VERSION "ICM"

NS_ :

BS_ :

BU_ : ICM Vector_XXX

BO_ 1977 DIAG_CFCAN_DTCInfo_FICM : 7 ICM
 SG_ DTCInfomationFICM : 7|56@0+ (1,0) [0|72057594037927935] "" Vector_XXX

BO_ 1976 DIAG_CFCAN_DTCInfo_IPK : 7 ICM
 SG_ DTCInfomationIPK : 7|56@0+ (1,0) [0|72057594037927935] "" Vector_XXX

BO_ 1897 Diag_CFCAN_PhyResp_FICM : 8 ICM
 SG_ Diag_CFCAN_PhyResp_ICM : 7|64@0+ (1,0) [0|0] "" Vector_XXX

BO_ 1547 DIAG_PhysResp_VKR : 8 ICM
 SG_ DiagnosticRespVKR : 7|64@0+ (1,0) [0|18446744073709551615] "" Vector_XXX

BO_ 929 FICM_CFCAN_FrP01 : 8 ICM
 SG_ ACDrvrTemV : 63|1@0+ (1,0) [0|1] "" Vector_XXX
 SG_ ACPsngTemV : 62|1@0+ (1,0) [0|1] "" Vector_XXX
 SG_ CBDActvdSpdSetng : 11|4@0+ (10.0,0.0) [30.0|100.0] "km/h" Vector_XXX
 SG_ CBDSelReq : 23|2@0+ (1,0) [0|3] "" Vector_XXX
 SG_ CIASelReq : 21|2@0+ (1,0) [0|3] "" Vector_XXX
 SG_ CIASetSwReq : 19|2@0+ (1,0) [0|3] "" Vector_XXX
 SG_ CLAWrnngSndSwSetng : 27|2@0+ (1,0) [0|3] "" Vector_XXX
 SG_ CLWActdSpdSetng : 31|4@0+ (10.0,0.0) [30.0|100.0] "km/h" Vector_XXX
 SG_ CLWSelReq : 17|2@0+ (1,0) [0|3] "" Vector_XXX
 SG_ FICMBrkLghtReqV : 59|1@0+ (1,0) [0|1] "" Vector_XXX
 SG_ FICMFLSeatVentSwReq : 51|2@0+ (1,0) [0|3] "" Vector_XXX
 SG_ FICMFRSeatVentSwReq : 49|2@0+ (1,0) [0|3] "" Vector_XXX
 SG_ LowSpdAutocOpenAVMReq : 33|2@0+ (1,0) [0|3] "" Vector_XXX
 SG_ RrViewInfoAstntActvdSpdSetng : 39|4@0+ (10.0,0.0) [30.0|100.0] "km/h" Vector_XXX
 SG_ RrViewInfoAstntDspSwReq : 25|2@0+ (1,0) [0|3] "" Vector_XXX
 SG_ RrViewInfoAstntSelReq : 35|2@0+ (1,0) [0|3] "" Vector_XXX
 SG_ VehBodyColorReq : 47|4@0+ (1,0) [0|15] "" Vector_XXX

BO_ 907 FICM_CFCAN_FrP02 : 8 ICM
 SG_ ACAirQultCtrlEnbSwReq : 7|2@0+ (1,0) [0|3] "" Vector_XXX
 SG_ ACEcoSwReq : 2|2@0+ (1,0) [0|3] "" Vector_XXX
 SG_ ACFltrCsumLvlRstSwReq : 15|2@0+ (1,0) [0|3] "" Vector_XXX
 SG_ ACFrtBlwrLvlReqV : 0|1@0+ (1,0) [0|1] "" Vector_XXX
 SG_ ACRrAirMdSwReq : 12|2@0+ (1,0) [0|3] "" Vector_XXX
 SG_ ACUserCustEcoSetngReq : 10|2@0+ (1,0) [0|3] "" Vector_XXX
 SG_ ACUserCustEcoSetngReqV : 8|1@0+ (1,0) [0|1] "" Vector_XXX
 SG_ FICMACAutoSwReq : 23|2@0+ (1,0) [0|3] "" Vector_XXX
 SG_ FICMACDualSwReq : 19|2@0+ (1,0) [0|3] "" Vector_XXX
 SG_ FICMACFreshSwReq : 33|2@0+ (1,0) [0|3] "" Vector_XXX
 SG_ FICMACFrtBlwrLvlReq : 39|4@0+ (1,0) [0|15] "" Vector_XXX
 SG_ FICMACFrtBlwrSpdDecSwR : 35|2@0+ (1,0) [0|3] "" Vector_XXX
 SG_ FICMACFrtBlwrSpdIncSwR : 47|2@0+ (1,0) [0|3] "" Vector_XXX
 SG_ FICMACFrtPnlLckRrPnlSwReq : 45|2@0+ (1,0) [0|3] "" Vector_XXX
 SG_ FICMACIonizerReqSwReq : 59|2@0+ (1,0) [0|3] "" Vector_XXX
 SG_ FICMACLAirMdReq : 26|3@0+ (1,0) [0|7] "" Vector_XXX
 SG_ FICMACLAirMdReqV : 41|1@0+ (1,0) [0|1] "" Vector_XXX
 SG_ FICMACLAirMdSwReq : 5|2@0+ (1,0) [0|3] "" Vector_XXX
 SG_ FICMACLTemDecSwReq : 17|2@0+ (1,0) [0|3] "" Vector_XXX
 SG_ FICMACLTemIncSwReq : 21|2@0+ (1,0) [0|3] "" Vector_XXX
 SG_ FICMACLTemReq : 31|5@0+ (0.5,17.5) [18.0|32.0] "degC" Vector_XXX
 SG_ FICMACLTemV : 3|1@0+ (1,0) [0|1] "" Vector_XXX
 SG_ FICMACOnOffSwReq : 54|2@0+ (1,0) [0|3] "" Vector_XXX
 SG_ FICMACRAirMdReq : 52|3@0+ (1,0) [0|7] "" Vector_XXX
 SG_ FICMACRAirMdReqV : 40|1@0+ (1,0) [0|1] "" Vector_XXX
 SG_ FICMACRAirMdSwReq : 49|2@0+ (1,0) [0|3] "" Vector_XXX
 SG_ FICMACRcctnSwReq : 57|2@0+ (1,0) [0|3] "" Vector_XXX
 SG_ FICMACRTemDecSwReq : 63|2@0+ (1,0) [0|3] "" Vector_XXX
 SG_ FICMACRTemIncSwReq : 61|2@0+ (1,0) [0|3] "" Vector_XXX
 SG_ FICMACSyncSwReq : 43|2@0+ (1,0) [0|3] "" Vector_XXX

BO_ 911 FICM_CFCAN_FrP03 : 8 ICM
 SG_ FICMACFrtPnlDspRrPnlSwReq : 47|2@0+ (1,0) [0|3] "" Vector_XXX
 SG_ FICMACRrAirMdReq : 2|3@0+ (1,0) [0|7] "" Vector_XXX
 SG_ FICMACRrAirMdReqV : 10|1@0+ (1,0) [0|1] "" Vector_XXX
 SG_ FICMACRrBlwrDecSwReq : 17|2@0+ (1,0) [0|3] "" Vector_XXX
 SG_ FICMACRrBlwrIncSwReq : 19|2@0+ (1,0) [0|3] "" Vector_XXX
 SG_ FICMACRrBlwrLvlReq : 31|4@0+ (1,0) [0|15] "" Vector_XXX
 SG_ FICMACRrBlwrLvlReqV : 9|1@0+ (1,0) [0|1] "" Vector_XXX
 SG_ FICMACRrTemDecSwReq : 27|2@0+ (1,0) [0|3] "" Vector_XXX
 SG_ FICMACRrTemIncSwReq : 25|2@0+ (1,0) [0|3] "" Vector_XXX
 SG_ FICMACRrTemReq : 15|5@0+ (0.5,17.5) [18.0|32.0] "degC" Vector_XXX
 SG_ FICMACRrTemV : 8|1@0+ (1,0) [0|1] "" Vector_XXX
 SG_ FICMACRTemReq : 7|5@0+ (0.5,17.5) [18.0|32.0] "degC" Vector_XXX
 SG_ FICMACRTemV : 40|1@0+ (1,0) [0|1] "" Vector_XXX
 SG_ FICMACTemUnitChngReq : 39|2@0+ (1,0) [0|3] "" Vector_XXX
 SG_ FICMClmOnOffSwReq : 37|2@0+ (1,0) [0|3] "" Vector_XXX
 SG_ FICMComprOnOffSwReq : 35|2@0+ (1,0) [0|3] "" Vector_XXX
 SG_ FICMDfstOnSwReq : 33|2@0+ (1,0) [0|3] "" Vector_XXX
 SG_ FICMRrACAutoSwReq : 23|2@0+ (1,0) [0|3] "" Vector_XXX
 SG_ FICMRrACOnOffSwReq : 21|2@0+ (1,0) [0|3] "" Vector_XXX
 SG_ PwrLftgtPosSetngReq : 63|7@0+ (0.787402,0.0) [0.0|100.000054] "%" Vector_XXX
 SG_ PwrLftgtPosSetngReqV : 48|1@0+ (1,0) [0|1] "" Vector_XXX
 SG_ PwrLftgtSysEnb : 56|1@0+ (1,0) [0|1] "" Vector_XXX
 SG_ StrgCDMSSetngReq : 55|7@0+ (1,0) [0|127] "" Vector_XXX
 SG_ StrgCDMSSetngReqV : 41|1@0+ (1,0) [0|1] "" Vector_XXX

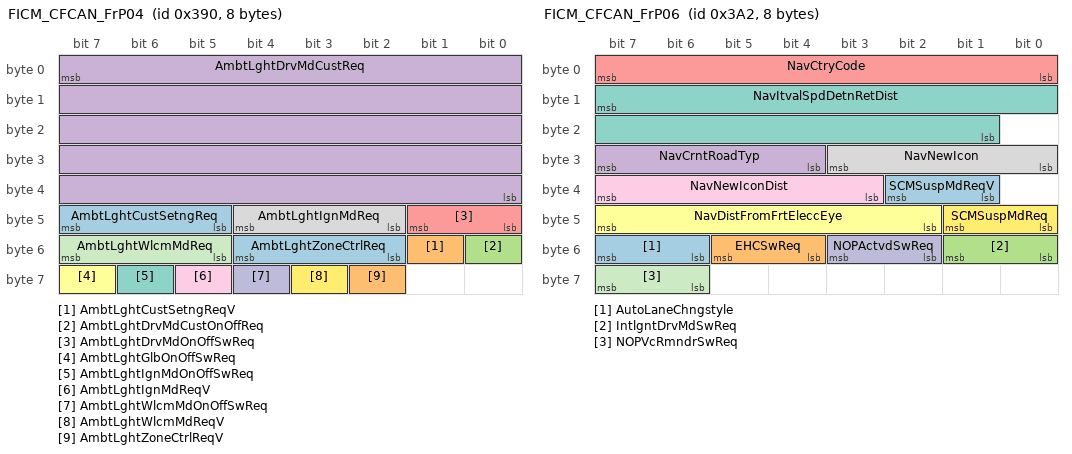
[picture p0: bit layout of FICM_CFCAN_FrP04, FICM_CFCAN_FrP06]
BO_ 912 FICM_CFCAN_FrP04 : 8 ICM
 SG_ AmbtLghtCustSetngReq : 47|3@0+ (1,0) [0|7] "" Vector_XXX
 SG_ AmbtLghtCustSetngReqV : 49|1@0+ (1,0) [0|1] "" Vector_XXX
 SG_ AmbtLghtDrvMdCustOnOffReq : 48|1@0+ (1,0) [0|1] "" Vector_XXX
 SG_ AmbtLghtDrvMdCustReq : 7|40@0+ (1,0) [0|1099511627775] "" Vector_XXX
 SG_ AmbtLghtDrvMdOnOffSwReq : 41|2@0+ (1,0) [0|3] "" Vector_XXX
 SG_ AmbtLghtGlbOnOffSwReq : 63|1@0+ (1,0) [0|1] "" Vector_XXX
 SG_ AmbtLghtIgnMdOnOffSwReq : 62|1@0+ (1,0) [0|1] "" Vector_XXX
 SG_ AmbtLghtIgnMdReq : 44|3@0+ (1,0) [0|7] "" Vector_XXX
 SG_ AmbtLghtIgnMdReqV : 61|1@0+ (1,0) [0|1] "" Vector_XXX
 SG_ AmbtLghtWlcmMdOnOffSwReq : 60|1@0+ (1,0) [0|1] "" Vector_XXX
 SG_ AmbtLghtWlcmMdReq : 55|3@0+ (1,0) [0|7] "" Vector_XXX
 SG_ AmbtLghtWlcmMdReqV : 59|1@0+ (1,0) [0|1] "" Vector_XXX
 SG_ AmbtLghtZoneCtrlReq : 52|3@0+ (1,0) [0|7] "" Vector_XXX
 SG_ AmbtLghtZoneCtrlReqV : 58|1@0+ (1,0) [0|1] "" Vector_XXX

BO_ 875 FICM_CFCAN_FrP05 : 8 ICM
 SG_ FaceIdficnAcutResult : 55|5@0+ (1,0) [0|31] "" Vector_XXX
 SG_ FICMDoorLckCtrlReq : 7|2@0+ (1,0) [0|3] "" Vector_XXX
 SG_ FICMDrvngMdSwReq : 50|3@0+ (1,0) [0|7] "" Vector_XXX
 SG_ FICMDrvngMdSwReqV : 43|1@0+ (1,0) [0|1] "" Vector_XXX
 SG_ FICMDrvrWndOpReq : 5|3@0+ (1,0) [0|7] "" Vector_XXX
 SG_ FICMFrtPsngWndOpReq : 2|3@0+ (1,0) [0|7] "" Vector_XXX
 SG_ FICMFrtWiperReq : 15|3@0+ (1,0) [0|7] "" Vector_XXX
 SG_ FICMFrtWshReq : 12|1@0+ (1,0) [0|1] "" Vector_XXX
 SG_ FICMHtdRrWndSwReq : 11|2@0+ (1,0) [0|3] "" Vector_XXX
 SG_ FICMKickSnsrLdspcEnbdReq : 9|2@0+ (1,0) [0|3] "" Vector_XXX
 SG_ FICMLdspcUnlckReq : 47|1@0+ (1,0) [0|1] "" Vector_XXX
 SG_ FICMOtsdMirFoldReq : 17|2@0+ (1,0) [0|3] "" Vector_XXX
 SG_ FICMRLWndOpReq : 23|3@0+ (1,0) [0|7] "" Vector_XXX
 SG_ FICMRrWiperReq : 39|2@0+ (1,0) [0|3] "" Vector_XXX
 SG_ FICMRRWndOpReq : 20|3@0+ (1,0) [0|7] "" Vector_XXX
 SG_ FICMRrWshReq : 46|1@0+ (1,0) [0|1] "" Vector_XXX
 SG_ FICMSrfSlidePosReq : 31|4@0+ (10.0,0.0) [0.0|150.0] "%" Vector_XXX
 SG_ FICMSrfTiltReq : 37|2@0+ (1,0) [0|3] "" Vector_XXX
 SG_ FICMSsdOpenPosReq : 27|4@0+ (10.0,0.0) [0.0|150.0] "%" Vector_XXX
 SG_ FICMVehStSpReq : 35|2@0+ (1,0) [0|3] "" Vector_XXX
 SG_ FICMVehStSpReqV : 45|1@0+ (1,0) [0|1] "" Vector_XXX
 SG_ FICMWiperOffReq : 44|1@0+ (1,0) [0|1] "" Vector_XXX
 SG_ FICMWiperSpdCtrlReq : 33|2@0+ (1,0) [0|3] "" Vector_XXX
 SG_ StorgMdSwReq : 63|2@0+ (1,0) [0|3] "" Vector_XXX
 SG_ WlcmFnCustSetngReq : 42|2@0+ (1,0) [0|3] "" Vector_XXX

BO_ 930 FICM_CFCAN_FrP06 : 8 ICM
 SG_ AutoLaneChngstyle : 55|2@0+ (1,0) [0|3] "" Vector_XXX
 SG_ EHCSwReq : 53|2@0+ (1,0) [0|3] "" Vector_XXX
 SG_ IntlgntDrvMdSwReq : 49|2@0+ (1,0) [0|3] "" Vector_XXX
 SG_ NavCrntRoadTyp : 31|4@0+ (1,0) [0|15] "" Vector_XXX
 SG_ NavCtryCode : 7|8@0+ (1.0,0.0) [0.0|255.0] "" Vector_XXX
 SG_ NavDistFromFrtEleccEye : 47|6@0+ (0.1,0.0) [0.1|6.0] "" Vector_XXX
 SG_ NavItvalSpdDetnRetDist : 15|15@0+ (0.1,0.0) [0.1|20.0] "" Vector_XXX
 SG_ NavNewIcon : 27|4@0+ (1,0) [0|15] "" Vector_XXX
 SG_ NavNewIconDist : 39|5@0+ (0.1,0.0) [0.1|2.0] "" Vector_XXX
 SG_ NOPActvdSwReq : 51|2@0+ (1,0) [0|3] "" Vector_XXX
 SG_ NOPVcRmndrSwReq : 63|2@0+ (1,0) [0|3] "" Vector_XXX
 SG_ SCMSuspMdReq : 41|2@0+ (1,0) [0|3] "" Vector_XXX
 SG_ SCMSuspMdReqV : 34|2@0+ (1,0) [0|3] "" Vector_XXX

BO_ 931 FICM_CFCAN_FrP07 : 8 ICM
 SG_ FICM_100ms_PDU07_CRC : 7|8@0+ (1.0,0.0) [0.0|255.0] "" Vector_XXX
 SG_ FICM_100ms_PDU07_RC : 11|4@0+ (1.0,0.0) [0.0|15.0] "" Vector_XXX
 SG_ FICM_100ms_PDU07_Reserve01 : 56|1@0+ (1,0) [0|1] "" Vector_XXX
 SG_ FICMEcoDrvngSwA : 39|1@0+ (1,0) [0|1] "" Vector_XXX
 SG_ FICMEcoDrvngSwAV : 38|1@0+ (1,0) [0|1] "" Vector_XXX
 SG_ FICMPosngSysDircn : 32|9@0+ (1.0,0.0) [0.0|511.0] "" Vector_XXX
 SG_ LDWLKASwReq : 29|3@0+ (1,0) [0|7] "" Vector_XXX
 SG_ NavSpdLmtTyp : 23|4@0+ (1,0) [0|15] "" Vector_XXX
 SG_ NavSpdLmtVal : 55|15@0+ (0.015625,0.0) [0.0|511.984375] "" Vector_XXX
 SG_ NavSpdLmtValSts : 19|2@0+ (1,0) [0|3] "" Vector_XXX
 SG_ NavSpdLmtValUnit : 17|2@0+ (1,0) [0|3] "" Vector_XXX
 SG_ PtCustSetngReq : 37|3@0+ (1,0) [0|7] "" Vector_XXX
 SG_ PtCustSetngReqV : 34|1@0+ (1,0) [0|1] "" Vector_XXX
 SG_ SpdAstMdFICM : 26|2@0+ (1,0) [0|3] "" Vector_XXX
 SG_ SpdAstMdFICMV : 24|1@0+ (1,0) [0|1] "" Vector_XXX
 SG_ StrgCustSetngReq : 31|2@0+ (1,0) [0|3] "" Vector_XXX
 SG_ StrgCustSetngReqV : 12|1@0+ (1,0) [0|1] "" Vector_XXX
 SG_ TrCustSetngReq : 15|3@0+ (1,0) [0|7] "" Vector_XXX
 SG_ TrCustSetngReqV : 33|1@0+ (1,0) [0|1] "" Vector_XXX

BO_ 902 FICM_CFCAN_FrP08 : 8 ICM
 SG_ BCMCofignUpdtInftn2 : 7|64@0+ (1,0) [0|18446744073709551615] "" Vector_XXX

BO_ 903 FICM_CFCAN_FrP09 : 8 ICM
 SG_ BCMCofignUpdtInftn3 : 7|64@0+ (1,0) [0|18446744073709551615] "" Vector_XXX

BO_ 913 FICM_CFCAN_FrP10 : 8 ICM
 SG_ ACUserCustSetngReq : 39|2@0+ (1,0) [0|3] "" Vector_XXX
 SG_ ACUserCustSetngReqV : 24|1@0+ (1,0) [0|1] "" Vector_XXX
 SG_ FICMACDrvrAirMdReq : 50|3@0+ (1,0) [0|7] "" Vector_XXX
 SG_ FICMACDrvrAirMdReqV : 40|1@0+ (1,0) [0|1] "" Vector_XXX
 SG_ FICMACDrvrTemReq : 55|5@0+ (1,0) [0|31] "" Vector_XXX
 SG_ FICMACPsngAirMdSwReq : 33|2@0+ (1,0) [0|3] "" Vector_XXX
 SG_ FICMACPsngTemReq : 47|5@0+ (1,0) [0|31] "" Vector_XXX
 SG_ FICMAirClnrBlwrLvlReq : 21|3@0+ (1,0) [0|7] "" Vector_XXX
 SG_ FICMAirClnrBlwrLvlReqV : 18|1@0+ (1,0) [0|1] "" Vector_XXX
 SG_ FICMAirClnrBlwrSpdDecSwReq : 17|2@0+ (1,0) [0|3] "" Vector_XXX
 SG_ FICMAirClnrBlwrSpdIncSwReq : 31|2@0+ (1,0) [0|3] "" Vector_XXX
 SG_ FICMASSInhSwA : 37|1@0+ (1,0) [0|1] "" Vector_XXX
 SG_ FICMASSInhV : 36|1@0+ (1,0) [0|1] "" Vector_XXX
 SG_ FICMBrkLghtReq : 7|2@0+ (1,0) [0|3] "" Vector_XXX
 SG_ FICMCotsyLghtReq : 5|2@0+ (1,0) [0|3] "" Vector_XXX
 SG_ FICMDipdBeamLghtReq : 3|2@0+ (1,0) [0|3] "" Vector_XXX
 SG_ FICMDipdBeamLghtReqV : 12|1@0+ (1,0) [0|1] "" Vector_XXX
 SG_ FICMDircnIndLghtReq : 15|3@0+ (1,0) [0|7] "" Vector_XXX
 SG_ FICMFLSeatHeatSwReq : 29|2@0+ (1,0) [0|3] "" Vector_XXX
 SG_ FICMFRSeatHeatSwReq : 27|2@0+ (1,0) [0|3] "" Vector_XXX
 SG_ FICMFrtFogLghtReq : 1|2@0+ (1,0) [0|3] "" Vector_XXX
 SG_ FICMMainBeamLghtReq : 11|2@0+ (1,0) [0|3] "" Vector_XXX
 SG_ FICMRevsLghtReq : 9|2@0+ (1,0) [0|3] "" Vector_XXX
 SG_ FICMRrFogLghtReq : 23|2@0+ (1,0) [0|3] "" Vector_XXX
 SG_ HDCReq : 35|2@0+ (1,0) [0|3] "" Vector_XXX
 SG_ RstrFctryDeftsReq : 25|1@0+ (1,0) [0|1] "" Vector_XXX

BO_ 1121 FICM_CFCAN_FrP11 : 8 ICM
 SG_ BCMCofignUpdtInftn : 7|64@0+ (1,0) [0|18446744073709551615] "" Vector_XXX

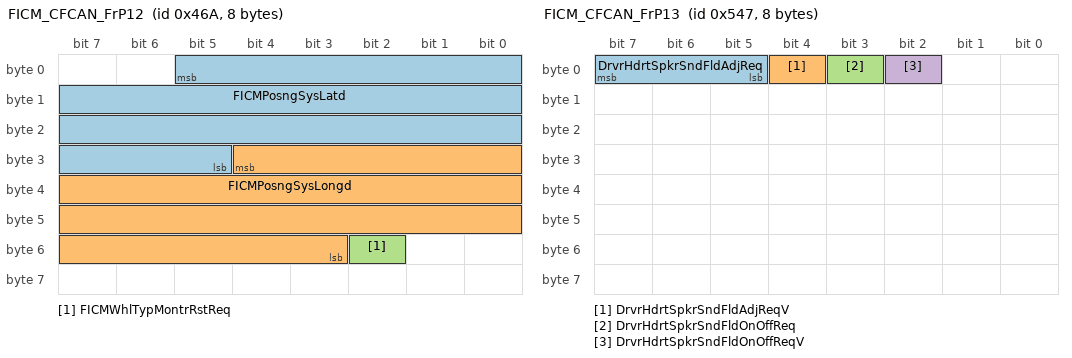
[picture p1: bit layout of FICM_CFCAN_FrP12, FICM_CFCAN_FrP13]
BO_ 1130 FICM_CFCAN_FrP12 : 8 ICM
 SG_ FICMPosngSysLatd : 5|25@0- (0.00001,0.0) [-90.00000000000001|90.00000000000001] "degree" Vector_XXX
 SG_ FICMPosngSysLongd : 28|26@0- (0.00001,0.0) [-335.54400000000004|335.54400000000004] "degree" Vector_XXX
 SG_ FICMWhlTypMontrRstReq : 50|1@0+ (1,0) [0|1] "" Vector_XXX

BO_ 1351 FICM_CFCAN_FrP13 : 8 ICM
 SG_ DrvrHdrtSpkrSndFldAdjReq : 7|3@0+ (1,0) [0|7] "" Vector_XXX
 SG_ DrvrHdrtSpkrSndFldAdjReqV : 4|1@0+ (1,0) [0|1] "" Vector_XXX
 SG_ DrvrHdrtSpkrSndFldOnOffReq : 3|1@0+ (1,0) [0|1] "" Vector_XXX
 SG_ DrvrHdrtSpkrSndFldOnOffReqV : 2|1@0+ (1,0) [0|1] "" Vector_XXX

BO_ 1352 FICM_CFCAN_FrP14 : 8 ICM
 SG_ NavSts : 7|3@0+ (1,0) [0|7] "" Vector_XXX

BO_ 820 FICM_CFCAN_FrP15 : 8 ICM
 SG_ ACUserCustAftRunOnOffR : 7|1@0+ (1,0) [0|1] "" Vector_XXX
 SG_ ACUserCustAftRunOnOffReqV : 6|1@0+ (1,0) [0|1] "" Vector_XXX
 SG_ ACUserCustAirQultEnbReq : 5|2@0+ (1,0) [0|3] "" Vector_XXX
 SG_ ACUserCustAirQultEnbReqV : 3|1@0+ (1,0) [0|1] "" Vector_XXX
 SG_ ACUserCustAutoMdBlwrReq : 2|2@0+ (1,0) [0|3] "" Vector_XXX
 SG_ ACUserCustAutoMdBlwrReqV : 0|1@0+ (1,0) [0|1] "" Vector_XXX
 SG_ ACUserCustAutoMdTemReq : 15|2@0+ (1,0) [0|3] "" Vector_XXX
 SG_ ACUserCustAutoMdTemReqV : 13|1@0+ (1,0) [0|1] "" Vector_XXX
 SG_ ACUserCustBlwrAutoRunRmtUnlckReq : 9|1@0+ (1,0) [0|1] "" Vector_XXX
 SG_ ACUserCustBlwrAutoRunRmtUnlckReqV : 10|1@0+ (1,0) [0|1] "" Vector_XXX
 SG_ ACUserCustCofignReq : 23|2@0+ (1,0) [0|3] "" Vector_XXX
 SG_ ACUserCustCofignReqV : 8|1@0+ (1,0) [0|1] "" Vector_XXX
 SG_ ACUserCustFltrLifeRmndReq : 21|1@0+ (1,0) [0|1] "" Vector_XXX
 SG_ ACUserCustFltrLifeRmndReqV : 20|1@0+ (1,0) [0|1] "" Vector_XXX
 SG_ ACUserCustFrtAutoDmstngReq : 19|1@0+ (1,0) [0|1] "" Vector_XXX
 SG_ ACUserCustFrtAutoDmstngReqV : 18|1@0+ (1,0) [0|1] "" Vector_XXX
 SG_ ACUserCustRmtStOnOffReq : 17|1@0+ (1,0) [0|1] "" Vector_XXX
 SG_ ACUserCustRmtStOnOffReqV : 16|1@0+ (1,0) [0|1] "" Vector_XXX
 SG_ ACUserCustRrAutoDmstngReq : 31|2@0+ (1,0) [0|3] "" Vector_XXX
 SG_ ACUserCustRrAutoDmstngReqV : 29|1@0+ (1,0) [0|1] "" Vector_XXX
 SG_ ACUserCustRrZoneCofignReq : 28|2@0+ (1,0) [0|3] "" Vector_XXX
 SG_ ACUserCustRrZoneCofignReqV : 26|1@0+ (1,0) [0|1] "" Vector_XXX
 SG_ ACUserCustStSpMdReq : 25|1@0+ (1,0) [0|1] "" Vector_XXX
 SG_ ACUserCustStSpMdReqV : 24|1@0+ (1,0) [0|1] "" Vector_XXX
 SG_ ACUserCustTemUnitReq : 39|1@0+ (1,0) [0|1] "" Vector_XXX
 SG_ ACUserCustTemUnitReqV : 38|1@0+ (1,0) [0|1] "" Vector_XXX
 SG_ ACUserCustZoneCofignReq : 37|2@0+ (1,0) [0|3] "" Vector_XXX
 SG_ ACUserCustZoneCofignReqV : 35|1@0+ (1,0) [0|1] "" Vector_XXX
 SG_ AirClnrUserCustAutoRR : 34|1@0+ (1,0) [0|1] "" Vector_XXX
 SG_ AirClnrUserCustAutoRRV : 33|1@0+ (1,0) [0|1] "" Vector_XXX
 SG_ FICMAirClnrAutoSwReq : 12|2@0+ (1,0) [0|3] "" Vector_XXX
 SG_ FICMAirClnrFltrCsumLvlRstSwReq : 47|2@0+ (1,0) [0|3] "" Vector_XXX
 SG_ FICMAirClnrIonizerSwR : 45|2@0+ (1,0) [0|3] "" Vector_XXX
 SG_ FICMAirClnrOnOffSwReq : 43|2@0+ (1,0) [0|3] "" Vector_XXX
 SG_ InsdAirPrtclMtrCncntrnSwReq : 41|2@0+ (1,0) [0|3] "" Vector_XXX

BO_ 690 FICM_CFCAN_FrP16 : 8 ICM
 SG_ AncptRoadSpdNav : 23|15@0+ (0.015625,0.0) [0.0|511.984375] "" Vector_XXX
 SG_ APASwReq : 33|2@0+ (1,0) [0|3] "" Vector_XXX
 SG_ AVMCalMdReq : 7|2@0+ (1,0) [0|3] "" Vector_XXX
 SG_ DistToTrgtNav : 39|6@0+ (9.375,-100.0) [-100.0|490.625] "m" Vector_XXX
 SG_ FICMCCSwCCA : 46|1@0+ (1,0) [0|1] "" Vector_XXX
 SG_ FICMCCSwCCAV : 45|1@0+ (1,0) [0|1] "" Vector_XXX
 SG_ FrtAndRrGudOvlyDspReq : 5|3@0+ (1,0) [0|7] "" Vector_XXX
 SG_ LOtsdMirSeldSwA : 42|1@0+ (1,0) [0|1] "" Vector_XXX
 SG_ OtsdMirFoldSwReq : 44|2@0+ (1,0) [0|3] "" Vector_XXX
 SG_ OtsdMirSWSFnA : 40|1@0+ (1,0) [0|1] "" Vector_XXX
 SG_ PDCSwReq : 2|2@0+ (1,0) [0|3] "" Vector_XXX
 SG_ PDCSysEnbReq : 0|1@0+ (1,0) [0|1] "" Vector_XXX
 SG_ PDCSysEnbReqV : 24|1@0+ (1,0) [0|1] "" Vector_XXX
 SG_ ROtsdMirSeldSwA : 41|1@0+ (1,0) [0|1] "" Vector_XXX
 SG_ SpdAstReqStsNav : 9|2@0+ (1,0) [0|3] "" Vector_XXX
 SG_ SurndViewSeln : 15|4@0+ (1,0) [0|15] "" Vector_XXX
 SG_ ThreeDimnlDspReq : 11|2@0+ (1,0) [0|3] "" Vector_XXX
 SG_ TrgtSpdReqNav : 55|15@0+ (0.015625,0.0) [0.0|511.984375] "" Vector_XXX

BO_ 895 FICM_CFCAN_FrP17 : 8 ICM
 SG_ ACCTJAMdSwReq : 23|3@0+ (1,0) [0|7] "" Vector_XXX
 SG_ AEBSwReq : 28|2@0+ (1,0) [0|3] "" Vector_XXX
 SG_ AutoLaneChngSwReq : 39|3@0+ (1,0) [0|7] "" Vector_XXX
 SG_ BSDSelReq : 5|2@0+ (1,0) [0|3] "" Vector_XXX
 SG_ DOWSelReq : 3|2@0+ (1,0) [0|3] "" Vector_XXX
 SG_ FCTSysSelReq : 50|2@0+ (1,0) [0|3] "" Vector_XXX
 SG_ FCWSnstvtLvlReq : 31|3@0+ (1,0) [0|7] "" Vector_XXX
 SG_ FCWSwReq : 13|2@0+ (1,0) [0|3] "" Vector_XXX
 SG_ FICMSCSMdReq : 26|2@0+ (1,0) [0|3] "" Vector_XXX
 SG_ LCASelReq : 11|2@0+ (1,0) [0|3] "" Vector_XXX
 SG_ LDWAdoWrnngReq : 45|2@0+ (1,0) [0|3] "" Vector_XXX
 SG_ LDWLKAHptWrnngReq : 1|2@0+ (1,0) [0|3] "" Vector_XXX
 SG_ LDWSnstvtLvlReq : 43|2@0+ (1,0) [0|3] "" Vector_XXX
 SG_ NOPSwReq : 63|3@0+ (1,0) [0|7] "" Vector_XXX
 SG_ RCTSysSelReq : 41|2@0+ (1,0) [0|3] "" Vector_XXX
 SG_ RCWSelReq : 19|2@0+ (1,0) [0|3] "" Vector_XXX
 SG_ RDASwReq : 9|2@0+ (1,0) [0|3] "" Vector_XXX
 SG_ SLIFWrnngStsReq : 47|1@0+ (1,0) [0|1] "" Vector_XXX
 SG_ SLIFWrnngStsReqV : 46|1@0+ (1,0) [0|1] "" Vector_XXX
 SG_ TJAICASwReq : 17|2@0+ (1,0) [0|3] "" Vector_XXX

BO_ 1347 FICM_CFCAN_FrP18 : 8 ICM
 SG_ LanggSetngAdj : 55|7@0+ (1,0) [0|127] "" Vector_XXX

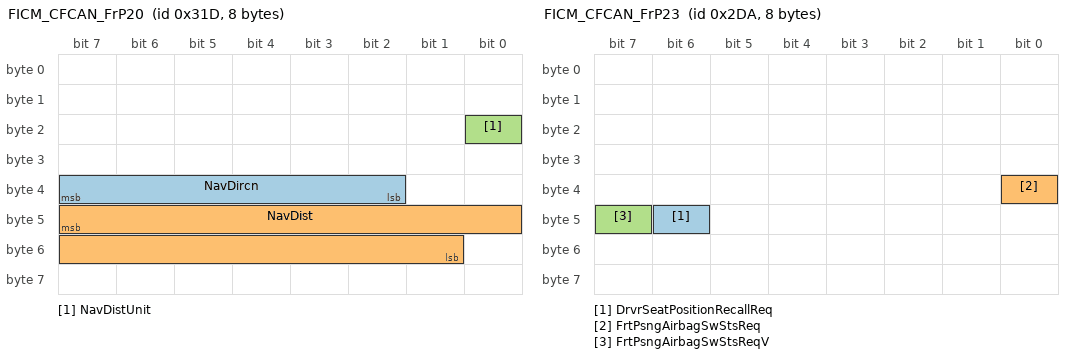
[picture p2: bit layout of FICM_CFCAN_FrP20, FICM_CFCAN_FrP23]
BO_ 797 FICM_CFCAN_FrP20 : 8 ICM
 SG_ NavDircn : 39|6@0+ (1,0) [0|63] "" Vector_XXX
 SG_ NavDist : 47|15@0+ (1.0,0.0) [0.0|32766.0] "" Vector_XXX
 SG_ NavDistUnit : 16|1@0+ (1,0) [0|1] "" Vector_XXX

BO_ 730 FICM_CFCAN_FrP23 : 8 ICM
 SG_ DrvrSeatPositionRecallReq : 46|1@0+ (1,0) [0|1] "" Vector_XXX
 SG_ FrtPsngAirbagSwStsReq : 32|1@0+ (1,0) [0|1] "" Vector_XXX
 SG_ FrtPsngAirbagSwStsReqV : 47|1@0+ (1,0) [0|1] "" Vector_XXX

BO_ 767 FICM_CFCAN_FrP28 : 8 ICM
 SG_ AVMDspReqResp : 37|2@0+ (1,0) [0|3] "" Vector_XXX
 SG_ AVMDspSwReq : 35|2@0+ (1,0) [0|3] "" Vector_XXX
 SG_ BleCmftLckSet : 33|2@0+ (1,0) [0|3] "" Vector_XXX
 SG_ BleCmftUnlckSet : 31|2@0+ (1,0) [0|3] "" Vector_XXX
 SG_ BleWlcmFnSet : 29|2@0+ (1,0) [0|3] "" Vector_XXX
 SG_ CCDisAdjtVcCmd : 63|3@0+ (1,0) [0|7] "" Vector_XXX
 SG_ CCDisDecAndIncVcCmd : 60|2@0+ (1,0) [0|3] "" Vector_XXX
 SG_ CCSpdDecAndIncVcCmd : 58|2@0+ (1,0) [0|3] "" Vector_XXX
 SG_ CCSpdVcCmd : 55|8@0+ (1.0,0.0) [0.0|255.0] "" Vector_XXX
 SG_ CCSpdVcCmdSwReq : 47|2@0+ (1,0) [0|3] "" Vector_XXX
 SG_ DMSAdoWrnngReq : 23|2@0+ (1,0) [0|3] "" Vector_XXX
 SG_ DMSHapticWrnngReq : 21|2@0+ (1,0) [0|3] "" Vector_XXX
 SG_ DMSSwReq : 19|2@0+ (1,0) [0|3] "" Vector_XXX
 SG_ DrvrVcCmdADASCtrlReq : 7|3@0+ (1,0) [0|7] "" Vector_XXX
 SG_ ILCSwReq : 45|2@0+ (1,0) [0|3] "" Vector_XXX
 SG_ PhnKeyCphrUpdt : 27|2@0+ (1,0) [0|3] "" Vector_XXX
 SG_ PhnKeyRst : 25|2@0+ (1,0) [0|3] "" Vector_XXX
 SG_ SmtKeyCmftLckSet : 43|2@0+ (1,0) [0|3] "" Vector_XXX
 SG_ SmtKeyCmftUnlckSet : 41|2@0+ (1,0) [0|3] "" Vector_XXX
 SG_ SmtKeyWlcmFnSet : 39|2@0+ (1,0) [0|3] "" Vector_XXX

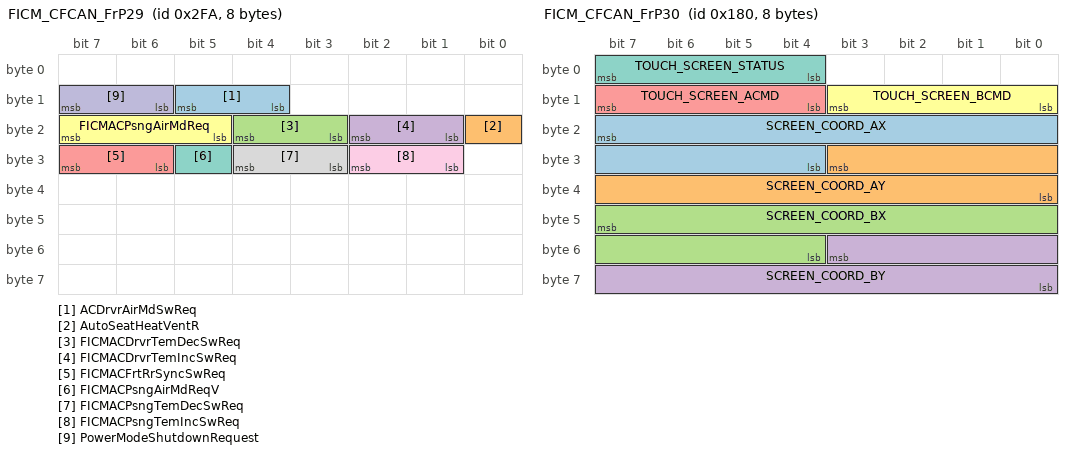
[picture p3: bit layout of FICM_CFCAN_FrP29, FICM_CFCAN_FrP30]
BO_ 762 FICM_CFCAN_FrP29 : 8 ICM
 SG_ ACDrvrAirMdSwReq : 13|2@0+ (1,0) [0|3] "" Vector_XXX
 SG_ AutoSeatHeatVentR : 16|1@0+ (1,0) [0|1] "" Vector_XXX
 SG_ FICMACDrvrTemDecSwReq : 20|2@0+ (1,0) [0|3] "" Vector_XXX
 SG_ FICMACDrvrTemIncSwReq : 18|2@0+ (1,0) [0|3] "" Vector_XXX
 SG_ FICMACFrtRrSyncSwReq : 31|2@0+ (1,0) [0|3] "" Vector_XXX
 SG_ FICMACPsngAirMdReq : 23|3@0+ (1,0) [0|7] "" Vector_XXX
 SG_ FICMACPsngAirMdReqV : 29|1@0+ (1,0) [0|1] "" Vector_XXX
 SG_ FICMACPsngTemDecSwReq : 28|2@0+ (1,0) [0|3] "" Vector_XXX
 SG_ FICMACPsngTemIncSwReq : 26|2@0+ (1,0) [0|3] "" Vector_XXX
 SG_ PowerModeShutdownRequest : 15|2@0+ (1,0) [0|3] "" Vector_XXX

BO_ 384 FICM_CFCAN_FrP30 : 8 ICM
 SG_ SCREEN_COORD_AX : 23|12@0+ (1,0) [0|4095] "" Vector_XXX
 SG_ SCREEN_COORD_AY : 27|12@0+ (1,0) [0|4095] "" Vector_XXX
 SG_ SCREEN_COORD_BX : 47|12@0+ (1,0) [0|4095] "" Vector_XXX
 SG_ SCREEN_COORD_BY : 51|12@0+ (1,0) [0|4095] "" Vector_XXX
 SG_ TOUCH_SCREEN_ACMD : 15|4@0+ (1,0) [0|15] "" Vector_XXX
 SG_ TOUCH_SCREEN_BCMD : 11|4@0+ (1,0) [0|15] "" Vector_XXX
 SG_ TOUCH_SCREEN_STATUS : 7|4@0+ (1,0) [0|15] "" Vector_XXX

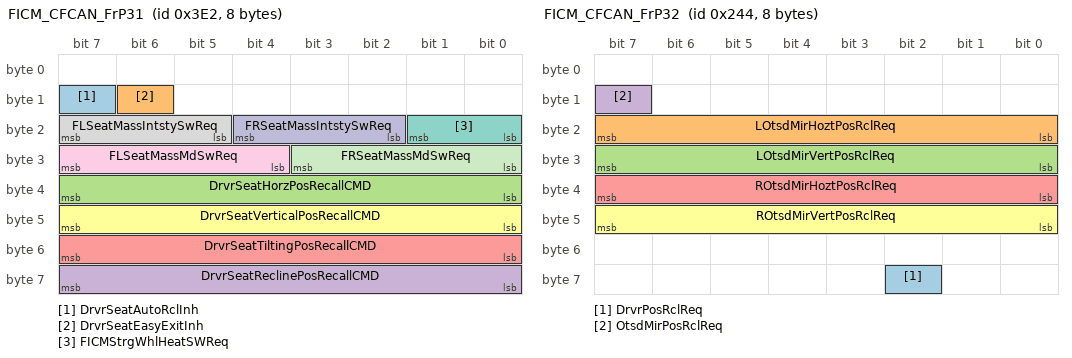
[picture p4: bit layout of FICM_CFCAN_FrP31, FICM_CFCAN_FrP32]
BO_ 994 FICM_CFCAN_FrP31 : 8 ICM
 SG_ DrvrSeatAutoRclInh : 15|1@0+ (1,0) [0|1] "" Vector_XXX
 SG_ DrvrSeatEasyExitInh : 14|1@0+ (1,0) [0|1] "" Vector_XXX
 SG_ DrvrSeatHorzPosRecallCMD : 39|8@0+ (1.0,0.0) [0.0|100.0] "%;" Vector_XXX
 SG_ DrvrSeatReclinePosRecallCMD : 63|8@0+ (1.0,0.0) [0.0|100.0] "%;" Vector_XXX
 SG_ DrvrSeatTiltingPosRecallCMD : 55|8@0+ (1.0,0.0) [0.0|100.0] "%;" Vector_XXX
 SG_ DrvrSeatVerticalPosRecallCMD : 47|8@0+ (1.0,0.0) [0.0|100.0] "%;" Vector_XXX
 SG_ FICMStrgWhlHeatSWReq : 17|2@0+ (1,0) [0|3] "" Vector_XXX
 SG_ FLSeatMassIntstySwReq : 23|3@0+ (1,0) [0|7] "" Vector_XXX
 SG_ FLSeatMassMdSwReq : 31|4@0+ (1,0) [0|15] "" Vector_XXX
 SG_ FRSeatMassIntstySwReq : 20|3@0+ (1,0) [0|7] "" Vector_XXX
 SG_ FRSeatMassMdSwReq : 27|4@0+ (1,0) [0|15] "" Vector_XXX

BO_ 580 FICM_CFCAN_FrP32 : 8 ICM
 SG_ DrvrPosRclReq : 58|1@0+ (1,0) [0|1] "" Vector_XXX
 SG_ LOtsdMirHoztPosRclReq : 23|8@0+ (1.0,0.0) [0.0|255.0] "" Vector_XXX
 SG_ LOtsdMirVertPosRclReq : 31|8@0+ (1.0,0.0) [0.0|255.0] "" Vector_XXX
 SG_ OtsdMirPosRclReq : 15|1@0+ (1,0) [0|1] "" Vector_XXX
 SG_ ROtsdMirHoztPosRclReq : 39|8@0+ (1.0,0.0) [0.0|255.0] "" Vector_XXX
 SG_ ROtsdMirVertPosRclReq : 47|8@0+ (1.0,0.0) [0.0|255.0] "" Vector_XXX

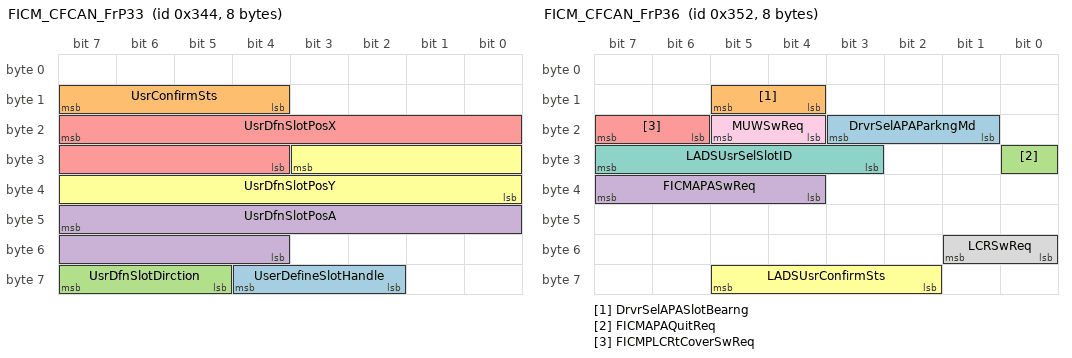
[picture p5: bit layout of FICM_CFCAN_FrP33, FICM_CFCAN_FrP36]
BO_ 836 FICM_CFCAN_FrP33 : 8 ICM
 SG_ UserDefineSlotHandle : 60|3@0+ (1,0) [0|7] "" Vector_XXX
 SG_ UsrConfirmSts : 15|4@0+ (1,0) [0|15] "" Vector_XXX
 SG_ UsrDfnSlotDirction : 63|3@0+ (1,0) [0|7] "" Vector_XXX
 SG_ UsrDfnSlotPosA : 47|12@0+ (1.0,0.0) [0.0|4095.0] "" Vector_XXX
 SG_ UsrDfnSlotPosX : 23|12@0+ (1.0,0.0) [0.0|4095.0] "" Vector_XXX
 SG_ UsrDfnSlotPosY : 27|12@0+ (1.0,0.0) [0.0|4095.0] "" Vector_XXX

BO_ 603 FICM_CFCAN_FrP35 : 8 ICM
 SG_ ActiveAPAReq : 31|3@0+ (1,0) [0|7] "" Vector_XXX
 SG_ Alisysrdy : 12|1@0+ (1,0) [0|1] "" Vector_XXX
 SG_ AVMDrvnSwReq : 43|2@0+ (1,0) [0|3] "" Vector_XXX
 SG_ AVMDspReqRespSts : 54|3@0+ (1,0) [0|7] "" Vector_XXX
 SG_ BrightnessAdjsmt : 41|2@0+ (1,0) [0|3] "" Vector_XXX
 SG_ BrightnessBar : 51|4@0+ (1,0) [0|15] "" Vector_XXX
 SG_ ContrastRatioAdjsmt : 59|2@0+ (1,0) [0|3] "" Vector_XXX
 SG_ ContrastRatioBar : 63|4@0+ (1,0) [0|15] "" Vector_XXX
 SG_ DynmcDrvngTrjctryLnSwReq : 35|2@0+ (1,0) [0|3] "" Vector_XXX
 SG_ FICMPwrLftgtSwReq : 57|1@0+ (1,0) [0|1] "" Vector_XXX
 SG_ FrtTmDrvAutVwSwReq : 37|2@0+ (1,0) [0|3] "" Vector_XXX
 SG_ HigSpd3DVwSwReq : 33|2@0+ (1,0) [0|3] "" Vector_XXX
 SG_ IParkingSw : 55|1@0+ (1,0) [0|1] "" Vector_XXX
 SG_ ObstclAutVwSwReq : 39|2@0+ (1,0) [0|3] "" Vector_XXX
 SG_ ObstclMarkSwReq : 47|2@0+ (1,0) [0|3] "" Vector_XXX
 SG_ PwrlgftFICMCmd : 11|2@0+ (1,0) [0|3] "" Vector_XXX
 SG_ SlientSearchNotifySwReq : 45|2@0+ (1,0) [0|3] "" Vector_XXX
 SG_ TurnngAutVwSwReq : 25|2@0+ (1,0) [0|3] "" Vector_XXX
 SG_ UsrDfnSw : 28|3@0+ (1,0) [0|7] "" Vector_XXX

BO_ 850 FICM_CFCAN_FrP36 : 8 ICM
 SG_ DrvrSelAPAParkngMd : 19|3@0+ (1,0) [0|7] "" Vector_XXX
 SG_ DrvrSelAPASlotBearng : 13|2@0+ (1,0) [0|3] "" Vector_XXX
 SG_ FICMAPAQuitReq : 24|1@0+ (1,0) [0|1] "" Vector_XXX
 SG_ FICMAPASwReq : 39|4@0+ (1,0) [0|15] "" Vector_XXX
 SG_ FICMPLCRtCoverSwReq : 23|2@0+ (1,0) [0|3] "" Vector_XXX
 SG_ LADSUsrConfirmSts : 61|4@0+ (1,0) [0|15] "" Vector_XXX
 SG_ LADSUsrSelSlotID : 31|5@0+ (1.0,0.0) [0.0|31.0] "" Vector_XXX
 SG_ LCRSwReq : 49|2@0+ (1,0) [0|3] "" Vector_XXX
 SG_ MUWSwReq : 21|2@0+ (1,0) [0|3] "" Vector_XXX

BO_ 833 FICM_CFCAN_FrP42 : 8 ICM
 SG_ ClstrDspdEnSpd : 55|16@0+ (1.0,0.0) [0.0|65535.0] "rpm" Vector_XXX
 SG_ ClstrDspdGear : 15|4@0+ (1,0) [0|15] "" Vector_XXX

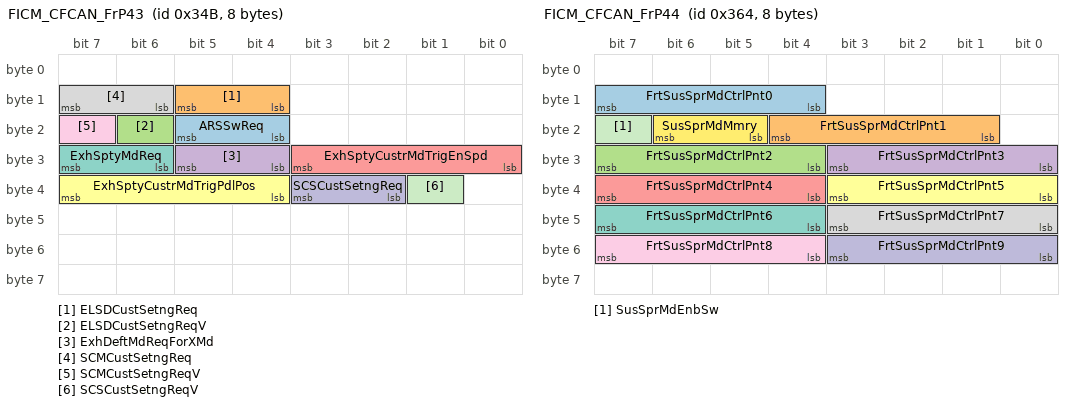
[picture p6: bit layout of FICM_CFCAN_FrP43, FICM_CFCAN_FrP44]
BO_ 843 FICM_CFCAN_FrP43 : 8 ICM
 SG_ ARSSwReq : 21|2@0+ (1,0) [0|3] "" Vector_XXX
 SG_ ELSDCustSetngReq : 13|2@0+ (1,0) [0|3] "" Vector_XXX
 SG_ ELSDCustSetngReqV : 22|1@0+ (1,0) [0|1] "" Vector_XXX
 SG_ ExhDeftMdReqForXMd : 29|2@0+ (1,0) [0|3] "" Vector_XXX
 SG_ ExhSptyCustrMdTrigEnSpd : 27|4@0+ (1,0) [0|15] "" Vector_XXX
 SG_ ExhSptyCustrMdTrigPdlPos : 39|4@0+ (1,0) [0|15] "" Vector_XXX
 SG_ ExhSptyMdReq : 31|2@0+ (1,0) [0|3] "" Vector_XXX
 SG_ SCMCustSetngReq : 15|2@0+ (1,0) [0|3] "" Vector_XXX
 SG_ SCMCustSetngReqV : 23|1@0+ (1,0) [0|1] "" Vector_XXX
 SG_ SCSCustSetngReq : 35|2@0+ (1,0) [0|3] "" Vector_XXX
 SG_ SCSCustSetngReqV : 33|1@0+ (1,0) [0|1] "" Vector_XXX

BO_ 868 FICM_CFCAN_FrP44 : 8 ICM
 SG_ FrtSusSprMdCtrlPnt0 : 15|4@0+ (1.0,0.0) [0.0|15.0] "" Vector_XXX
 SG_ FrtSusSprMdCtrlPnt1 : 20|4@0+ (1.0,0.0) [0.0|15.0] "" Vector_XXX
 SG_ FrtSusSprMdCtrlPnt2 : 31|4@0+ (1.0,0.0) [0.0|15.0] "" Vector_XXX
 SG_ FrtSusSprMdCtrlPnt3 : 27|4@0+ (1.0,0.0) [0.0|15.0] "" Vector_XXX
 SG_ FrtSusSprMdCtrlPnt4 : 39|4@0+ (1.0,0.0) [0.0|15.0] "" Vector_XXX
 SG_ FrtSusSprMdCtrlPnt5 : 35|4@0+ (1.0,0.0) [0.0|15.0] "" Vector_XXX
 SG_ FrtSusSprMdCtrlPnt6 : 47|4@0+ (1.0,0.0) [0.0|15.0] "" Vector_XXX
 SG_ FrtSusSprMdCtrlPnt7 : 43|4@0+ (1.0,0.0) [0.0|15.0] "" Vector_XXX
 SG_ FrtSusSprMdCtrlPnt8 : 55|4@0+ (1.0,0.0) [0.0|15.0] "" Vector_XXX
 SG_ FrtSusSprMdCtrlPnt9 : 51|4@0+ (1.0,0.0) [0.0|15.0] "" Vector_XXX
 SG_ SusSprMdEnbSw : 23|1@0+ (1,0) [0|1] "" Vector_XXX
 SG_ SusSprMdMmry : 22|2@0+ (1,0) [0|3] "" Vector_XXX

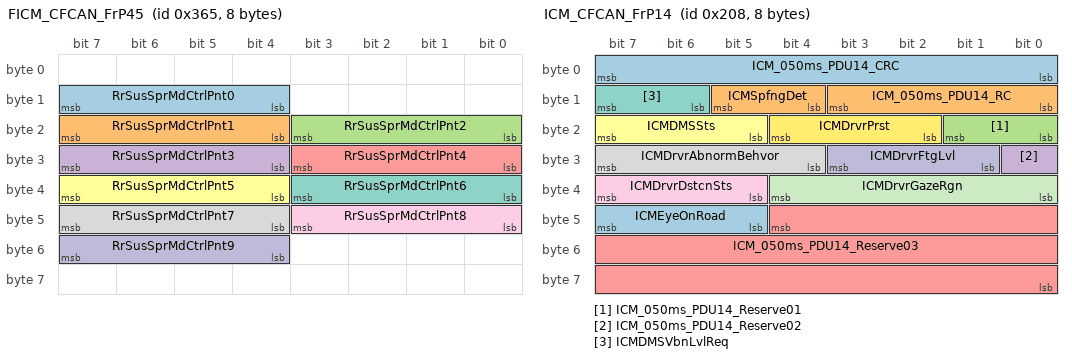
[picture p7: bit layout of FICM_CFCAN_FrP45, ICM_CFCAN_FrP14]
BO_ 869 FICM_CFCAN_FrP45 : 8 ICM
 SG_ RrSusSprMdCtrlPnt0 : 15|4@0+ (1.0,0.0) [0.0|15.0] "" Vector_XXX
 SG_ RrSusSprMdCtrlPnt1 : 23|4@0+ (1.0,0.0) [0.0|15.0] "" Vector_XXX
 SG_ RrSusSprMdCtrlPnt2 : 19|4@0+ (1.0,0.0) [0.0|15.0] "" Vector_XXX
 SG_ RrSusSprMdCtrlPnt3 : 31|4@0+ (1.0,0.0) [0.0|15.0] "" Vector_XXX
 SG_ RrSusSprMdCtrlPnt4 : 27|4@0+ (1.0,0.0) [0.0|15.0] "" Vector_XXX
 SG_ RrSusSprMdCtrlPnt5 : 39|4@0+ (1.0,0.0) [0.0|15.0] "" Vector_XXX
 SG_ RrSusSprMdCtrlPnt6 : 35|4@0+ (1.0,0.0) [0.0|15.0] "" Vector_XXX
 SG_ RrSusSprMdCtrlPnt7 : 47|4@0+ (1.0,0.0) [0.0|15.0] "" Vector_XXX
 SG_ RrSusSprMdCtrlPnt8 : 43|4@0+ (1.0,0.0) [0.0|15.0] "" Vector_XXX
 SG_ RrSusSprMdCtrlPnt9 : 55|4@0+ (1.0,0.0) [0.0|15.0] "" Vector_XXX

BO_ 1667 FICM_CFCAN_FrS25 : 8 ICM
 SG_ EvtPotclSigFICM : 7|64@0+ (1,0) [0|18446744073709551615] "" Vector_XXX

BO_ 520 ICM_CFCAN_FrP14 : 8 ICM
 SG_ ICM_050ms_PDU14_CRC : 7|8@0+ (1.0,0.0) [0.0|255.0] "" Vector_XXX
 SG_ ICM_050ms_PDU14_RC : 11|4@0+ (1.0,0.0) [0.0|15.0] "" Vector_XXX
 SG_ ICM_050ms_PDU14_Reserve01 : 17|2@0+ (1,0) [0|3] "" Vector_XXX
 SG_ ICM_050ms_PDU14_Reserve02 : 24|1@0+ (1,0) [0|1] "" Vector_XXX
 SG_ ICM_050ms_PDU14_Reserve03 : 44|21@0+ (1,0) [0|2097151] "" Vector_XXX
 SG_ ICMDMSSts : 23|3@0+ (1,0) [0|7] "" Vector_XXX
 SG_ ICMDMSVbnLvlReq : 15|2@0+ (1,0) [0|3] "" Vector_XXX
 SG_ ICMDrvrAbnormBehvor : 31|4@0+ (1,0) [0|15] "" Vector_XXX
 SG_ ICMDrvrDstcnSts : 39|3@0+ (1,0) [0|7] "" Vector_XXX
 SG_ ICMDrvrFtgLvl : 27|3@0+ (1,0) [0|7] "" Vector_XXX
 SG_ ICMDrvrGazeRgn : 36|5@0+ (1,0) [0|31] "" Vector_XXX
 SG_ ICMDrvrPrst : 20|3@0+ (1,0) [0|7] "" Vector_XXX
 SG_ ICMEyeOnRoad : 47|3@0+ (1,0) [0|7] "" Vector_XXX
 SG_ ICMSpfngDet : 13|2@0+ (1,0) [0|3] "" Vector_XXX

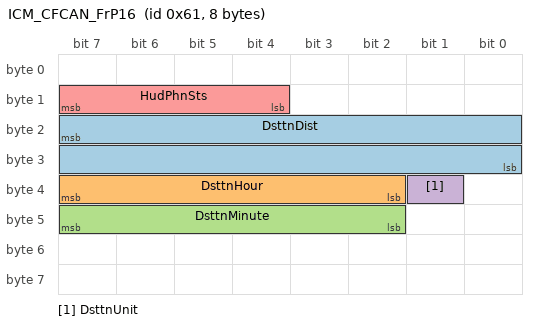
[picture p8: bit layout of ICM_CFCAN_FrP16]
BO_ 97 ICM_CFCAN_FrP16 : 8 ICM
 SG_ DsttnDist : 23|16@0+ (1.0,0.0) [0.0|65534.0] "" Vector_XXX
 SG_ DsttnHour : 39|6@0+ (1.0,0.0) [0.0|62.0] "" Vector_XXX
 SG_ DsttnMinute : 47|6@0+ (1.0,0.0) [0.0|59.0] "" Vector_XXX
 SG_ DsttnUnit : 33|1@0+ (1,0) [0|1] "" Vector_XXX
 SG_ HudPhnSts : 15|4@0+ (1,0) [0|15] "" Vector_XXX

BO_ 79 ICM_CFCAN_FrS04 : 8 ICM
 SG_ AmbcSetngReq : 2|3@0+ (1,0) [0|7] "" Vector_XXX
 SG_ AmbcSetngReqV : 55|1@0+ (1,0) [0|1] "" Vector_XXX
 SG_ BalcSetngReq : 47|4@0+ (1,0) [0|15] "" Vector_XXX
 SG_ BalcSetngReqV : 41|1@0+ (1,0) [0|1] "" Vector_XXX
 SG_ ChmA : 4|1@0+ (1,0) [0|1] "" Vector_XXX
 SG_ ChmSndVolmStepReq : 39|4@0+ (1,0) [0|15] "" Vector_XXX
 SG_ ChmSndVolmStepReqV : 43|1@0+ (1,0) [0|1] "" Vector_XXX
 SG_ FdrSetngReq : 35|4@0+ (1,0) [0|15] "" Vector_XXX
 SG_ FdrSetngReqV : 40|1@0+ (1,0) [0|1] "" Vector_XXX
 SG_ MdaSndVolmStepReq : 53|6@0+ (1,0) [0|63] "" Vector_XXX
 SG_ MdaSndVolmStepReqV : 3|1@0+ (1,0) [0|1] "" Vector_XXX
 SG_ NavSndVolmStepReq : 15|5@0+ (1,0) [0|31] "" Vector_XXX
 SG_ NavSndVolmStepReqV : 26|1@0+ (1,0) [0|1] "" Vector_XXX
 SG_ PhnCallSndVolmStepReq : 23|6@0+ (1,0) [0|63] "" Vector_XXX
 SG_ PhnCallSndVolmStepReqV : 25|1@0+ (1,0) [0|1] "" Vector_XXX
 SG_ SpdDpntAutocVolmReq : 17|2@0+ (1,0) [0|3] "" Vector_XXX
 SG_ SpdDpntAutocVolmReqV : 42|1@0+ (1,0) [0|1] "" Vector_XXX
 SG_ ThreeDimnSndFldSetngReq : 10|3@0+ (1,0) [0|7] "" Vector_XXX
 SG_ ThreeDimnSndFldSetngReqV : 54|1@0+ (1,0) [0|1] "" Vector_XXX
 SG_ VcItatnSndVolmStepReq : 31|5@0+ (1,0) [0|31] "" Vector_XXX
 SG_ VcItatnSndVolmStepReqV : 24|1@0+ (1,0) [0|1] "" Vector_XXX

BO_ 48 ICM_CFCAN_FrS05 : 8 ICM
 SG_ AllMuteReq : 11|1@0+ (1,0) [0|1] "" Vector_XXX
 SG_ AMPASndWaveSelReq : 34|3@0+ (1,0) [0|7] "" Vector_XXX
 SG_ AMPASndWaveSelReqV : 47|1@0+ (1,0) [0|1] "" Vector_XXX
 SG_ AMPASndWaveSwReq : 25|1@0+ (1,0) [0|1] "" Vector_XXX
 SG_ AMPASndWaveSwReqV : 24|1@0+ (1,0) [0|1] "" Vector_XXX
 SG_ AMPASndWaveVolmSwReq : 39|4@0+ (1,0) [0|15] "" Vector_XXX
 SG_ AMPASndWaveVolmSwReqV : 35|1@0+ (1,0) [0|1] "" Vector_XXX
 SG_ ANCOnOffReq : 63|1@0+ (1,0) [0|1] "" Vector_XXX
 SG_ ANCOnOffReqV : 62|1@0+ (1,0) [0|1] "" Vector_XXX
 SG_ BassReq : 23|4@0+ (1,0) [0|15] "" Vector_XXX
 SG_ BassReqV : 14|1@0+ (1,0) [0|1] "" Vector_XXX
 SG_ CmprdSndQultRstrnReq : 9|1@0+ (1,0) [0|1] "" Vector_XXX
 SG_ ICMChmCmdSndLoctnFL : 48|1@0+ (1,0) [0|1] "" Vector_XXX
 SG_ ICMChmCmdSndLoctnFR : 49|1@0+ (1,0) [0|1] "" Vector_XXX
 SG_ ICMChmCmdSndLoctnRL : 50|1@0+ (1,0) [0|1] "" Vector_XXX
 SG_ ICMChmCmdSndLoctnRR : 51|1@0+ (1,0) [0|1] "" Vector_XXX
 SG_ LdnsSetngSoftSw : 27|1@0+ (1,0) [0|1] "" Vector_XXX
 SG_ MdaA : 42|1@0+ (1,0) [0|1] "" Vector_XXX
 SG_ MdaMuteReq : 26|1@0+ (1,0) [0|1] "" Vector_XXX
 SG_ MedReq : 19|4@0+ (1,0) [0|15] "" Vector_XXX
 SG_ MedReqV : 13|1@0+ (1,0) [0|1] "" Vector_XXX
 SG_ NavA : 41|1@0+ (1,0) [0|1] "" Vector_XXX
 SG_ NotfnA : 40|1@0+ (1,0) [0|1] "" Vector_XXX
 SG_ PhnA : 52|1@0+ (1,0) [0|1] "" Vector_XXX
 SG_ TelphoComLoctn : 45|3@0+ (1,0) [0|7] "" Vector_XXX
 SG_ TrblReq : 31|4@0+ (1,0) [0|15] "" Vector_XXX
 SG_ TrblReqV : 12|1@0+ (1,0) [0|1] "" Vector_XXX
 SG_ VcItatnA : 46|1@0+ (1,0) [0|1] "" Vector_XXX
 SG_ VcItatnSndLoctn : 55|3@0+ (1,0) [0|7] "" Vector_XXX

BO_ 1566 ICM_CFCAN_FrS06 : 8 ICM
 SG_ EvtPotclSigICM : 7|64@0+ (1,0) [0|18446744073709551615] "" Vector_XXX

// Signal Comments
CM_ SG_ 1977 DTCInfomationFICM "DTC Infomation of FICM

The length of DTC information signal is 7 bytes.
Byte 0 is MSB (most significant byte), and Byte 6 is LSB (least significant byte).
For each byte, Bit 7 is msb (most significant bit), and Bit 0 is lsb (least significant bit).

Byte 0:
Bit (7-4): DTC Serious Level
Bit (3-0): Reserved

Byte 1:
Bit (7-0): Reserved

Byte 2:
Bit (7-0): DTCHighByte

Byte 3:
Bit (7-0): DTCLowByte

Byte 4:
Bit (7-0): DTCFailureTypeByte

Byte 5:
Bit 7: warningIndicatorRequested
Bit 6: testNotCompletedThisOperationCycle
Bit 5: testFailedSinceLastClear
Bit 4: testNotCompletedSinceLastClear
Bit 3: confirmedDTC
Bit 2: pendingDTC
Bit 1: testFailedThisOperationCycle
Bit 0: testFailed

Byte 6:
Bit (7-0): DTC Type

For more detail, please refer to SMTC 2 800 004.
";
CM_ SG_ 1976 DTCInfomationIPK "DTC Infomation of IPK

The length of DTC information signal is 7 bytes.
Byte 0 is MSB (most significant byte), and Byte 6 is LSB (least significant byte).
For each byte, Bit 7 is msb (most significant bit), and Bit 0 is lsb (least significant bit).

Byte 0:
Bit (7-4): DTC Serious Level
Bit (3-0): Reserved

Byte 1:
Bit (7-0): Reserved

Byte 2:
Bit (7-0): DTCHighByte

Byte 3:
Bit (7-0): DTCLowByte

Byte 4:
Bit (7-0): DTCFailureTypeByte

Byte 5:
Bit 7: warningIndicatorRequested
Bit 6: testNotCompletedThisOperationCycle
Bit 5: testFailedSinceLastClear
Bit 4: testNotCompletedSinceLastClear
Bit 3: confirmedDTC
Bit 2: pendingDTC
Bit 1: testFailedThisOperationCycle
Bit 0: testFailed

Byte 6:
Bit (7-0): DTC Type

For more detail, please refer to SMTC 2 800 004.
";
CM_ SG_ 929 FICMBrkLghtReqV "Front Infotainment Control Module Brake Light Request Validity
";
CM_ SG_ 929 FICMFLSeatVentSwReq "Front Infotainment Control Module Front Left Seat Vent Switch Request";
CM_ SG_ 929 FICMFRSeatVentSwReq "Front Infotainment Control Module Front Right Seat Vent Switch Request";
CM_ SG_ 907 ACAirQultCtrlEnbSwReq "Air Conditioning Air Quality Control Enable Switch Request


";
CM_ SG_ 907 ACEcoSwReq "Air Conditioning Economy Switch Request";
CM_ SG_ 907 ACFltrCsumLvlRstSwReq "Air Conditioning Filter Consume Level Reset Switch Request";
CM_ SG_ 907 ACFrtBlwrLvlReqV "Air Conditioning Front Blower Level Request Validity";
CM_ SG_ 907 ACRrAirMdSwReq "Air Conditioning Rear Air Mode Switch Request";
CM_ SG_ 907 FICMACAutoSwReq "Front Infotainment Control Module Air Conditioning Auto Switch Request";
CM_ SG_ 907 FICMACDualSwReq "Front Infotainment Control Module Air Conditioning Dual Switch Request";
CM_ SG_ 907 FICMACFreshSwReq "Front Infotainment Control Module Air Conditioning Fresh Switch Request";
CM_ SG_ 907 FICMACFrtBlwrLvlReq "Front Infotainment Control Module Air Conditioning Front Blower Level Request";
CM_ SG_ 907 FICMACFrtBlwrSpdDecSwR "Front Infotainment Control Module Air Conditioning Front Blower Speed Decrease Switch Request";
CM_ SG_ 907 FICMACFrtBlwrSpdIncSwR "Front Infotainment Control Module Air Conditioning Front Blower Speed Increase Switch Request";
CM_ SG_ 907 FICMACFrtPnlLckRrPnlSwReq "Front Infotainment Control Module Air Conditioning Front Panel Lock Rear Panel Switch Request
";
CM_ SG_ 907 FICMACIonizerReqSwReq "Front Infotainment Control Module Air Conditioning Ionizer Request Switch Request";
CM_ SG_ 907 FICMACLAirMdReq "Front Infotainment Control Module Air Conditioning Driver Air Mode Request";
CM_ SG_ 907 FICMACLAirMdReqV "Front Infotainment Control Module Air Conditioning Driver Air Mode Request Validity";
CM_ SG_ 907 FICMACLAirMdSwReq "Air Conditioning Driver Air Mode Switch Request";
CM_ SG_ 907 FICMACLTemDecSwReq "Front Infotainment Control Module Air Conditioning Driver Temperature Decrease Switch Request";
CM_ SG_ 907 FICMACLTemIncSwReq "Front Infotainment Control Module Air Conditioning Driver Temperature Increase Switch Request";
CM_ SG_ 907 FICMACLTemReq "Front Infotainment Control Module Air Conditioning Driver Temperature Request";
CM_ SG_ 907 FICMACLTemV "Air Conditioning Driver Temperature Validity";
CM_ SG_ 907 FICMACOnOffSwReq "Front Infotainment Control Module Air Conditioning On Off Switch Request";
CM_ SG_ 907 FICMACRAirMdReq "Front Infotainment Control Module Air Conditioning Passenger Air Mode Request";
CM_ SG_ 907 FICMACRAirMdReqV "Front Infotainment Control Module Air Conditioning Passenger Air Mode Request Validity";
CM_ SG_ 907 FICMACRAirMdSwReq "Front Infotainment Control Module Air Conditioning Passenger Air Mode Switch Request";
CM_ SG_ 907 FICMACRcctnSwReq "Front Infotainment Control Module Air Conditioning Recirculation Switch Request";
CM_ SG_ 907 FICMACRTemDecSwReq "Front Infotainment Control Module Air Conditioning Passenger Temperature Decrease Switch Request";
CM_ SG_ 907 FICMACRTemIncSwReq "Front Infotainment Control Module Air Conditioning Passenger Temperature Increase Switch Request";
CM_ SG_ 907 FICMACSyncSwReq "Front Infotainment Control Module Air Conditioning Front Rear Synchronization Switch Request";
CM_ SG_ 911 FICMACFrtPnlDspRrPnlSwReq "Front Infotainment Control Module Air Conditioning Front Panel Display Rear Panel Switch Request
";
CM_ SG_ 911 FICMACRrAirMdReq "Front Infotainment Control Module Air Conditioning Rear Air Mode Request";
CM_ SG_ 911 FICMACRrAirMdReqV "Front Infotainment Control Module Air Conditioning Rear Air Mode Request Validity";
CM_ SG_ 911 FICMACRrBlwrDecSwReq "Front Infotainment Control Module Air Conditioning Rear Blower Decrease Switch Request";
CM_ SG_ 911 FICMACRrBlwrIncSwReq "Front Infotainment Control Module Air Conditioning Rear Blower Increase Switch Request";
CM_ SG_ 911 FICMACRrBlwrLvlReq "Front Infotainment Control Module Air Conditioning Rear Blower Level Request";
CM_ SG_ 911 FICMACRrBlwrLvlReqV "Front Infotainment Control Module Air Conditioning Rear Blower Level Request Validity";
CM_ SG_ 911 FICMACRrTemDecSwReq "Front Infotainment Control Module Air Conditioning Rear Temperature Decrease Switch Request";
CM_ SG_ 911 FICMACRrTemIncSwReq "Front Infotainment Control Module Air Conditioning Rear Temperature Increase Switch Request";
CM_ SG_ 911 FICMACRrTemReq "Front Infotainment Control Module Air Conditioning Rear Temperature Request";
CM_ SG_ 911 FICMACRrTemV "Front Infotainment Control Module Air Conditioning Rear Temperature Validity";
CM_ SG_ 911 FICMACRTemReq "Front Infotainment Control Module Air Conditioning Passenger Temperature Request";
CM_ SG_ 911 FICMACRTemV "Air Conditioning Passenger Temperature Validity";
CM_ SG_ 911 FICMACTemUnitChngReq "Front Infotainment Control Module Air Conditioning Temperature Unit Change Request";
CM_ SG_ 911 FICMClmOnOffSwReq "Front Infortainment Control Module Climate On Off Switch Request";
CM_ SG_ 911 FICMComprOnOffSwReq "Front Infotainment Control Module Compressor On Off Switch Request";
CM_ SG_ 911 FICMDfstOnSwReq "Front Infotainment Control Module Defrost On Switch Request";
CM_ SG_ 911 FICMRrACAutoSwReq "Front Infotainment Control Module Rear Air Conditioning Auto Switch Request";
CM_ SG_ 911 FICMRrACOnOffSwReq "Front Infotainment Control Module Rear Air Conditioning On Off Switch Request";
CM_ SG_ 911 PwrLftgtPosSetngReq "Power Liftgate Position Setting Request";
CM_ SG_ 911 PwrLftgtPosSetngReqV "Power Liftgate Position Setting Request Validity";
CM_ SG_ 911 PwrLftgtSysEnb "Power Liftgate System Enable";
CM_ SG_ 911 StrgCDMSSetngReq "Steering Continuous Drive Mode Switch Setting Request";
CM_ SG_ 912 AmbtLghtCustSetngReq "Ambient Light Customization Setting Request
";
CM_ SG_ 912 AmbtLghtCustSetngReqV "Ambient Light Customization Setting Request Validity
";
CM_ SG_ 912 AmbtLghtDrvMdCustReq "Ambient Light Drive Mode Customization Request
";
CM_ SG_ 875 FICMDoorLckCtrlReq "FICM Door Lock Control Request";
CM_ SG_ 875 FICMDrvrWndOpReq "FICM Driver Window Operation Request
";
CM_ SG_ 875 FICMFrtPsngWndOpReq "FICM Front Passenger Window Operation Request
";
CM_ SG_ 875 FICMFrtWiperReq "Front Infotainment Control Module Front Wiper Request";
CM_ SG_ 875 FICMFrtWshReq "Front Infotainment Control Module Front Wash Request
";
CM_ SG_ 875 FICMHtdRrWndSwReq "Front Infotainment Control Module Heated Rear Window Switch Request";
CM_ SG_ 875 FICMLdspcUnlckReq "Front Infotainment Control Module Loadspace Unlock Request
";
CM_ SG_ 875 FICMOtsdMirFoldReq "Front Infotainment Control Module Outside Mirror Fold Request
";
CM_ SG_ 875 FICMRLWndOpReq "FICM Rear Left Window Operation Request
";
CM_ SG_ 875 FICMRrWiperReq "Front Infotainment Control Module Rear Wiper Request
";
CM_ SG_ 875 FICMRRWndOpReq "FICM Rear Right Window Operation Request
";
CM_ SG_ 875 FICMRrWshReq "Front Infotainment Control Module Rear Wash Request
";
CM_ SG_ 875 FICMSrfSlidePosReq "FICM Sunroof Slide Position Request
";
CM_ SG_ 875 FICMSrfTiltReq "FICM Sunroof Tilt Request
";
CM_ SG_ 875 FICMVehStSpReq "Front Infotainment Control Module Vehicle Start Stop Request
";
CM_ SG_ 875 FICMVehStSpReqV "Front Infotainment Control Module Vehicle Start Stop Request Validity
";
CM_ SG_ 875 FICMWiperOffReq "Front Infotainment Control Module Wiper Off Request
";
CM_ SG_ 875 FICMWiperSpdCtrlReq "Front Infotainment Control Module Wiper  Speed Control Request
";
CM_ SG_ 875 StorgMdSwReq "Storage Mode Switch Request
";
CM_ SG_ 931 FICM_100ms_PDU07_CRC "Wheel Ground Velocity Non Driven Checksum
Regarding high integrity requirement, a checksum signal is used for the bit field in same frame. The signal XOR operation is recommended for the calculation.";
CM_ SG_ 931 FICMEcoDrvngSwA "Front Infotainment Control Module Economy Driving Switch Active

";
CM_ SG_ 931 FICMEcoDrvngSwAV "Front Infotainment Control Module Economy Driving Switch Active Validity
";
CM_ SG_ 931 FICMPosngSysDircn "Front Infotainment Control Module Positioning System Direction
";
CM_ SG_ 931 LDWLKASwReq "Lane Departure Warning Lane Keeping Assist Switch Request";
CM_ SG_ 931 SpdAstMdFICM "Speed Assist Mode Front Infotainment Control Module
";
CM_ SG_ 931 SpdAstMdFICMV "Speed Assist Mode Front Infotainment Control Module Validity
";
CM_ SG_ 913 FICMAirClnrBlwrLvlReq "Front Infotainment Control Module Air Cleaner Blower Level Request
";
CM_ SG_ 913 FICMAirClnrBlwrLvlReqV "Front Infotainment Control Module Air Cleaner Blower Level Request Validity";
CM_ SG_ 913 FICMAirClnrBlwrSpdDecSwReq "Front Infotainment Control Module Air Cleaner Blower Speed Decrease Switch Request
";
CM_ SG_ 913 FICMAirClnrBlwrSpdIncSwReq "Front Infotainment Control Module Air Cleaner Blower Speed Increase Switch Request
";
CM_ SG_ 913 FICMBrkLghtReq "Front Infotainment Control Module Brake Light Request
";
CM_ SG_ 913 FICMCotsyLghtReq "Front Infotainment Control Module Courtesy Light Request
";
CM_ SG_ 913 FICMDipdBeamLghtReq "Front Infotainment Control Module Dipped Beam Light Request
";
CM_ SG_ 913 FICMDipdBeamLghtReqV "Front Infotainment Control Module Dipped Beam Light Request Validity
";
CM_ SG_ 913 FICMFLSeatHeatSwReq "Front Infotainment Control Module Front Left Seat Heat Switch Request";
CM_ SG_ 913 FICMFRSeatHeatSwReq "Front Infotainment Control Module Front Right Seat Heat Switch Request";
CM_ SG_ 913 FICMFrtFogLghtReq "Front Infotainment Control Module Front Fog Light Request
";
CM_ SG_ 913 FICMMainBeamLghtReq "Front Infotainment Control Module Main Beam Light Request
";
CM_ SG_ 913 FICMRevsLghtReq "Front Infotainment Control Module Reverse Light Request
";
CM_ SG_ 913 FICMRrFogLghtReq "Front Infotainment Control Module Rear Fog Light Request
";
CM_ SG_ 913 RstrFctryDeftsReq "Restore Factory Defaults Request";
CM_ SG_ 1121 BCMCofignUpdtInftn "Body Control Module Configuration Update from FICM
";
CM_ SG_ 1130 FICMPosngSysLatd "Front Infotainment Control Module Positioning System Latitude";
CM_ SG_ 1130 FICMPosngSysLongd "Front Infotainment Control Module Positioning System Longitude";
CM_ SG_ 1130 FICMWhlTypMontrRstReq "Front Infotainment Control Module Wheel Tyre Monitor Reset Request
";
CM_ SG_ 820 ACUserCustAftRunOnOffR "Air Conditioning User Customization After Run On Off Request";
CM_ SG_ 820 ACUserCustAftRunOnOffReqV "Air Conditioning User Customization After Run On Off Request Validity";
CM_ SG_ 820 ACUserCustAirQultEnbReq "Air Conditioning User Customization Air Quality Enable Request";
CM_ SG_ 820 ACUserCustAirQultEnbReqV "Air Conditioning User Customization Air Quality Enable Request Validity";
CM_ SG_ 820 ACUserCustAutoMdBlwrReq "Air Conditioning User Customization Auto Mode Blower Request";
CM_ SG_ 820 ACUserCustAutoMdBlwrReqV "Air Conditioning User Customization Auto Mode Blower Request Validity";
CM_ SG_ 820 ACUserCustAutoMdTemReq "Air Conditioning User Customization Auto Mode Temperature Request";
CM_ SG_ 820 ACUserCustAutoMdTemReqV "Air Conditioning User Customization Auto Mode Temperature Request Validity";
CM_ SG_ 820 ACUserCustBlwrAutoRunRmtUnlckReq "Air Conditioning User Customization Blower Auto Run Remote Unlock Request";
CM_ SG_ 820 ACUserCustBlwrAutoRunRmtUnlckReqV "Air Conditioning User Customization Blower Auto Run Remote Unlock Request Validity";
CM_ SG_ 820 ACUserCustCofignReq "Air Conditioning User Customization Configuration Request";
CM_ SG_ 820 ACUserCustCofignReqV "Air Conditioning User Customization Configuration Request Validity";
CM_ SG_ 820 ACUserCustFltrLifeRmndReq "Air Conditioning User Customization Filter Life Remind Request";
CM_ SG_ 820 ACUserCustFltrLifeRmndReqV "Air Conditioning User Customization Filter Life Remind Request Validity";
CM_ SG_ 820 ACUserCustFrtAutoDmstngReq "Air Conditioning User Customization Front Auto Demisting Request";
CM_ SG_ 820 ACUserCustFrtAutoDmstngReqV "Air Conditioning User Customization Front Auto Demisting Request Validity";
CM_ SG_ 820 ACUserCustRmtStOnOffReq "Air Conditioning User Customization Remote Start On Off Request";
CM_ SG_ 820 ACUserCustRmtStOnOffReqV "Air Conditioning User Customization Remote Start On Off Request Validity";
CM_ SG_ 820 ACUserCustRrAutoDmstngReq "Air Conditioning User Customization Rear Auto Demisting Request";
CM_ SG_ 820 ACUserCustRrAutoDmstngReqV "Air Conditioning User Customization Rear Auto Demisting Request Validity";
CM_ SG_ 820 ACUserCustRrZoneCofignReq "Air Conditioning User Customization Rear Zone Configuration Request";
CM_ SG_ 820 ACUserCustRrZoneCofignReqV "Air Conditioning User Customization Rear Zone Configuration Request Validity";
CM_ SG_ 820 ACUserCustStSpMdReq "Air Conditioning User Customization Start Stop Mode Request";
CM_ SG_ 820 ACUserCustStSpMdReqV "Air Conditioning User Customization Start Stop Mode Request Validity";
CM_ SG_ 820 ACUserCustTemUnitReq "Air Conditioning User Customization Temperature Unit Request";
CM_ SG_ 820 ACUserCustTemUnitReqV "Air Conditioning User Customization Temperature Unit Request Validity";
CM_ SG_ 820 ACUserCustZoneCofignReq "Air Conditioning User Customization Zone Configuration Request";
CM_ SG_ 820 ACUserCustZoneCofignReqV "Air Conditioning User Customization Zone Configuration Request Validity";
CM_ SG_ 820 AirClnrUserCustAutoRR "Air Cleaner User Customization Auto Run Request
";
CM_ SG_ 820 AirClnrUserCustAutoRRV "Air Cleaner User Customization Auto Run Request Validity
";
CM_ SG_ 820 FICMAirClnrFltrCsumLvlRstSwReq "Front Infotainment Control Module Air Cleaner Filter Consume Level Reset Switch Request
";
CM_ SG_ 820 FICMAirClnrIonizerSwR "Front Infotainment Control Module Air Cleaner Ionizer Switch Request
";
CM_ SG_ 820 FICMAirClnrOnOffSwReq "Front Infotainment Control Module Air Cleaner On Off Switch Request";
CM_ SG_ 690 AncptRoadSpdNav "Anticipated Road Speed Navigation
";
CM_ SG_ 690 AVMCalMdReq "Around View Monitor Calibration Mode Request";
CM_ SG_ 690 DistToTrgtNav "Distance To Target Navigation
";
CM_ SG_ 690 PDCSwReq "Park Distance Control Switch Request";
CM_ SG_ 690 SpdAstReqStsNav "Speed Assist Request Status Navigation
";
CM_ SG_ 690 TrgtSpdReqNav "Target Speed Request Navigation
";
CM_ SG_ 895 ACCTJAMdSwReq "Adaptive Cruise Control Traffic Jam Assist Mode Switch Request
";
CM_ SG_ 895 AEBSwReq "Autonomous Emergency Braking Switch Request";
CM_ SG_ 895 AutoLaneChngSwReq "Auto Lane Change Switch Request";
CM_ SG_ 895 DOWSelReq "Door Open Warning Select Request
";
CM_ SG_ 895 FCWSnstvtLvlReq "Forward Collision Warning Sensitivity Level Request
";
CM_ SG_ 895 FCWSwReq "Forward Collision Warning Switch Request
";
CM_ SG_ 895 LDWAdoWrnngReq "Lane Departure Warning Audio Warning Request";
CM_ SG_ 895 LDWLKAHptWrnngReq "Lane Departure Warning Lane Keeping Assist Haptic Warning Request";
CM_ SG_ 895 LDWSnstvtLvlReq "Lane Departure Warning Sensitivity Level Request";
CM_ SG_ 895 TJAICASwReq "Traffic Jam Assist Integrated Cruise Assist Switch Request";
CM_ SG_ 1347 LanggSetngAdj "Language Setting Adjustment
Language Setting Adjustment from infotainment";
CM_ SG_ 730 DrvrSeatPositionRecallReq "Diver Seat Position Recall Request";
CM_ SG_ 767 AVMDspReqResp "Around View Monitor Display Request Response";
CM_ SG_ 767 AVMDspSwReq "Around View Monitor Display Switch Request";
CM_ SG_ 767 CCDisAdjtVcCmd "Cruise Control Distance Adjust Voice Command";
CM_ SG_ 767 CCDisDecAndIncVcCmd "Cruise Control Distance Decrease And Increase Voice Command";
CM_ SG_ 767 CCSpdDecAndIncVcCmd "Cruise Control Speed Decrease And Increase Voice Command";
CM_ SG_ 767 CCSpdVcCmd "Cruise Control Speed Voice Command";
CM_ SG_ 767 CCSpdVcCmdSwReq "Cruise Control Speed Voice Command Switch Request";
CM_ SG_ 767 DMSAdoWrnngReq "Driver Monitor System Audio Warning Request";
CM_ SG_ 767 DMSHapticWrnngReq "Driver Monitor System Haptic Warning Request";
CM_ SG_ 767 DMSSwReq "Driver Monitor System Switch Request";
CM_ SG_ 767 ILCSwReq "Intelligent Lateral Control Switch Request";
CM_ SG_ 994 DrvrSeatAutoRclInh "Driver Seat Auto Recall Inhibit
";
CM_ SG_ 994 DrvrSeatEasyExitInh "Driver Seat Easy Exit Inhibit
";
CM_ SG_ 994 DrvrSeatHorzPosRecallCMD "Driver Seat Horizontal Position Recall Command";
CM_ SG_ 994 DrvrSeatReclinePosRecallCMD "Driver Seat Recline Position Recall Command";
CM_ SG_ 994 DrvrSeatTiltingPosRecallCMD "Driver Seat Tilting Position Recall Command";
CM_ SG_ 994 DrvrSeatVerticalPosRecallCMD "Driver Seat Vertical Position Recall Command";
CM_ SG_ 994 FICMStrgWhlHeatSWReq "Front Infotainment Control Module Steering Wheel Heat Switch Request";
CM_ SG_ 994 FLSeatMassIntstySwReq "Front Left Seat Massage Intensity Switch Request";
CM_ SG_ 994 FLSeatMassMdSwReq "Front Left Seat Massage Mode Switch Request";
CM_ SG_ 994 FRSeatMassIntstySwReq "Front Right Seat Massage Intensity Request";
CM_ SG_ 994 FRSeatMassMdSwReq "Front Right Seat Massage Mode Request";
CM_ SG_ 603 AVMDrvnSwReq "AVM Driver Switch Request";
CM_ SG_ 603 AVMDspReqRespSts "AVM Display Request Response Status";
CM_ SG_ 603 BrightnessAdjsmt "Brightness Adjustment";
CM_ SG_ 603 BrightnessBar "Brightness Bar";
CM_ SG_ 603 ContrastRatioAdjsmt "Contrast Ratio Adjustment";
CM_ SG_ 603 ContrastRatioBar "Contrast Ratio Bar";
CM_ SG_ 603 DynmcDrvngTrjctryLnSwReq "DynamicDrivingTrajectoryLineSwitch Request";
CM_ SG_ 603 FrtTmDrvAutVwSwReq "FirstTimeDriveAutViewSwitch Request";
CM_ SG_ 603 HigSpd3DVwSwReq "HighSpeed3D View Switch Request";
CM_ SG_ 603 ObstclAutVwSwReq "Obstacle Aut View Switch Request";
CM_ SG_ 603 ObstclMarkSwReq "Obstacle Mark Switch Request";
CM_ SG_ 603 SlientSearchNotifySwReq "APA Slient Search Notify  Switch Request";
CM_ SG_ 603 TurnngAutVwSwReq "Turning Aut View Switch Request";
CM_ SG_ 850 DrvrSelAPAParkngMd "Driver Select Advanced Park Assist Parking Mode";
CM_ SG_ 850 FICMAPAQuitReq "Ficm Apa Quit Request";
CM_ SG_ 850 FICMAPASwReq "Ficm Apa Switch Request";
CM_ SG_ 850 FICMPLCRtCoverSwReq "Ficm Routelearning Cover Switch Request";
CM_ SG_ 850 LADSUsrConfirmSts "Lads User Confirm Status";
CM_ SG_ 850 LADSUsrSelSlotID "Lads User Selected Slot Id";
CM_ SG_ 520 ICM_050ms_PDU14_CRC "Wheel Ground Velocity Non Driven Checksum
Regarding high integrity requirement, a checksum signal is used for the bit field in same frame. The signal XOR operation is recommended for the calculation.";
CM_ SG_ 79 AmbcSetngReq "Ambiance Setting Request";
CM_ SG_ 79 AmbcSetngReqV "Ambiance Setting Request Validity";
CM_ SG_ 79 BalcSetngReq "Balance Setting Request";
CM_ SG_ 79 BalcSetngReqV "Balance Setting Request Validity";
CM_ SG_ 79 ChmA "Chime Active";
CM_ SG_ 79 ChmSndVolmStepReq "Chime Sound Volume Step Request";
CM_ SG_ 79 ChmSndVolmStepReqV "Chime Sound Volume Step Request Validity";
CM_ SG_ 79 FdrSetngReq "Fader Setting Request";
CM_ SG_ 79 FdrSetngReqV "Fader Setting Request Validity";
CM_ SG_ 79 MdaSndVolmStepReq "Media Sound Volume Step Request";
CM_ SG_ 79 MdaSndVolmStepReqV "Media Sound Volume Step Request Validity";
CM_ SG_ 79 NavSndVolmStepReq "Navigation Sound Volume Step Request";
CM_ SG_ 79 NavSndVolmStepReqV "Navigation Sound Volume Step Request Validity";
CM_ SG_ 79 PhnCallSndVolmStepReq "Phone Call Sound Volume Step Request";
CM_ SG_ 79 PhnCallSndVolmStepReqV "Phone Call Sound Volume Step Request Validity";
CM_ SG_ 79 SpdDpntAutocVolmReq "Speed Dependant Automatic Volume Request";
CM_ SG_ 79 SpdDpntAutocVolmReqV "Speed Dependant Automatic Volume Request Validity";
CM_ SG_ 79 ThreeDimnSndFldSetngReq "Three Dimension Sound Field Setting Request";
CM_ SG_ 79 ThreeDimnSndFldSetngReqV "Three Dimension Sound Field Setting Request Validity";
CM_ SG_ 79 VcItatnSndVolmStepReq "Voice Interaction Sound Volume Step Request";
CM_ SG_ 79 VcItatnSndVolmStepReqV "Voice Interaction Sound Volume Step Request Validity";
CM_ SG_ 48 AllMuteReq "All Mute Request";
CM_ SG_ 48 AMPASndWaveSwReqV "Amplifier Active Sound Wave Switch Request Validity";
CM_ SG_ 48 BassReq "Bass Request";
CM_ SG_ 48 BassReqV "Bass Request Validity";
CM_ SG_ 48 CmprdSndQultRstrnReq "Compressed Sound Quality Restoration Request";
CM_ SG_ 48 ICMChmCmdSndLoctnFL "Intelligent Cockpit Module Chime Command Sound Location Front Left";
CM_ SG_ 48 ICMChmCmdSndLoctnFR "Intelligent Cockpit Module Chime Command Sound Location Front Right";
CM_ SG_ 48 ICMChmCmdSndLoctnRL "Intelligent Cockpit Module Chime Command Sound Location Rear Left";
CM_ SG_ 48 ICMChmCmdSndLoctnRR "Intelligent Cockpit Module Chime Command Sound Location Rear Right";
CM_ SG_ 48 LdnsSetngSoftSw "Loudness Setting Soft Switch";
CM_ SG_ 48 MdaA "Media Active";
CM_ SG_ 48 MdaMuteReq "Media Mute Request";
CM_ SG_ 48 MedReq "Medium Request";
CM_ SG_ 48 MedReqV "Medium Request Validity";
CM_ SG_ 48 NavA "Navigation Active";
CM_ SG_ 48 NotfnA "Notification Active";
CM_ SG_ 48 PhnA "Phone Active";
CM_ SG_ 48 TelphoComLoctn "Telephone Communication Location";
CM_ SG_ 48 TrblReq "Treble Request";
CM_ SG_ 48 TrblReqV "Treble Request Validity";
CM_ SG_ 48 VcItatnA "Voice Interaction Active";
CM_ SG_ 48 VcItatnSndLoctn "Voice Interaction Sound Location";

// Attribute definitions
BA_DEF_  "Baudrate" FLOAT 1000 1000000; // [bps]
BA_DEF_ BO_ "GenMsgSendType" ENUM "cyclic","spontaneous","cyclicIfActive","spontaneousWithDelay","cyclicAndSpontaneous","cyclicAndSpontaneousWithDelay","IfActive","NoMsgSendType"; // [us]
BA_DEF_ BO_ "GenMsgCycleTime" FLOAT 0 300000; // [ms]
BA_DEF_ BO_ "GenMsgStartDelayTime" FLOAT 0 300000; // [ms]
BA_DEF_ BO_ "GenMsgDelayTime" FLOAT 0 300000; // [ms]
BA_DEF_ SG_ "GenSigSendType" ENUM "Cyclic","OnWrite","OnWriteWithRepetition","OnChange","OnChangeWithRepetition","IfActive","IfActiveWithRepetition","NoSigSendType";
BA_DEF_ SG_ "GenSigStartValue" FLOAT -1.7976931348623157E308 18446744073709551615;
BA_DEF_ BU_ "NmAsrNodeIdentifier" INT 0 255;
BA_DEF_ BU_ "NmAsrNode" ENUM "No","Yes";
BA_DEF_  "DBName" STRING;
BA_DEF_  "BusType" STRING;
BA_DEF_  "ProtocolType" STRING;

BA_DEF_DEF_ "GenSigStartValue" 0;
BA_DEF_DEF_ "GenSigSendType" "Cyclic";
BA_DEF_DEF_ "NmAsrNodeIdentifier" 0;
BA_DEF_DEF_ "NmAsrNode" "No";
BA_DEF_DEF_ "DBName" "";
BA_DEF_DEF_ "BusType" "";
BA_DEF_DEF_ "ProtocolType" "";

// Network
BA_ "DBName" "ICM";
BA_ "BusType" "CAN";
BA_ "ProtocolType" "CAN";
BA_ "Baudrate" 500000;
// ECU: ICM
BA_ "NmAsrNodeIdentifier" BU_ ICM 194;
BA_ "NmAsrNode" BU_ ICM 1;
// Frame: DIAG_CFCAN_DTCInfo_FICM
BA_ "GenMsgSendType" BO_ 1977 1;
BA_ "GenMsgDelayTime" BO_ 1977 100.000;
BA_ "GenSigSendType" SG_ 1977 DTCInfomationFICM 1;
// Frame: DIAG_CFCAN_DTCInfo_IPK
BA_ "GenMsgSendType" BO_ 1976 1;
BA_ "GenMsgDelayTime" BO_ 1976 95.000;
BA_ "GenSigSendType" SG_ 1976 DTCInfomationIPK 1;
// Frame: Diag_CFCAN_PhyResp_FICM
BA_ "GenMsgSendType" BO_ 1897 1;
BA_ "GenMsgDelayTime" BO_ 1897 20.000;
// Frame: DIAG_PhysResp_VKR
BA_ "GenMsgSendType" BO_ 1547 1;
BA_ "GenMsgDelayTime" BO_ 1547 5.000;
BA_ "GenSigSendType" SG_ 1547 DiagnosticRespVKR 1;
// Frame: FICM_CFCAN_FrP01
BA_ "GenMsgSendType" BO_ 929 0;
BA_ "GenMsgCycleTime" BO_ 929 100.000;
BA_ "GenMsgStartDelayTime" BO_ 929 0.000;
BA_ "GenSigStartValue" SG_ 929 ACDrvrTemV 1;
BA_ "GenSigStartValue" SG_ 929 ACPsngTemV 1;
BA_ "GenSigStartValue" SG_ 929 FICMBrkLghtReqV 1;
// Frame: FICM_CFCAN_FrP02
BA_ "GenMsgSendType" BO_ 907 0;
BA_ "GenMsgCycleTime" BO_ 907 100.000;
BA_ "GenMsgStartDelayTime" BO_ 907 15.000;
BA_ "GenSigStartValue" SG_ 907 ACFrtBlwrLvlReqV 1;
BA_ "GenSigStartValue" SG_ 907 ACUserCustEcoSetngReqV 1;
BA_ "GenSigStartValue" SG_ 907 FICMACLAirMdReq 7;
BA_ "GenSigStartValue" SG_ 907 FICMACLAirMdReqV 1;
BA_ "GenSigStartValue" SG_ 907 FICMACLTemReq 31;
BA_ "GenSigStartValue" SG_ 907 FICMACLTemV 1;
BA_ "GenSigStartValue" SG_ 907 FICMACRAirMdReq 7;
BA_ "GenSigStartValue" SG_ 907 FICMACRAirMdReqV 1;
// Frame: FICM_CFCAN_FrP03
BA_ "GenMsgSendType" BO_ 911 0;
BA_ "GenMsgCycleTime" BO_ 911 100.000;
BA_ "GenMsgStartDelayTime" BO_ 911 15.000;
BA_ "GenSigStartValue" SG_ 911 FICMACRrAirMdReq 7;
BA_ "GenSigStartValue" SG_ 911 FICMACRrAirMdReqV 1;
BA_ "GenSigStartValue" SG_ 911 FICMACRrBlwrLvlReqV 1;
BA_ "GenSigStartValue" SG_ 911 FICMACRrTemReq 31;
BA_ "GenSigStartValue" SG_ 911 FICMACRrTemV 1;
BA_ "GenSigStartValue" SG_ 911 FICMACRTemReq 31;
BA_ "GenSigStartValue" SG_ 911 FICMACRTemV 1;
BA_ "GenSigStartValue" SG_ 911 PwrLftgtPosSetngReq 127;
BA_ "GenSigStartValue" SG_ 911 PwrLftgtPosSetngReqV 1;
BA_ "GenSigStartValue" SG_ 911 PwrLftgtSysEnb 1;
BA_ "GenSigStartValue" SG_ 911 StrgCDMSSetngReq 50;
BA_ "GenSigStartValue" SG_ 911 StrgCDMSSetngReqV 1;
// Frame: FICM_CFCAN_FrP04
BA_ "GenMsgSendType" BO_ 912 0;
BA_ "GenMsgCycleTime" BO_ 912 100.000;
BA_ "GenMsgStartDelayTime" BO_ 912 20.000;
BA_ "GenSigStartValue" SG_ 912 AmbtLghtCustSetngReqV 1;
BA_ "GenSigStartValue" SG_ 912 AmbtLghtWlcmMdReqV 1;
BA_ "GenSigStartValue" SG_ 912 AmbtLghtZoneCtrlReq 2;
BA_ "GenSigStartValue" SG_ 912 AmbtLghtZoneCtrlReqV 1;
// Frame: FICM_CFCAN_FrP05
BA_ "GenMsgSendType" BO_ 875 0;
BA_ "GenMsgCycleTime" BO_ 875 100.000;
BA_ "GenMsgStartDelayTime" BO_ 875 20.000;
BA_ "GenSigStartValue" SG_ 875 FICMDrvngMdSwReqV 1;
BA_ "GenSigStartValue" SG_ 875 FICMSrfSlidePosReq 15;
BA_ "GenSigStartValue" SG_ 875 FICMSsdOpenPosReq 15;
BA_ "GenSigStartValue" SG_ 875 FICMVehStSpReqV 1;
// Frame: FICM_CFCAN_FrP06
BA_ "GenMsgSendType" BO_ 930 0;
BA_ "GenMsgCycleTime" BO_ 930 100.000;
BA_ "GenMsgStartDelayTime" BO_ 930 25.000;
// Frame: FICM_CFCAN_FrP07
BA_ "GenMsgSendType" BO_ 931 0;
BA_ "GenMsgCycleTime" BO_ 931 100.000;
BA_ "GenMsgStartDelayTime" BO_ 931 25.000;
BA_ "GenSigStartValue" SG_ 931 FICM_100ms_PDU07_Reserve01 1;
BA_ "GenSigStartValue" SG_ 931 FICMEcoDrvngSwAV 1;
BA_ "GenSigStartValue" SG_ 931 NavSpdLmtValSts 2;
BA_ "GenSigStartValue" SG_ 931 NavSpdLmtValUnit 2;
BA_ "GenSigStartValue" SG_ 931 PtCustSetngReqV 1;
BA_ "GenSigStartValue" SG_ 931 SpdAstMdFICMV 1;
BA_ "GenSigStartValue" SG_ 931 StrgCustSetngReq 2;
BA_ "GenSigStartValue" SG_ 931 StrgCustSetngReqV 1;
BA_ "GenSigStartValue" SG_ 931 TrCustSetngReqV 1;
// Frame: FICM_CFCAN_FrP08
BA_ "GenMsgSendType" BO_ 902 0;
BA_ "GenMsgCycleTime" BO_ 902 100.000;
BA_ "GenMsgStartDelayTime" BO_ 902 30.000;
// Frame: FICM_CFCAN_FrP09
BA_ "GenMsgSendType" BO_ 903 0;
BA_ "GenMsgCycleTime" BO_ 903 100.000;
BA_ "GenMsgStartDelayTime" BO_ 903 30.000;
// Frame: FICM_CFCAN_FrP10
BA_ "GenMsgSendType" BO_ 913 0;
BA_ "GenMsgCycleTime" BO_ 913 100.000;
BA_ "GenMsgStartDelayTime" BO_ 913 35.000;
BA_ "GenSigStartValue" SG_ 913 ACUserCustSetngReq 2;
BA_ "GenSigStartValue" SG_ 913 ACUserCustSetngReqV 1;
BA_ "GenSigStartValue" SG_ 913 FICMACDrvrAirMdReq 7;
BA_ "GenSigStartValue" SG_ 913 FICMACDrvrAirMdReqV 1;
BA_ "GenSigStartValue" SG_ 913 FICMACDrvrTemReq 31;
BA_ "GenSigStartValue" SG_ 913 FICMACPsngTemReq 31;
BA_ "GenSigStartValue" SG_ 913 FICMAirClnrBlwrLvlReqV 1;
BA_ "GenSigStartValue" SG_ 913 FICMASSInhV 1;
BA_ "GenSigStartValue" SG_ 913 FICMDipdBeamLghtReqV 1;
// Frame: FICM_CFCAN_FrP11
BA_ "GenMsgSendType" BO_ 1121 0;
BA_ "GenMsgCycleTime" BO_ 1121 200.000;
BA_ "GenMsgStartDelayTime" BO_ 1121 45.000;
// Frame: FICM_CFCAN_FrP12
BA_ "GenMsgSendType" BO_ 1130 0;
BA_ "GenMsgCycleTime" BO_ 1130 200.000;
BA_ "GenMsgStartDelayTime" BO_ 1130 45.000;
// Frame: FICM_CFCAN_FrP13
BA_ "GenMsgSendType" BO_ 1351 0;
BA_ "GenMsgCycleTime" BO_ 1351 500.000;
BA_ "GenMsgStartDelayTime" BO_ 1351 5.000;
BA_ "GenSigStartValue" SG_ 1351 DrvrHdrtSpkrSndFldAdjReq 2;
BA_ "GenSigStartValue" SG_ 1351 DrvrHdrtSpkrSndFldAdjReqV 1;
BA_ "GenSigStartValue" SG_ 1351 DrvrHdrtSpkrSndFldOnOffReq 1;
BA_ "GenSigStartValue" SG_ 1351 DrvrHdrtSpkrSndFldOnOffReqV 1;
// Frame: FICM_CFCAN_FrP14
BA_ "GenMsgSendType" BO_ 1352 0;
BA_ "GenMsgCycleTime" BO_ 1352 1000.000;
BA_ "GenMsgStartDelayTime" BO_ 1352 10.000;
// Frame: FICM_CFCAN_FrP15
BA_ "GenMsgSendType" BO_ 820 0;
BA_ "GenMsgCycleTime" BO_ 820 100.000;
BA_ "GenMsgStartDelayTime" BO_ 820 35.000;
BA_ "GenSigStartValue" SG_ 820 ACUserCustAftRunOnOffReqV 1;
BA_ "GenSigStartValue" SG_ 820 ACUserCustAirQultEnbReq 3;
BA_ "GenSigStartValue" SG_ 820 ACUserCustAirQultEnbReqV 1;
BA_ "GenSigStartValue" SG_ 820 ACUserCustAutoMdBlwrReq 1;
BA_ "GenSigStartValue" SG_ 820 ACUserCustAutoMdBlwrReqV 1;
BA_ "GenSigStartValue" SG_ 820 ACUserCustAutoMdTemReq 1;
BA_ "GenSigStartValue" SG_ 820 ACUserCustAutoMdTemReqV 1;
BA_ "GenSigStartValue" SG_ 820 ACUserCustBlwrAutoRunRmtUnlckReqV 1;
BA_ "GenSigStartValue" SG_ 820 ACUserCustCofignReqV 1;
BA_ "GenSigStartValue" SG_ 820 ACUserCustFltrLifeRmndReq 1;
BA_ "GenSigStartValue" SG_ 820 ACUserCustFltrLifeRmndReqV 1;
BA_ "GenSigStartValue" SG_ 820 ACUserCustFrtAutoDmstngReq 1;
BA_ "GenSigStartValue" SG_ 820 ACUserCustFrtAutoDmstngReqV 1;
BA_ "GenSigStartValue" SG_ 820 ACUserCustRmtStOnOffReq 1;
BA_ "GenSigStartValue" SG_ 820 ACUserCustRmtStOnOffReqV 1;
BA_ "GenSigStartValue" SG_ 820 ACUserCustRrAutoDmstngReqV 1;
BA_ "GenSigStartValue" SG_ 820 ACUserCustRrZoneCofignReq 3;
BA_ "GenSigStartValue" SG_ 820 ACUserCustRrZoneCofignReqV 1;
BA_ "GenSigStartValue" SG_ 820 ACUserCustStSpMdReqV 1;
BA_ "GenSigStartValue" SG_ 820 ACUserCustTemUnitReq 1;
BA_ "GenSigStartValue" SG_ 820 ACUserCustTemUnitReqV 1;
BA_ "GenSigStartValue" SG_ 820 ACUserCustZoneCofignReq 3;
BA_ "GenSigStartValue" SG_ 820 ACUserCustZoneCofignReqV 1;
BA_ "GenSigStartValue" SG_ 820 AirClnrUserCustAutoRRV 1;
// Frame: FICM_CFCAN_FrP16
BA_ "GenMsgSendType" BO_ 690 0;
BA_ "GenMsgCycleTime" BO_ 690 50.000;
BA_ "GenMsgStartDelayTime" BO_ 690 15.000;
BA_ "GenSigStartValue" SG_ 690 FICMCCSwCCAV 1;
BA_ "GenSigStartValue" SG_ 690 SpdAstReqStsNav 1;
// Frame: FICM_CFCAN_FrP17
BA_ "GenMsgSendType" BO_ 895 0;
BA_ "GenMsgCycleTime" BO_ 895 100.000;
BA_ "GenMsgStartDelayTime" BO_ 895 40.000;
BA_ "GenSigStartValue" SG_ 895 SLIFWrnngStsReqV 1;
// Frame: FICM_CFCAN_FrP18
BA_ "GenMsgSendType" BO_ 1347 0;
BA_ "GenMsgCycleTime" BO_ 1347 500.000;
BA_ "GenMsgStartDelayTime" BO_ 1347 0.000;
// Frame: FICM_CFCAN_FrP20
BA_ "GenMsgSendType" BO_ 797 0;
BA_ "GenMsgCycleTime" BO_ 797 100.000;
BA_ "GenMsgStartDelayTime" BO_ 797 0.000;
BA_ "GenSigStartValue" SG_ 797 NavDircn 63;
BA_ "GenSigStartValue" SG_ 797 NavDist 32767;
// Frame: FICM_CFCAN_FrP23
BA_ "GenMsgSendType" BO_ 730 0;
BA_ "GenMsgCycleTime" BO_ 730 50.000;
BA_ "GenMsgStartDelayTime" BO_ 730 0.000;
BA_ "GenSigStartValue" SG_ 730 FrtPsngAirbagSwStsReq 1;
// Frame: FICM_CFCAN_FrP28
BA_ "GenMsgSendType" BO_ 767 0;
BA_ "GenMsgCycleTime" BO_ 767 100.000;
BA_ "GenMsgStartDelayTime" BO_ 767 5.000;
// Frame: FICM_CFCAN_FrP29
BA_ "GenMsgSendType" BO_ 762 0;
BA_ "GenMsgCycleTime" BO_ 762 100.000;
BA_ "GenMsgStartDelayTime" BO_ 762 5.000;
BA_ "GenSigStartValue" SG_ 762 FICMACPsngAirMdReq 7;
BA_ "GenSigStartValue" SG_ 762 FICMACPsngAirMdReqV 1;
BA_ "GenSigStartValue" SG_ 762 PowerModeShutdownRequest 1;
// Frame: FICM_CFCAN_FrP30
BA_ "GenMsgSendType" BO_ 384 0;
BA_ "GenMsgCycleTime" BO_ 384 20.000;
BA_ "GenMsgStartDelayTime" BO_ 384 0.000;
// Frame: FICM_CFCAN_FrP31
BA_ "GenMsgSendType" BO_ 994 0;
BA_ "GenMsgCycleTime" BO_ 994 100.000;
BA_ "GenMsgStartDelayTime" BO_ 994 10.000;
BA_ "GenSigStartValue" SG_ 994 DrvrSeatHorzPosRecallCMD 127;
BA_ "GenSigStartValue" SG_ 994 DrvrSeatReclinePosRecallCMD 127;
BA_ "GenSigStartValue" SG_ 994 DrvrSeatTiltingPosRecallCMD 127;
BA_ "GenSigStartValue" SG_ 994 DrvrSeatVerticalPosRecallCMD 127;
BA_ "GenSigStartValue" SG_ 994 FLSeatMassIntstySwReq 7;
BA_ "GenSigStartValue" SG_ 994 FLSeatMassMdSwReq 15;
// Frame: FICM_CFCAN_FrP32
BA_ "GenMsgSendType" BO_ 580 0;
BA_ "GenMsgCycleTime" BO_ 580 50.000;
BA_ "GenMsgStartDelayTime" BO_ 580 10.000;
BA_ "GenSigStartValue" SG_ 580 LOtsdMirHoztPosRclReq 127;
BA_ "GenSigStartValue" SG_ 580 LOtsdMirVertPosRclReq 127;
BA_ "GenSigStartValue" SG_ 580 ROtsdMirHoztPosRclReq 127;
BA_ "GenSigStartValue" SG_ 580 ROtsdMirVertPosRclReq 127;
// Frame: FICM_CFCAN_FrP33
BA_ "GenMsgSendType" BO_ 836 0;
BA_ "GenMsgCycleTime" BO_ 836 100.000;
BA_ "GenMsgStartDelayTime" BO_ 836 0.000;
// Frame: FICM_CFCAN_FrP35
BA_ "GenMsgSendType" BO_ 603 0;
BA_ "GenMsgCycleTime" BO_ 603 50.000;
BA_ "GenMsgStartDelayTime" BO_ 603 5.000;
// Frame: FICM_CFCAN_FrP36
BA_ "GenMsgSendType" BO_ 850 0;
BA_ "GenMsgCycleTime" BO_ 850 100.000;
BA_ "GenMsgStartDelayTime" BO_ 850 20.000;
// Frame: FICM_CFCAN_FrP42
BA_ "GenMsgSendType" BO_ 833 0;
BA_ "GenMsgCycleTime" BO_ 833 100.000;
BA_ "GenMsgStartDelayTime" BO_ 833 10.000;
// Frame: FICM_CFCAN_FrP43
BA_ "GenMsgSendType" BO_ 843 0;
BA_ "GenMsgCycleTime" BO_ 843 100.000;
BA_ "GenMsgStartDelayTime" BO_ 843 10.000;
BA_ "GenSigStartValue" SG_ 843 ELSDCustSetngReq 2;
BA_ "GenSigStartValue" SG_ 843 ELSDCustSetngReqV 1;
BA_ "GenSigStartValue" SG_ 843 ExhDeftMdReqForXMd 2;
BA_ "GenSigStartValue" SG_ 843 ExhSptyCustrMdTrigEnSpd 4;
BA_ "GenSigStartValue" SG_ 843 ExhSptyCustrMdTrigPdlPos 3;
BA_ "GenSigStartValue" SG_ 843 ExhSptyMdReq 1;
BA_ "GenSigStartValue" SG_ 843 SCMCustSetngReq 2;
BA_ "GenSigStartValue" SG_ 843 SCMCustSetngReqV 1;
BA_ "GenSigStartValue" SG_ 843 SCSCustSetngReqV 1;
// Frame: FICM_CFCAN_FrP44
BA_ "GenMsgSendType" BO_ 868 0;
BA_ "GenMsgCycleTime" BO_ 868 100.000;
BA_ "GenMsgStartDelayTime" BO_ 868 10.000;
BA_ "GenSigStartValue" SG_ 868 FrtSusSprMdCtrlPnt0 5;
BA_ "GenSigStartValue" SG_ 868 FrtSusSprMdCtrlPnt1 5;
BA_ "GenSigStartValue" SG_ 868 FrtSusSprMdCtrlPnt2 5;
BA_ "GenSigStartValue" SG_ 868 FrtSusSprMdCtrlPnt3 5;
BA_ "GenSigStartValue" SG_ 868 FrtSusSprMdCtrlPnt4 5;
BA_ "GenSigStartValue" SG_ 868 FrtSusSprMdCtrlPnt5 5;
BA_ "GenSigStartValue" SG_ 868 FrtSusSprMdCtrlPnt6 5;
BA_ "GenSigStartValue" SG_ 868 FrtSusSprMdCtrlPnt7 5;
BA_ "GenSigStartValue" SG_ 868 FrtSusSprMdCtrlPnt8 5;
BA_ "GenSigStartValue" SG_ 868 FrtSusSprMdCtrlPnt9 5;
// Frame: FICM_CFCAN_FrP45
BA_ "GenMsgSendType" BO_ 869 0;
BA_ "GenMsgCycleTime" BO_ 869 100.000;
BA_ "GenMsgStartDelayTime" BO_ 869 10.000;
BA_ "GenSigStartValue" SG_ 869 RrSusSprMdCtrlPnt0 5;
BA_ "GenSigStartValue" SG_ 869 RrSusSprMdCtrlPnt1 5;
BA_ "GenSigStartValue" SG_ 869 RrSusSprMdCtrlPnt2 5;
BA_ "GenSigStartValue" SG_ 869 RrSusSprMdCtrlPnt3 5;
BA_ "GenSigStartValue" SG_ 869 RrSusSprMdCtrlPnt4 5;
BA_ "GenSigStartValue" SG_ 869 RrSusSprMdCtrlPnt5 5;
BA_ "GenSigStartValue" SG_ 869 RrSusSprMdCtrlPnt6 5;
BA_ "GenSigStartValue" SG_ 869 RrSusSprMdCtrlPnt7 5;
BA_ "GenSigStartValue" SG_ 869 RrSusSprMdCtrlPnt8 5;
BA_ "GenSigStartValue" SG_ 869 RrSusSprMdCtrlPnt9 5;
// Frame: FICM_CFCAN_FrS25
BA_ "GenMsgSendType" BO_ 1667 1;
BA_ "GenMsgDelayTime" BO_ 1667 5.000;
BA_ "GenSigSendType" SG_ 1667 EvtPotclSigFICM 1;
// Frame: ICM_CFCAN_FrP14
BA_ "GenMsgSendType" BO_ 520 0;
BA_ "GenMsgCycleTime" BO_ 520 50.000;
BA_ "GenMsgStartDelayTime" BO_ 520 0.000;
BA_ "GenSigStartValue" SG_ 520 ICM_050ms_PDU14_Reserve01 3;
BA_ "GenSigStartValue" SG_ 520 ICM_050ms_PDU14_Reserve02 1;
BA_ "GenSigStartValue" SG_ 520 ICM_050ms_PDU14_Reserve03 2097151;
// Frame: ICM_CFCAN_FrP16
BA_ "GenMsgSendType" BO_ 97 0;
BA_ "GenMsgCycleTime" BO_ 97 100.000;
BA_ "GenMsgStartDelayTime" BO_ 97 0.000;
BA_ "GenSigStartValue" SG_ 97 DsttnDist 65535;
BA_ "GenSigStartValue" SG_ 97 DsttnHour 63;
BA_ "GenSigStartValue" SG_ 97 DsttnMinute 63;
BA_ "GenSigStartValue" SG_ 97 HudPhnSts 6;
// Frame: ICM_CFCAN_FrS04
BA_ "GenMsgSendType" BO_ 79 1;
BA_ "GenMsgDelayTime" BO_ 79 5.000;
BA_ "GenSigStartValue" SG_ 79 AmbcSetngReq 1;
BA_ "GenSigSendType" SG_ 79 AmbcSetngReq 1;
BA_ "GenSigStartValue" SG_ 79 AmbcSetngReqV 1;
BA_ "GenSigSendType" SG_ 79 AmbcSetngReqV 1;
BA_ "GenSigStartValue" SG_ 79 BalcSetngReq 7;
BA_ "GenSigSendType" SG_ 79 BalcSetngReq 1;
BA_ "GenSigStartValue" SG_ 79 BalcSetngReqV 1;
BA_ "GenSigSendType" SG_ 79 BalcSetngReqV 1;
BA_ "GenSigSendType" SG_ 79 ChmA 1;
BA_ "GenSigStartValue" SG_ 79 ChmSndVolmStepReq 7;
BA_ "GenSigSendType" SG_ 79 ChmSndVolmStepReq 1;
BA_ "GenSigStartValue" SG_ 79 ChmSndVolmStepReqV 1;
BA_ "GenSigSendType" SG_ 79 ChmSndVolmStepReqV 1;
BA_ "GenSigStartValue" SG_ 79 FdrSetngReq 7;
BA_ "GenSigSendType" SG_ 79 FdrSetngReq 1;
BA_ "GenSigStartValue" SG_ 79 FdrSetngReqV 1;
BA_ "GenSigSendType" SG_ 79 FdrSetngReqV 1;
BA_ "GenSigStartValue" SG_ 79 MdaSndVolmStepReq 15;
BA_ "GenSigSendType" SG_ 79 MdaSndVolmStepReq 1;
BA_ "GenSigStartValue" SG_ 79 MdaSndVolmStepReqV 1;
BA_ "GenSigSendType" SG_ 79 MdaSndVolmStepReqV 1;
BA_ "GenSigStartValue" SG_ 79 NavSndVolmStepReq 8;
BA_ "GenSigSendType" SG_ 79 NavSndVolmStepReq 1;
BA_ "GenSigStartValue" SG_ 79 NavSndVolmStepReqV 1;
BA_ "GenSigSendType" SG_ 79 NavSndVolmStepReqV 1;
BA_ "GenSigStartValue" SG_ 79 PhnCallSndVolmStepReq 15;
BA_ "GenSigSendType" SG_ 79 PhnCallSndVolmStepReq 1;
BA_ "GenSigStartValue" SG_ 79 PhnCallSndVolmStepReqV 1;
BA_ "GenSigSendType" SG_ 79 PhnCallSndVolmStepReqV 1;
BA_ "GenSigStartValue" SG_ 79 SpdDpntAutocVolmReq 2;
BA_ "GenSigSendType" SG_ 79 SpdDpntAutocVolmReq 1;
BA_ "GenSigStartValue" SG_ 79 SpdDpntAutocVolmReqV 1;
BA_ "GenSigSendType" SG_ 79 SpdDpntAutocVolmReqV 1;
BA_ "GenSigStartValue" SG_ 79 ThreeDimnSndFldSetngReq 1;
BA_ "GenSigSendType" SG_ 79 ThreeDimnSndFldSetngReq 1;
BA_ "GenSigStartValue" SG_ 79 ThreeDimnSndFldSetngReqV 1;
BA_ "GenSigSendType" SG_ 79 ThreeDimnSndFldSetngReqV 1;
BA_ "GenSigStartValue" SG_ 79 VcItatnSndVolmStepReq 8;
BA_ "GenSigSendType" SG_ 79 VcItatnSndVolmStepReq 1;
BA_ "GenSigStartValue" SG_ 79 VcItatnSndVolmStepReqV 1;
BA_ "GenSigSendType" SG_ 79 VcItatnSndVolmStepReqV 1;
// Frame: ICM_CFCAN_FrS05
BA_ "GenMsgSendType" BO_ 48 1;
BA_ "GenMsgDelayTime" BO_ 48 5.000;
BA_ "GenSigSendType" SG_ 48 AllMuteReq 1;
BA_ "GenSigSendType" SG_ 48 AMPASndWaveSelReq 1;
BA_ "GenSigStartValue" SG_ 48 AMPASndWaveSelReqV 1;
BA_ "GenSigSendType" SG_ 48 AMPASndWaveSelReqV 1;
BA_ "GenSigSendType" SG_ 48 AMPASndWaveSwReq 1;
BA_ "GenSigStartValue" SG_ 48 AMPASndWaveSwReqV 1;
BA_ "GenSigSendType" SG_ 48 AMPASndWaveSwReqV 1;
BA_ "GenSigStartValue" SG_ 48 AMPASndWaveVolmSwReq 6;
BA_ "GenSigSendType" SG_ 48 AMPASndWaveVolmSwReq 1;
BA_ "GenSigStartValue" SG_ 48 AMPASndWaveVolmSwReqV 1;
BA_ "GenSigSendType" SG_ 48 AMPASndWaveVolmSwReqV 1;
BA_ "GenSigSendType" SG_ 48 ANCOnOffReq 1;
BA_ "GenSigStartValue" SG_ 48 ANCOnOffReqV 1;
BA_ "GenSigSendType" SG_ 48 ANCOnOffReqV 1;
BA_ "GenSigStartValue" SG_ 48 BassReq 7;
BA_ "GenSigSendType" SG_ 48 BassReq 1;
BA_ "GenSigStartValue" SG_ 48 BassReqV 1;
BA_ "GenSigSendType" SG_ 48 BassReqV 1;
BA_ "GenSigStartValue" SG_ 48 CmprdSndQultRstrnReq 1;
BA_ "GenSigSendType" SG_ 48 CmprdSndQultRstrnReq 1;
BA_ "GenSigSendType" SG_ 48 ICMChmCmdSndLoctnFL 1;
BA_ "GenSigSendType" SG_ 48 ICMChmCmdSndLoctnFR 1;
BA_ "GenSigSendType" SG_ 48 ICMChmCmdSndLoctnRL 1;
BA_ "GenSigSendType" SG_ 48 ICMChmCmdSndLoctnRR 1;
BA_ "GenSigStartValue" SG_ 48 LdnsSetngSoftSw 1;
BA_ "GenSigSendType" SG_ 48 LdnsSetngSoftSw 1;
BA_ "GenSigSendType" SG_ 48 MdaA 1;
BA_ "GenSigSendType" SG_ 48 MdaMuteReq 1;
BA_ "GenSigStartValue" SG_ 48 MedReq 7;
BA_ "GenSigSendType" SG_ 48 MedReq 1;
BA_ "GenSigStartValue" SG_ 48 MedReqV 1;
BA_ "GenSigSendType" SG_ 48 MedReqV 1;
BA_ "GenSigSendType" SG_ 48 NavA 1;
BA_ "GenSigSendType" SG_ 48 NotfnA 1;
BA_ "GenSigSendType" SG_ 48 PhnA 1;
BA_ "GenSigSendType" SG_ 48 TelphoComLoctn 1;
BA_ "GenSigStartValue" SG_ 48 TrblReq 7;
BA_ "GenSigSendType" SG_ 48 TrblReq 1;
BA_ "GenSigStartValue" SG_ 48 TrblReqV 1;
BA_ "GenSigSendType" SG_ 48 TrblReqV 1;
BA_ "GenSigSendType" SG_ 48 VcItatnA 1;
BA_ "GenSigSendType" SG_ 48 VcItatnSndLoctn 1;
// Frame: ICM_CFCAN_FrS06
BA_ "GenMsgSendType" BO_ 1566 1;
BA_ "GenMsgDelayTime" BO_ 1566 5.000;
BA_ "GenSigSendType" SG_ 1566 EvtPotclSigICM 1;

VAL_ 929 ACDrvrTemV 0 "Valid" 1 "Invalid";
VAL_ 929 ACPsngTemV 0 "Valid" 1 "Invalid";
VAL_ 929 CBDSelReq 0 "CBDSelReq_No_request" 1 "CBDSelReq_Drive_Switch_Off_Request" 2 "CBDSelReq_Drive_Switch_On_Request" 3 "CBDSelReq_Reserved";
VAL_ 929 CIASelReq 0 "CIASelReq_No_request" 1 "CIASelReq_Drive_Switch_Off_Request" 2 "CIASelReq_Drive_Switch_On_Request" 3 "CIASelReq_Reserved";
VAL_ 929 CIASetSwReq 0 "CIASetSwReq_No_request" 1 "CIASetSwReq_Open" 2 "CIASetSwReq_Closed" 3 "CIASetSwReq_Reserved";
VAL_ 929 CLAWrnngSndSwSetng 0 "CLAWrnngSndSwSetng_No_request" 1 "CLAWrnngSndSwSetng_Drive_Switch_On_Request" 2 "CLAWrnngSndSwSetng_Drive_Switch_off_Request" 3 "CLAWrnngSndSwSetng_Reserved";
VAL_ 929 CLWSelReq 0 "CLWSelReq_No_request" 1 "CLWSelReq_Drive_Switch_On_Request" 2 "CLWSelReq_Drive_Switch_off_Request" 3 "CLWSelReq_Reserved";
VAL_ 929 FICMBrkLghtReqV 0 "Valid" 1 "Invalid";
VAL_ 929 FICMFLSeatVentSwReq 0 "FICMFLSeatVentSwReq_No_request" 1 "FICMFLSeatVentSwReq_short_press" 2 "FICMFLSeatVentSwReq_long_press";
VAL_ 929 FICMFRSeatVentSwReq 0 "FICMFRSeatVentSwReq_No_request" 1 "FICMFRSeatVentSwReq_Short_press" 2 "FICMFRSeatVentSwReq_Long_press";
VAL_ 929 LowSpdAutocOpenAVMReq 0 "LowSpdAutocOpenAVMReq_unavailable" 1 "LowSpdAutocOpenAVMReq_Disable" 2 "LowSpdAutocOpenAVMReq_Enable" 3 "LowSpdAutocOpenAVMReq_Reserved";
VAL_ 929 RrViewInfoAstntDspSwReq 0 "no_request" 1 "open" 2 "close" 3 "reserve";
VAL_ 929 RrViewInfoAstntSelReq 0 "No_requestReserved" 1 "Drive_Switch_Off_Request" 2 "Drive_Switch_On_Request" 3 "Reserved";
VAL_ 929 VehBodyColorReq 0 "VehBodyColorReq_No_request" 1 "VehBodyColorReq_BLACK" 2 "VehBodyColorReq_BLUE" 3 "VehBodyColorReq_WHITE" 4 "VehBodyColorReq_RED" 5 "VehBodyColorReq_GRAY" 6 "VehBodyColorReq_SILVER" 7 "VehBodyColorReq_GOLD" 8 "VehBodyColorReq_BLACK_WHITE" 9 "VehBodyColorReq_ORANGE" 10 "VehBodyColorReq_10_reserved" 11 "VehBodyColorReq_11_reserved" 12 "VehBodyColorReq_12_reserved" 13 "VehBodyColorReq_13_reserved" 14 "VehBodyColorReq_14_reserved" 15 "VehBodyColorReq_15_reserved";
VAL_ 907 ACAirQultCtrlEnbSwReq 0 "ACAirQultCtrlEnbSwReq_No_request" 1 "ACAirQultCtrlEnbSwReq_Short_press" 2 "ACAirQultCtrlEnbSwReq_Long_press" 3 "ACAirQultCtrlEnbSwReq_Reserved";
VAL_ 907 ACEcoSwReq 0 "ACEcoSwReq_No_request" 1 "ACEcoSwReq_Short_press" 2 "ACEcoSwReq_Long_press" 3 "ACEcoSwReq_3_Reserved";
VAL_ 907 ACFltrCsumLvlRstSwReq 0 "ACFltrCsumLvlRstSwReq_No_request" 1 "ACFltrCsumLvlRstSwReq_Short_press" 2 "ACFltrCsumLvlRstSwReq_Long_press" 3 "ACFltrCsumLvlRstSwReq_3_Reserved";
VAL_ 907 ACFrtBlwrLvlReqV 0 "ACFrtBlwrLvlReqV_0_Valid" 1 "ACFrtBlwrLvlReqV_1_Invalid";
VAL_ 907 ACRrAirMdSwReq 0 "ACRrAirMdSwReq_No_request" 1 "ACRrAirMdSwReq_Short_press" 2 "ACRrAirMdSwReq_Long_press";
VAL_ 907 ACUserCustEcoSetngReq 0 "ACUserCustEcoSetngReq_0_Unavailable" 1 "ACUserCustEcoSetngReq_1_Economy_Mode" 2 "ACUserCustEcoSetngReq_2_Normal_Mode" 3 "ACUserCustEcoSetngReq_3_Reserved";
VAL_ 907 ACUserCustEcoSetngReqV 0 "ACUserCustEcoSetngReqV_0_Valid" 1 "ACUserCustEcoSetngReqV_1_Invalid";
VAL_ 907 FICMACAutoSwReq 0 "FICMACAutoSwReq_No_request" 1 "FICMACAutoSwReq_Short_press" 2 "FICMACAutoSwReq_Long_press";
VAL_ 907 FICMACDualSwReq 0 "FICMACDualSwReq_No_request" 1 "FICMACDualSwReq_Short_press" 2 "FICMACDualSwReq_Long_press";
VAL_ 907 FICMACFreshSwReq 0 "FICMACFreshSwReq_No_request" 1 "FICMACFreshSwReq_Short_press" 2 "FICMACFreshSwReq_Long_press";
VAL_ 907 FICMACFrtBlwrLvlReq 0 "FICMACFrtBlwrLvlReq_Blower_off" 1 "FICMACFrtBlwrLvlReq_Blower_level_1" 2 "FICMACFrtBlwrLvlReq_Blower_level_2" 3 "FICMACFrtBlwrLvlReq_Blower_level_3" 4 "FICMACFrtBlwrLvlReq_Blower_level_4" 5 "FICMACFrtBlwrLvlReq_Blower_level_5" 6 "FICMACFrtBlwrLvlReq_Blower_level_6" 7 "FICMACFrtBlwrLvlReq_Blower_level_7" 8 "FICMACFrtBlwrLvlReq_Blower_level_8" 9 "FICMACFrtBlwrLvlReq_Blower_level_9" 10 "FICMACFrtBlwrLvlReq_Blower_level_10" 11 "FICMACFrtBlwrLvlReq_Blower_level_11" 12 "FICMACFrtBlwrLvlReq_Blower_level_12" 13 "FICMACFrtBlwrLvlReq_Blower_level_13" 14 "FICMACFrtBlwrLvlReq_Blower_level_14" 15 "FICMACFrtBlwrLvlReq_Blower_level_15";
VAL_ 907 FICMACFrtBlwrSpdDecSwR 0 "FICMACFrtBlwrSpdDecSwR_No_request" 1 "FICMACFrtBlwrSpdDecSwR_Short_press" 2 "FICMACFrtBlwrSpdDecSwR_Long_press";
VAL_ 907 FICMACFrtBlwrSpdIncSwR 0 "FICMACFrtBlwrSpdIncSwR_No_request" 1 "FICMACFrtBlwrSpdIncSwR_Short_press" 2 "FICMACFrtBlwrSpdIncSwR_Long_press";
VAL_ 907 FICMACFrtPnlLckRrPnlSwReq 0 "FICMACFrtPnlLckRrPnlSwReq_No_request" 1 "FICMACFrtPnlLckRrPnlSwReq_Short_press" 2 "FICMACFrtPnlLckRrPnlSwReq_Long_press" 3 "FICMACFrtPnlLckRrPnlSwReq_Reserved";
VAL_ 907 FICMACIonizerReqSwReq 0 "FICMACIonizerReqSwReq_No_request" 1 "FICMACIonizerReqSwReq_Short_press" 2 "FICMACIonizerReqSwReq_Long_press";
VAL_ 907 FICMACLAirMdReq 0 "FICMACDrvrAirMdReq_face" 1 "FICMACDrvrAirMdReq_face_foot" 2 "FICMACDrvrAirMdReq_foot" 3 "FICMACDrvrAirMdReq_foot_defrost" 4 "FICMACDrvrAirMdReq_defrost" 5 "FICMACDrvrAirMdReq_face_foot_defrost" 6 "FICMACDrvrAirMdReq_face_defrost" 7 "FICMACDrvrAirMdReq_No_Command_air_distribute_mode";
VAL_ 907 FICMACLAirMdReqV 0 "Valid" 1 "Invalid";
VAL_ 907 FICMACLAirMdSwReq 0 "ACDrvrAirMdSwReq_No_request" 1 "ACDrvrAirMdSwReq_short_press" 2 "ACDrvrAirMdSwReq_long_press";
VAL_ 907 FICMACLTemDecSwReq 0 "FICMACDrvrTemDecSwReq_No_request" 1 "FICMACDrvrTemDecSwReq_Short_press" 2 "FICMACDrvrTemDecSwReq_Long_press";
VAL_ 907 FICMACLTemIncSwReq 0 "FICMACDrvrTemIncSwReq_No_request" 1 "FICMACDrvrTemIncSwReq_Short_press" 2 "FICMACDrvrTemIncSwReq_Long_press";
VAL_ 907 FICMACLTemReq 0 "FICMACDrvrTemReq_Lo" 30 "FICMACDrvrTemReq_High" 31 "FICMACDrvrTemReq_Reserved";
VAL_ 907 FICMACLTemV 0 "ACDrvrTemV_0_Valid" 1 "ACDrvrTemV_1_Invalid";
VAL_ 907 FICMACOnOffSwReq 0 "FICMACOnOffSwReq_No_request" 1 "FICMACOnOffSwReq_Short_press" 2 "FICMACOnOffSwReq_Long_press";
VAL_ 907 FICMACRAirMdReq 0 "FICMACPsngAirMdReq_face" 1 "FICMACPsngAirMdReq_face_foot" 2 "FICMACPsngAirMdReq_foot" 3 "FICMACPsngAirMdReq_foot_defrost" 4 "FICMACPsngAirMdReq_defrost" 5 "FICMACPsngAirMdReq_face_foot_defrost" 6 "FICMACPsngAirMdReq_face_defrost" 7 "FICMACPsngAirMdReq_No_Command_air_distribute_mode";
VAL_ 907 FICMACRAirMdReqV 0 "Valid" 1 "Invalid";
VAL_ 907 FICMACRAirMdSwReq 0 "FICMACPsngAirMdSwReq_No_request" 1 "FICMACPsngAirMdSwReq_Short_press" 2 "FICMACPsngAirMdSwReq_Long_press";
VAL_ 907 FICMACRcctnSwReq 0 "FICMACRcctnSwReq_No_request" 1 "FICMACRcctnSwReq_Short_press" 2 "FICMACRcctnSwReq_Long_press";
VAL_ 907 FICMACRTemDecSwReq 0 "FICMACPsngTemDecSwReq_No_request" 1 "FICMACPsngTemDecSwReq_Short_press" 2 "FICMACPsngTemDecSwReq_Long_press";
VAL_ 907 FICMACRTemIncSwReq 0 "FICMACPsngTemIncSwReq_No_request" 1 "FICMACPsngTemIncSwReq_Short_press" 2 "FICMACPsngTemIncSwReq_Long_press";
VAL_ 907 FICMACSyncSwReq 0 "FICMACFrtRrSyncSwReq_No_request" 1 "FICMACFrtRrSyncSwReq_Short_press" 2 "FICMACFrtRrSyncSwReq_Long_press" 3 "FICMACFrtRrSyncSwReq_Reserved";
VAL_ 911 FICMACFrtPnlDspRrPnlSwReq 0 "FICMACFrtPnlDspRrPnlSwReq_No_request" 1 "FICMACFrtPnlDspRrPnlSwReq_Short_press" 2 "FICMACFrtPnlDspRrPnlSwReq_Long_press" 3 "FICMACFrtPnlDspRrPnlSwReq_Reserved";
VAL_ 911 FICMACRrAirMdReq 0 "FICMACRrAirMdReq_face" 1 "FICMACRrAirMdReq_face_foot" 2 "FICMACRrAirMdReq_foot" 3 "FICMACRrAirMdReq_foot_defrost" 4 "FICMACRrAirMdReq_defrost" 5 "FICMACRrAirMdReq_face_foot_defrost" 6 "FICMACRrAirMdReq_face_defrost" 7 "FICMACRrAirMdReq_No_Command_air_distribute_mode";
VAL_ 911 FICMACRrAirMdReqV 0 "Valid" 1 "Invalid";
VAL_ 911 FICMACRrBlwrDecSwReq 0 "FICMACRrBlwrDecSwReq_No_request" 1 "FICMACRrBlwrDecSwReq_Short_press" 2 "FICMACRrBlwrDecSwReq_Long_press";
VAL_ 911 FICMACRrBlwrIncSwReq 0 "FICMACRrBlwrIncSwReq_No_request" 1 "FICMACRrBlwrIncSwReq_Short_press" 2 "FICMACRrBlwrIncSwReq_Long_press";
VAL_ 911 FICMACRrBlwrLvlReq 0 "FICMACRrBlwrLvlReq_Blower_off" 1 "FICMACRrBlwrLvlReq_Blower_level_1" 2 "FICMACRrBlwrLvlReq_Blower_level_2" 3 "FICMACRrBlwrLvlReq_Blower_level_3" 4 "FICMACRrBlwrLvlReq_Blower_level_4" 5 "FICMACRrBlwrLvlReq_Blower_level_5" 6 "FICMACRrBlwrLvlReq_Blower_level_6" 7 "FICMACRrBlwrLvlReq_Blower_level_7" 8 "FICMACRrBlwrLvlReq_Blower_level_8" 9 "FICMACRrBlwrLvlReq_Blower_level_9" 10 "FICMACRrBlwrLvlReq_Blower_level_10" 11 "FICMACRrBlwrLvlReq_Blower_level_11" 12 "FICMACRrBlwrLvlReq_Blower_level_12" 13 "FICMACRrBlwrLvlReq_Blower_level_13" 14 "FICMACRrBlwrLvlReq_Blower_level_14" 15 "FICMACRrBlwrLvlReq_Blower_level_15";
VAL_ 911 FICMACRrBlwrLvlReqV 0 "Valid" 1 "Invalid";
VAL_ 911 FICMACRrTemDecSwReq 0 "FICMACRrTemDecSwReq_No_request" 1 "FICMACRrTemDecSwReq_Short_press" 2 "FICMACRrTemDecSwReq_Long_press";
VAL_ 911 FICMACRrTemIncSwReq 0 "FICMACRrTemIncSwReq_No_request" 1 "FICMACRrTemIncSwReq_Short_press" 2 "FICMACRrTemIncSwReq_Long_press";
VAL_ 911 FICMACRrTemReq 0 "FICMACRrTemReq_Lo" 30 "FICMACRrTemReq_High" 31 "FICMACRrTemReq_Reserved";
VAL_ 911 FICMACRrTemV 0 "Valid" 1 "Invalid";
VAL_ 911 FICMACRTemReq 0 "FICMACPsngTemReq_Lo" 30 "FICMACPsngTemReq_High" 31 "FICMACPsngTemReq_Reserved";
VAL_ 911 FICMACRTemV 0 "FICMACRTemV_0_Valid" 1 "FICMACRTemV_1_Invalid";
VAL_ 911 FICMACTemUnitChngReq 0 "FICMACTemUnitChngReq_No_request" 1 "FICMACTemUnitChngReq_Short_press" 2 "FICMACTemUnitChngReq_Long_press";
VAL_ 911 FICMClmOnOffSwReq 0 "FICMClmOnOffSwReq_No_request" 1 "FICMClmOnOffSwReq_Short_press" 2 "FICMClmOnOffSwReq_Long_press" 3 "FICMClmOnOffSwReq_Reversed";
VAL_ 911 FICMComprOnOffSwReq 0 "FICMComprOnOffSwReq_No_request" 1 "FICMComprOnOffSwReq_Short_press" 2 "FICMComprOnOffSwReq_Long_press";
VAL_ 911 FICMDfstOnSwReq 0 "FICMDfstOnSwReq_No_request" 1 "FICMDfstOnSwReq_Short_press" 2 "FICMDfstOnSwReq_Long_press";
VAL_ 911 FICMRrACAutoSwReq 0 "FICMRrACAutoSwReq_No_request" 1 "FICMRrACAutoSwReq_Short_Press" 2 "FICMRrACAutoSwReq_Long_Press" 3 "FICMRrACAutoSwReq_Reserved";
VAL_ 911 FICMRrACOnOffSwReq 0 "FICMRrACOnOffSwReq_No_request" 1 "FICMRrACOnOffSwReq_Short_Press" 2 "FICMRrACOnOffSwReq_Long_Press" 3 "FICMRrACOnOffSwReq_Reserved";
VAL_ 911 PwrLftgtPosSetngReqV 0 "Valid" 1 "Invalid";
VAL_ 911 PwrLftgtSysEnb 0 "False" 1 "True";
VAL_ 911 StrgCDMSSetngReq 0 "StrgCDMSSetngReq_0_Gear0" 1 "StrgCDMSSetngReq_1_Gear1" 2 "StrgCDMSSetngReq_2_Gear2" 3 "StrgCDMSSetngReq_3_Gear3" 4 "StrgCDMSSetngReq_4_Gear4" 5 "StrgCDMSSetngReq_5_Gear5" 6 "StrgCDMSSetngReq_6_Gear6" 7 "StrgCDMSSetngReq_7_Gear7" 8 "StrgCDMSSetngReq_8_Gear8" 9 "StrgCDMSSetngReq_9_Gear9" 10 "StrgCDMSSetngReq_10_Gear10" 11 "StrgCDMSSetngReq_11_Gear11" 12 "StrgCDMSSetngReq_12_Gear12" 13 "StrgCDMSSetngReq_13_Gear13" 14 "StrgCDMSSetngReq_14_Gear14" 15 "StrgCDMSSetngReq_15_Gear15" 16 "StrgCDMSSetngReq_16_Gear16" 17 "StrgCDMSSetngReq_17_Gear17" 18 "StrgCDMSSetngReq_18_Gear18" 19 "StrgCDMSSetngReq_19_Gear19" 20 "StrgCDMSSetngReq_20_Gear20" 21 "StrgCDMSSetngReq_21_Gear21" 22 "StrgCDMSSetngReq_22_Gear22" 23 "StrgCDMSSetngReq_23_Gear23" 24 "StrgCDMSSetngReq_24_Gear24" 25 "StrgCDMSSetngReq_25_Gear25" 26 "StrgCDMSSetngReq_26_Gear26" 27 "StrgCDMSSetngReq_27_Gear27" 28 "StrgCDMSSetngReq_28_Gear28" 29 "StrgCDMSSetngReq_29_Gear29" 30 "StrgCDMSSetngReq_30_Gear30" 31 "StrgCDMSSetngReq_31_Gear31" 32 "StrgCDMSSetngReq_32_Gear32" 33 "StrgCDMSSetngReq_33_Gear33" 34 "StrgCDMSSetngReq_34_Gear34" 35 "StrgCDMSSetngReq_35_Gear35" 36 "StrgCDMSSetngReq_36_Gear36" 37 "StrgCDMSSetngReq_37_Gear37" 38 "StrgCDMSSetngReq_38_Gear38" 39 "StrgCDMSSetngReq_39_Gear39" 40 "StrgCDMSSetngReq_40_Gear40" 41 "StrgCDMSSetngReq_41_Gear41" 42 "StrgCDMSSetngReq_42_Gear42" 43 "StrgCDMSSetngReq_43_Gear43" 44 "StrgCDMSSetngReq_44_Gear44" 45 "StrgCDMSSetngReq_45_Gear45" 46 "StrgCDMSSetngReq_46_Gear46" 47 "StrgCDMSSetngReq_47_Gear47" 48 "StrgCDMSSetngReq_48_Gear48" 49 "StrgCDMSSetngReq_49_Gear49" 50 "StrgCDMSSetngReq_50_Gear50" 51 "StrgCDMSSetngReq_51_Gear51" 52 "StrgCDMSSetngReq_52_Gear52" 53 "StrgCDMSSetngReq_53_Gear53" 54 "StrgCDMSSetngReq_54_Gear54" 55 "StrgCDMSSetngReq_55_Gear55" 56 "StrgCDMSSetngReq_56_Gear56" 57 "StrgCDMSSetngReq_57_Gear57" 58 "StrgCDMSSetngReq_58_Gear58" 59 "StrgCDMSSetngReq_59_Gear59" 60 "StrgCDMSSetngReq_60_Gear60" 61 "StrgCDMSSetngReq_61_Gear61" 62 "StrgCDMSSetngReq_62_Gear62" 63 "StrgCDMSSetngReq_63_Gear63" 64 "StrgCDMSSetngReq_64_Gear64" 65 "StrgCDMSSetngReq_65_Gear65" 66 "StrgCDMSSetngReq_66_Gear66" 67 "StrgCDMSSetngReq_67_Gear67" 68 "StrgCDMSSetngReq_68_Gear68" 69 "StrgCDMSSetngReq_69_Gear69" 70 "StrgCDMSSetngReq_70_Gear70" 71 "StrgCDMSSetngReq_71_Gear71" 72 "StrgCDMSSetngReq_72_Gear72" 73 "StrgCDMSSetngReq_73_Gear73" 74 "StrgCDMSSetngReq_74_Gear74" 75 "StrgCDMSSetngReq_75_Gear75" 76 "StrgCDMSSetngReq_76_Gear76" 77 "StrgCDMSSetngReq_77_Gear77" 78 "StrgCDMSSetngReq_78_Gear78" 79 "StrgCDMSSetngReq_79_Gear79" 80 "StrgCDMSSetngReq_80_Gear80" 81 "StrgCDMSSetngReq_81_Gear81" 82 "StrgCDMSSetngReq_82_Gear82" 83 "StrgCDMSSetngReq_83_Gear83" 84 "StrgCDMSSetngReq_84_Gear84" 85 "StrgCDMSSetngReq_85_Gear85" 86 "StrgCDMSSetngReq_86_Gear86" 87 "StrgCDMSSetngReq_87_Gear87" 88 "StrgCDMSSetngReq_88_Gear88" 89 "StrgCDMSSetngReq_89_Gear89" 90 "StrgCDMSSetngReq_90_Gear90" 91 "StrgCDMSSetngReq_91_Gear91" 92 "StrgCDMSSetngReq_92_Gear92" 93 "StrgCDMSSetngReq_93_Gear93" 94 "StrgCDMSSetngReq_94_Gear94" 95 "StrgCDMSSetngReq_95_Gear95" 96 "StrgCDMSSetngReq_96_Gear96" 97 "StrgCDMSSetngReq_97_Gear97" 98 "StrgCDMSSetngReq_98_Gear98" 99 "StrgCDMSSetngReq_99_Gear99" 100 "StrgCDMSSetngReq_100_Gear100" 101 "StrgCDMSSetngReq_101_Reserved" 102 "StrgCDMSSetngReq_102_Reserved" 103 "StrgCDMSSetngReq_103_Reserved" 104 "StrgCDMSSetngReq_104_Reserved" 105 "StrgCDMSSetngReq_105_Reserved" 106 "StrgCDMSSetngReq_106_Reserved" 107 "StrgCDMSSetngReq_107_Reserved" 108 "StrgCDMSSetngReq_108_Reserved" 109 "StrgCDMSSetngReq_109_Reserved" 110 "StrgCDMSSetngReq_110_Reserved" 111 "StrgCDMSSetngReq_111_Reserved" 112 "StrgCDMSSetngReq_112_Reserved" 113 "StrgCDMSSetngReq_113_Reserved" 114 "StrgCDMSSetngReq_114_Reserved" 115 "StrgCDMSSetngReq_115_Reserved" 116 "StrgCDMSSetngReq_116_Reserved" 117 "StrgCDMSSetngReq_117_Reserved" 118 "StrgCDMSSetngReq_118_Reserved" 119 "StrgCDMSSetngReq_119_Reserved" 120 "StrgCDMSSetngReq_120_Reserved" 121 "StrgCDMSSetngReq_121_Reserved" 122 "StrgCDMSSetngReq_122_Reserved" 123 "StrgCDMSSetngReq_123_Reserved" 124 "StrgCDMSSetngReq_124_Reserved" 125 "StrgCDMSSetngReq_125_Reserved" 126 "StrgCDMSSetngReq_126_Reserved" 127 "StrgCDMSSetngReq_127_Reserved";
VAL_ 911 StrgCDMSSetngReqV 0 "StrgCDMSSetngReqV_0_Valid" 1 "StrgCDMSSetngReqV_1_Invalid";
VAL_ 912 AmbtLghtCustSetngReq 0 "AmbtLghtCustSetngReq_Unavailable" 1 "AmbtLghtCustSetngReq_Super_ECO" 2 "AmbtLghtCustSetngReq_ECO" 3 "AmbtLghtCustSetngReq_Normal" 4 "AmbtLghtCustSetngReq_Sport" 5 "AmbtLghtCustSetngReq_Super_Sport";
VAL_ 912 AmbtLghtCustSetngReqV 0 "Valid" 1 "Invalid";
VAL_ 912 AmbtLghtDrvMdCustOnOffReq 0 "AmbtLghtDrvMdCustOnOffReq_No_Request" 1 "AmbtLghtDrvMdCustOnOffReq_Short_Press";
VAL_ 912 AmbtLghtDrvMdOnOffSwReq 0 "AmbtLghtDrvMdOnOffSwReq_No_Request" 1 "AmbtLghtDrvMdOnOffSwReq_Off" 2 "AmbtLghtDrvMdOnOffSwReq_On" 3 "AmbtLghtDrvMdOnOffSwReq_Auto";
VAL_ 912 AmbtLghtGlbOnOffSwReq 0 "AmbtLghtGlbOnOffSwReq_No_Request" 1 "AmbtLghtGlbOnOffSwReq_Short_Press";
VAL_ 912 AmbtLghtIgnMdOnOffSwReq 0 "AmbtLghtIgnMdOnOffSwReq_No_Request" 1 "AmbtLghtIgnMdOnOffSwReq_Short_Press";
VAL_ 912 AmbtLghtIgnMdReq 0 "AmbtLghtIgnMdReq_Mode_1" 1 "AmbtLghtIgnMdReq_Mode_2" 2 "AmbtLghtIgnMdReq_Mode_3" 3 "AmbtLghtIgnMdReq_Reserved1" 4 "AmbtLghtIgnMdReq_Reserved2" 5 "AmbtLghtIgnMdReq_Reserved3" 6 "AmbtLghtIgnMdReq_Reserved4" 7 "AmbtLghtIgnMdReq_Reserved5";
VAL_ 912 AmbtLghtIgnMdReqV 0 "Valid" 1 "Invalid";
VAL_ 912 AmbtLghtWlcmMdOnOffSwReq 0 "AmbtLghtWlcmMdOnOffSwReq_0_No_Request" 1 "AmbtLghtWlcmMdOnOffSwReq_1_Short_Press";
VAL_ 912 AmbtLghtWlcmMdReq 0 "AmbtLghtWlcmMdReq_Mode_1" 1 "AmbtLghtWlcmMdReq_Mode_2" 2 "AmbtLghtWlcmMdReq_Mode_3" 3 "AmbtLghtWlcmMdReq_Reserved1" 4 "AmbtLghtWlcmMdReq_Reserved2" 5 "AmbtLghtWlcmMdReq_Reserved3" 6 "AmbtLghtWlcmMdReq_Reserved4" 7 "AmbtLghtWlcmMdReq_Reserved5";
VAL_ 912 AmbtLghtWlcmMdReqV 0 "Valid" 1 "Invalid";
VAL_ 912 AmbtLghtZoneCtrlReq 0 "AmbtLghtZoneCtrlReq_0_only_door_light_is_on" 1 "AmbtLghtZoneCtrlReq_1_only_IPK_light_is_on" 2 "AmbtLghtZoneCtrlReq_2_All_lights_is_on" 3 "AmbtLghtZoneCtrlReq_3_Reserved" 4 "AmbtLghtZoneCtrlReq_4_Reserved" 5 "AmbtLghtZoneCtrlReq_5_Reserved" 6 "AmbtLghtZoneCtrlReq_6_Reserved" 7 "AmbtLghtZoneCtrlReq_7_Reserved";
VAL_ 912 AmbtLghtZoneCtrlReqV 0 "AmbtLghtZoneCtrlReqV_0_Valid" 1 "AmbtLghtZoneCtrlReqV_1_Invalid";
VAL_ 875 FaceIdficnAcutResult 0 "FaceIdficnAcutResult_0_unknown" 1 "FaceIdficnAcutResult_1_ID1" 2 "FaceIdficnAcutResult_2_ID2" 3 "FaceIdficnAcutResult_3_ID3" 4 "FaceIdficnAcutResult_4_ID4" 5 "FaceIdficnAcutResult_5_ID5" 6 "FaceIdficnAcutResult_6_ID6" 7 "FaceIdficnAcutResult_7_ID7" 8 "FaceIdficnAcutResult_8_ID8" 9 "FaceIdficnAcutResult_9_ID9" 10 "FaceIdficnAcutResult_10_ID10" 11 "FaceIdficnAcutResult_11_ID11" 12 "FaceIdficnAcutResult_12_ID12" 13 "FaceIdficnAcutResult_13_ID13" 14 "FaceIdficnAcutResult_14_ID14" 15 "FaceIdficnAcutResult_15_ID15" 16 "FaceIdficnAcutResult_16_ID16" 17 "FaceIdficnAcutResult_17_ID17" 18 "FaceIdficnAcutResult_18_ID18" 19 "FaceIdficnAcutResult_19_ID19" 20 "FaceIdficnAcutResult_20_ID20" 21 "FaceIdficnAcutResult_21_ID21" 22 "FaceIdficnAcutResult_22_ID22" 23 "FaceIdficnAcutResult_23_ID23" 24 "FaceIdficnAcutResult_24_ID24" 25 "FaceIdficnAcutResult_25_ID25" 26 "FaceIdficnAcutResult_26_ID26" 27 "FaceIdficnAcutResult_27_ID27" 28 "FaceIdficnAcutResult_28_ID28" 29 "FaceIdficnAcutResult_29_ID29" 30 "FaceIdficnAcutResult_30_ID30" 31 "FaceIdficnAcutResult_31_Reserve";
VAL_ 875 FICMDoorLckCtrlReq 0 "FICMDoorLckCtrlReq_No_Request" 1 "FICMDoorLckCtrlReq_Lock_Request" 2 "FICMDoorLckCtrlReq_Unlock_Request" 3 "FICMDoorLckCtrlReq_Reserved";
VAL_ 875 FICMDrvngMdSwReq 0 "FICMDrvngMdSwReq_0_Unavailable" 1 "FICMDrvngMdSwReq_1_Super_ECO" 2 "FICMDrvngMdSwReq_2_ECO" 3 "FICMDrvngMdSwReq_3_Normal" 4 "FICMDrvngMdSwReq_4_Sport" 5 "FICMDrvngMdSwReq_5_Super_Sport" 6 "FICMDrvngMdSwReq_6_Reserved" 7 "FICMDrvngMdSwReq_7_Customization_Mode";
VAL_ 875 FICMDrvngMdSwReqV 0 "FICMDrvngMdSwReqV_0_Valid" 1 "FICMDrvngMdSwReqV_1_Invalid";
VAL_ 875 FICMDrvrWndOpReq 0 "FICMDrvrWndOpReq_no_request" 1 "FICMDrvrWndOpReq_up_request" 2 "FICMDrvrWndOpReq_down_request" 3 "FICMDrvrWndOpReq_auto_up_request" 4 "FICMDrvrWndOpReq_auto_down_request" 5 "FICMDrvrWndOpReq_5_Reserved" 6 "FICMDrvrWndOpReq_6_Reserved" 7 "FICMDrvrWndOpReq_7_Reserved";
VAL_ 875 FICMFrtPsngWndOpReq 0 "FICMFrtPsngWndOpReq_no_request" 1 "FICMFrtPsngWndOpReq_up_request" 2 "FICMFrtPsngWndOpReq_down_request" 3 "FICMFrtPsngWndOpReq_auto_up_request" 4 "FICMFrtPsngWndOpReq_auto_down_request" 5 "FICMFrtPsngWndOpReq_5_Reserved" 6 "FICMFrtPsngWndOpReq_6_Reserved" 7 "FICMFrtPsngWndOpReq_7_Reserved";
VAL_ 875 FICMFrtWiperReq 0 "FICMFrtWiperReq_No_Request" 1 "FICMFrtWiperReq_Intermittent_Mode_Request" 2 "FICMFrtWiperReq_Slow_Mode_Request" 3 "FICMFrtWiperReq_Fast_Mode_Request" 4 "FICMFrtWiperReq_Flick_Mode_Request" 5 "FICMFrtWiperReq_5_Reserved" 6 "FICMFrtWiperReq_6_Reserved" 7 "FICMFrtWiperReq_7_Reserved";
VAL_ 875 FICMFrtWshReq 0 "FICMFrtWshReq_No_Request" 1 "FICMFrtWshReq_Wash_Request";
VAL_ 875 FICMHtdRrWndSwReq 0 "FICMHtdRrWndSwReq_No_request" 1 "FICMHtdRrWndSwReq_Short_press" 2 "FICMHtdRrWndSwReq_Long_press";
VAL_ 875 FICMKickSnsrLdspcEnbdReq 0 "FICMKickSnsrLdspcEnbdReq_0_No_Request" 1 "FICMKickSnsrLdspcEnbdReq_1_Enable" 2 "FICMKickSnsrLdspcEnbdReq_2_Inhibit";
VAL_ 875 FICMLdspcUnlckReq 0 "False" 1 "True";
VAL_ 875 FICMOtsdMirFoldReq 0 "No Request" 1 "Fold  Request" 2 "Unfold Request" 3 "FICMOtsdMirFoldReq_Reserved";
VAL_ 875 FICMRLWndOpReq 0 "FICMRLWndOpReq_no_request" 1 "FICMRLWndOpReq_up_request" 2 "FICMRLWndOpReq_down_request" 3 "FICMRLWndOpReq_auto_up_request" 4 "FICMRLWndOpReq_auto_down_request" 5 "FICMRLWndOpReq_5_Aeration" 6 "FICMRLWndOpReq_6_Reserved" 7 "FICMRLWndOpReq_7_Reserved";
VAL_ 875 FICMRrWiperReq 0 "FICMRrWiperReq_No_Request" 1 "FICMRrWiperReq_Intermittent_Mode_Request" 2 "FICMRrWiperReq_On_Request_Continuous_" 3 "FICMRrWiperReq_Off_Request";
VAL_ 875 FICMRRWndOpReq 0 "FICMRRWndOpReq_no_request" 1 "FICMRRWndOpReq_up_request" 2 "FICMRRWndOpReq_down_request" 3 "FICMRRWndOpReq_auto_up_request" 4 "FICMRRWndOpReq_auto_down_request" 5 "FICMRRWndOpReq_5_Reserved" 6 "FICMRRWndOpReq_6_Reserved" 7 "FICMRRWndOpReq_7_Reserved";
VAL_ 875 FICMRrWshReq 0 "FICMRrWshReq_No_Request" 1 "FICMRrWshReq_Wash_Request";
VAL_ 875 FICMSrfTiltReq 0 "FICMSrfTiltReq_No_Request" 1 "FICMSrfTiltReq_Tilt_Open" 2 "FICMSrfTiltReq_Tilt_Close" 3 "FICMSrfTiltReq_Reserved";
VAL_ 875 FICMVehStSpReq 0 "FICMVehStSpReq_No_Request" 1 "FICMVehStSpReq_Stop_Request" 2 "FICMVehStSpReq_Start_Request" 3 "FICMVehStSpReq_Reserved";
VAL_ 875 FICMVehStSpReqV 0 "Valid" 1 "Invalid";
VAL_ 875 FICMWiperOffReq 0 "FICMWiperOffReq_No_Request" 1 "FICMWiperOffReq_Off_Request_";
VAL_ 875 FICMWiperSpdCtrlReq 0 "FICMWiperSpdCtrlReq_No_Request" 1 "FICMWiperSpdCtrlReq_Faster_Request" 2 "FICMWiperSpdCtrlReq_Slower_Request" 3 "FICMWiperSpdCtrlReq_Reserved";
VAL_ 875 StorgMdSwReq 0 "StorgMdSwReq_0_No_Request" 1 "StorgMdSwReq_1_On_Request" 2 "StorgMdSwReq_2_Off_Request" 3 "StorgMdSwReq_3_Reseved";
VAL_ 875 WlcmFnCustSetngReq 0 "WlcmFnCustSetngReq_0_No_Request" 1 "WlcmFnCustSetngReq_1_Short_Press_Request" 2 "WlcmFnCustSetngReq_2_Long_Rewss" 3 "WlcmFnCustSetngReq_3_Reserved";
VAL_ 930 AutoLaneChngstyle 0 "AutoLaneChngstyle_0_no_request" 1 "AutoLaneChngstyle_1_comfortable" 2 "AutoLaneChngstyle_2_dynamic";
VAL_ 930 EHCSwReq 0 "EHCSwReq_0_no_request" 1 "EHCSwReq_1_off" 2 "EHCSwReq_2_on" 3 "EHCSwReq_3_reserved";
VAL_ 930 IntlgntDrvMdSwReq 0 "IntlgntDrvMdSwReq_0_no_request" 1 "IntlgntDrvMdSwReq_1_off" 2 "IntlgntDrvMdSwReq_2_on" 3 "IntlgntDrvMdSwReq_3_reserved";
VAL_ 930 NavCrntRoadTyp 0 "NavCrntRoadTyp_Unknown" 1 "NavCrntRoadTyp_Highway" 2 "NavCrntRoadTyp_interurban_roads" 3 "NavCrntRoadTyp_City_roads" 4 "NavCrntRoadTyp_Ramp" 5 "NavCrntRoadTyp_National_road" 6 "NavCrntRoadTyp_Provincial_road" 7 "NavCrntRoadTyp_County_road" 8 "NavCrntRoadTyp_Village_road" 9 "NavCrntRoadTyp_City_express_way" 10 "NavCrntRoadTyp_Major_urban_road" 11 "NavCrntRoadTyp_Secondary_urban_road" 12 "NavCrntRoadTyp_Normal_urban_road" 13 "NavCrntRoadTyp_Non_Navigation_Road" 14 "NavCrntRoadTyp_14_Reserve" 15 "NavCrntRoadTyp_15_Reserve";
VAL_ 930 NavDistFromFrtEleccEye 0 "NavDistFromFrtEleccEye_0_no_SLC_ahead" 61 "NavDistFromFrtEleccEye_61_over_6_0km" 62 "NavDistFromFrtEleccEye_62_not_used" 63 "NavDistFromFrtEleccEye_63_not_used";
VAL_ 930 NavItvalSpdDetnRetDist 0 "NavItvalSpdDetnRetDist_not_in_ISD" 251 "NavItvalSpdDetnRetDist_over_70km";
VAL_ 930 NavNewIcon 0 "NavNewIcon_unknown" 1 "NavNewIcon_left" 2 "NavNewIcon_right" 3 "NavNewIcon_left_front" 4 "NavNewIcon_right_front" 5 "NavNewIcon_left_rear" 6 "NavNewIcon_right_rear" 7 "NavNewIcon_left_u_turn" 8 "NavNewIcon_right_u_turn" 9 "NavNewIcon_go_straight" 10 "NavNewIcon_roundabout_entrance" 11 "NavNewIcon_roundabout_exit" 12 "NavNewIcon_service_area" 13 "NavNewIcon_toll_station" 14 "NavNewIcon_tunnel" 15 "NavNewIcon_not_used";
VAL_ 930 NavNewIconDist 0 "NavNewIconDist_no_newIcon_ahead" 21 "NavNewIconDist_over_2_km";
VAL_ 930 NOPActvdSwReq 0 "NOPActvdSwReq_0_no_request" 1 "NOPActvdSwReq_1_request" 2 "NOPActvdSwReq_2_Reserved" 3 "NOPActvdSwReq_3_Reserved";
VAL_ 930 NOPVcRmndrSwReq 0 "NOPVcRmndrSwReq_0_no_request" 1 "NOPVcRmndrSwReq_1_standard" 2 "NOPVcRmndrSwReq_2_simple" 3 "NOPVcRmndrSwReq_3_silence";
VAL_ 930 SCMSuspMdReq 0 "SCMSuspMdReq_0_Function_Disable" 1 "SCMSuspMdReq_1_Comfortable_Mode" 2 "SCMSuspMdReq_2_Normal_Mode" 3 "SCMSuspMdReq_3_Sport_Mode";
VAL_ 930 SCMSuspMdReqV 0 "SCMSuspMdReqV_0_Valid" 1 "SCMSuspMdReqV_1_Invalid";
VAL_ 931 FICMEcoDrvngSwA 0 "False" 1 "True";
VAL_ 931 FICMEcoDrvngSwAV 0 "Valid" 1 "Invalid";
VAL_ 931 LDWLKASwReq 0 "LDWLKASwReq_0_no_request" 1 "LDWLKASwReq_1_off" 2 "LDWLKASwReq_2_LDW" 3 "LDWLKASwReq_3_LDP" 4 "LDWLKASwReq_4_LKA" 5 "LDWLKASwReq_5_ELK" 6 "LDWLKASwReq_6_Reserved" 7 "LDWLKASwReq_7_Reserved";
VAL_ 931 NavSpdLmtTyp 0 "NavSpdLmtTyp_not_specific" 1 "NavSpdLmtTyp_camera_detection" 2 "NavSpdLmtTyp_Interval_speed_detection";
VAL_ 931 NavSpdLmtValSts 0 "NavSpdLmtValSts_Fault" 1 "NavSpdLmtValSts_Inactive" 2 "NavSpdLmtValSts_Active";
VAL_ 931 NavSpdLmtValUnit 0 "NavSpdLmtValUnit_Unknown" 1 "NavSpdLmtValUnit_MPH" 2 "NavSpdLmtValUnit_KMH" 3 "NavSpdLmtValUnit_Reserved";
VAL_ 931 PtCustSetngReq 0 "PtCustSetngReq_Unavailable" 1 "PtCustSetngReq_Super_ECO" 2 "PtCustSetngReq_ECO" 3 "PtCustSetngReq_Normal" 4 "PtCustSetngReq_Sport" 5 "PtCustSetngReq_Super_Sport" 6 "PtCustSetngReq_6_Reserved" 7 "PtCustSetngReq_7_Reserved";
VAL_ 931 PtCustSetngReqV 0 "PtCustSetngReqV_valid" 1 "PtCustSetngReqV_invalid";
VAL_ 931 SpdAstMdFICM 0 "SpdAstMdFICM_Off" 1 "SpdAstMdFICM_SLIF" 2 "SpdAstMdFICM_MSA" 3 "SpdAstMdFICM_ISA";
VAL_ 931 SpdAstMdFICMV 0 "Valid" 1 "Invalid";
VAL_ 931 StrgCustSetngReq 0 "StrgCustSetngReq_0_Unavailable" 1 "StrgCustSetngReq_1_Comfortable_Mode" 2 "StrgCustSetngReq_2_Normal_Mode" 3 "StrgCustSetngReq_3_Sport_Mode";
VAL_ 931 StrgCustSetngReqV 0 "StrgCustSetngReqV_0_Valid" 1 "StrgCustSetngReqV_1_Invalid";
VAL_ 931 TrCustSetngReq 0 "TrCustSetngReq_0_Unavailable" 1 "TrCustSetngReq_1_Super ECO" 2 "TrCustSetngReq_2_ECO" 3 "TrCustSetngReq_3_Normal" 4 "TrCustSetngReq_4_Sport" 5 "TrCustSetngReq_5_Super_Sport" 6 "TrCustSetngReq_6_Reserved" 7 "TrCustSetngReq_7_Reserved";
VAL_ 931 TrCustSetngReqV 0 "Valid" 1 "Invalid";
VAL_ 913 ACUserCustSetngReq 0 "ACUserCustSetngReq_Unavailable" 1 "ACUserCustSetngReq_Economy_Mode" 2 "ACUserCustSetngReq_Normal_Mode" 3 "ACUserCustSetngReq_Reserved";
VAL_ 913 ACUserCustSetngReqV 0 "ACUserCustSetngReqV_Valid" 1 "ACUserCustSetngReqV_Invalid";
VAL_ 913 FICMACDrvrAirMdReq 0 "FICMACDrvrAirMdReq_0_face" 1 "FICMACDrvrAirMdReq_1_face_foot" 2 "FICMACDrvrAirMdReq_2_foot" 3 "FICMACDrvrAirMdReq_3_foot_defrost" 4 "FICMACDrvrAirMdReq_4_defrost" 5 "FICMACDrvrAirMdReq_5_face_foot_defrost" 6 "FICMACDrvrAirMdReq_6_face_defrost" 7 "FICMACDrvrAirMdReq_7_No_Command_air_distribute_mode";
VAL_ 913 FICMACDrvrAirMdReqV 0 "Valid" 1 "Invalid";
VAL_ 913 FICMACDrvrTemReq 0 "FICMACDrvrTemReq_0_Lo" 30 "FICMACDrvrTemReq_30_High" 31 "FICMACDrvrTemReq_31_Reserved";
VAL_ 913 FICMACPsngAirMdSwReq 0 "FICMACPsngAirMdSwReq_0_No_request" 1 "FICMACPsngAirMdSwReq_1_Short_press" 2 "FICMACPsngAirMdSwReq_2_Long_press";
VAL_ 913 FICMACPsngTemReq 0 "FICMACPsngTemReq_0_Lo" 30 "FICMACPsngTemReq_30_High" 31 "FICMACPsngTemReq_31_Reserved";
VAL_ 913 FICMAirClnrBlwrLvlReq 0 "FICMAirClnrBlwrLvlReq_Blower_off" 1 "FICMAirClnrBlwrLvlReq_1_level" 2 "FICMAirClnrBlwrLvlReq_2_level" 3 "FICMAirClnrBlwrLvlReq_3_level" 4 "FICMAirClnrBlwrLvlReq_4_level" 5 "FICMAirClnrBlwrLvlReq_5_level" 6 "FICMAirClnrBlwrLvlReq_6_level" 7 "FICMAirClnrBlwrLvlReq_7_level";
VAL_ 913 FICMAirClnrBlwrLvlReqV 0 "Valid" 1 "Invalid";
VAL_ 913 FICMAirClnrBlwrSpdDecSwReq 0 "FICMAirClnrBlwrSpdDecSwReq_No_request" 1 "FICMAirClnrBlwrSpdDecSwReq_short_press" 2 "FICMAirClnrBlwrSpdDecSwReq_long_press" 3 "FICMAirClnrBlwrSpdDecSwReq_3_reserved";
VAL_ 913 FICMAirClnrBlwrSpdIncSwReq 0 "FICMAirClnrBlwrSpdIncSwReq_No_request" 1 "FICMAirClnrBlwrSpdIncSwReq_short_press" 2 "FICMAirClnrBlwrSpdIncSwReq_long_press" 3 "FICMAirClnrBlwrSpdIncSwReq_3_reserved";
VAL_ 913 FICMASSInhSwA 0 "False" 1 "True";
VAL_ 913 FICMASSInhV 0 "Valid" 1 "Invalid";
VAL_ 913 FICMBrkLghtReq 0 "FICMBrkLghtReq_No_Request" 1 "FICMBrkLghtReq_Off_Request" 2 "FICMBrkLghtReq_On_Request" 3 "FICMBrkLghtReq_Reserved";
VAL_ 913 FICMCotsyLghtReq 0 "FICMCotsyLghtReq_No_Request" 1 "FICMCotsyLghtReq_Off_Request" 2 "FICMCotsyLghtReq_On_Request" 3 "FICMCotsyLghtReq_Reserved";
VAL_ 913 FICMDipdBeamLghtReq 0 "FICMDipdBeamLghtReq_No_Request" 1 "FICMDipdBeamLghtReq_Off_Request" 2 "FICMDipdBeamLghtReq_On_Request" 3 "FICMDipdBeamLghtReq_Reserved";
VAL_ 913 FICMDipdBeamLghtReqV 0 "Valid" 1 "Invalid";
VAL_ 913 FICMDircnIndLghtReq 0 "FICMDircnIndLghtReq_0_No_Request" 1 "FICMDircnIndLghtReq_1_Off_Request" 2 "FICMDircnIndLghtReq_2_Left_DI_On_Request" 3 "FICMDircnIndLghtReq_3_Right_DI_On_Request" 4 "FICMDircnIndLghtReq_4_Hazard_On_Request";
VAL_ 913 FICMFLSeatHeatSwReq 0 "FICMFLSeatHeatSwReq_No_request" 1 "FICMFLSeatHeatSwReq_short_press" 2 "FICMFLSeatHeatSwReq_long_press";
VAL_ 913 FICMFRSeatHeatSwReq 0 "FICMFRSeatHeatSwReq_No_request" 1 "FICMFRSeatHeatSwReq_Short_press" 2 "FICMFRSeatHeatSwReq_Long_press";
VAL_ 913 FICMFrtFogLghtReq 0 "FICMFrtFogLghtReq_No_Request" 1 "FICMFrtFogLghtReq_Off_Request" 2 "FICMFrtFogLghtReq_On_Request" 3 "FICMFrtFogLghtReq_Reserved";
VAL_ 913 FICMMainBeamLghtReq 0 "FICMMainBeamLghtReq_No_Request" 1 "FICMMainBeamLghtReq_Off_Request" 2 "FICMMainBeamLghtReq_On_Request" 3 "FICMMainBeamLghtReq_Reserved";
VAL_ 913 FICMRevsLghtReq 0 "FICMRevsLghtReq_No_Request" 1 "FICMRevsLghtReq_Off_Request" 2 "FICMRevsLghtReq_On_Request" 3 "FICMRevsLghtReq_Reserved";
VAL_ 913 FICMRrFogLghtReq 0 "FICMRrFogLghtReq_No_Request" 1 "FICMRrFogLghtReq_Off_Request" 2 "FICMRrFogLghtReq_On_Request" 3 "FICMRrFogLghtReq_Reserved";
VAL_ 913 HDCReq 0 "HDCReq_Norequest" 1 "HDCReq_ActiveHDC" 2 "HDCReq_DeactiveHDC" 3 "HDCReq_PressedHDCButton";
VAL_ 913 RstrFctryDeftsReq 0 "False" 1 "True";
VAL_ 1130 FICMWhlTypMontrRstReq 0 "False" 1 "True";
VAL_ 1351 DrvrHdrtSpkrSndFldAdjReq 0 "DrvrHdrtSpkrSndFldAdjReq_Level_1" 1 "DrvrHdrtSpkrSndFldAdjReq_Level_2" 2 "DrvrHdrtSpkrSndFldAdjReq_Level_3" 3 "DrvrHdrtSpkrSndFldAdjReq_Level_4" 4 "DrvrHdrtSpkrSndFldAdjReq_Level_5" 5 "DrvrHdrtSpkrSndFldAdjReq_Level_6" 6 "DrvrHdrtSpkrSndFldAdjReq_6_Reserved" 7 "DrvrHdrtSpkrSndFldAdjReq_7_Reserved";
VAL_ 1351 DrvrHdrtSpkrSndFldAdjReqV 0 "DrvrHdrtSpkrSndFldAdjReqV_Valid" 1 "DrvrHdrtSpkrSndFldAdjReqV_Invalid";
VAL_ 1351 DrvrHdrtSpkrSndFldOnOffReq 0 "False" 1 "True";
VAL_ 1351 DrvrHdrtSpkrSndFldOnOffReqV 0 "DrvrHdrtSpkrSndFldOnOffReqV_Valid" 1 "DrvrHdrtSpkrSndFldOnOffReqV_Invalid";
VAL_ 1352 NavSts 0 "NavSts_0_Cruise" 1 "NavSts_1_navigation" 2 "NavSts_2_invalid";
VAL_ 820 ACUserCustAftRunOnOffR 0 "ACUserCustAftRunOnOffR_0_off" 1 "ACUserCustAftRunOnOffR_1_on";
VAL_ 820 ACUserCustAftRunOnOffReqV 0 "Valid" 1 "Invalid";
VAL_ 820 ACUserCustAirQultEnbReq 0 "Low_sensitivity" 1 "High_sensitivity" 2 "Close" 3 "Reserved";
VAL_ 820 ACUserCustAirQultEnbReqV 0 "Valid" 1 "Invalid";
VAL_ 820 ACUserCustAutoMdBlwrReq 0 "High_level" 1 "Middle_level" 2 "Low_level" 3 "Reserved";
VAL_ 820 ACUserCustAutoMdBlwrReqV 0 "Valid" 1 "Invalid";
VAL_ 820 ACUserCustAutoMdTemReq 0 "ACUserCustAutoMdTemReq_0_Cool" 1 "ACUserCustAutoMdTemReq_1_Standard" 2 "ACUserCustAutoMdTemReq_2_Hot" 3 "ACUserCustAutoMdTemReq_3_Reserved";
VAL_ 820 ACUserCustAutoMdTemReqV 0 "Valid" 1 "Invalid";
VAL_ 820 ACUserCustBlwrAutoRunRmtUnlckReq 0 "off" 1 "on";
VAL_ 820 ACUserCustBlwrAutoRunRmtUnlckReqV 0 "Valid" 1 "Invalid";
VAL_ 820 ACUserCustCofignReq 0 "ACUserCustCofignReq_No_User_Configuration" 1 "ACUserCustCofignReq_Configuration_1" 2 "ACUserCustCofignReq_Configuration_2" 3 "ACUserCustCofignReq_Configuration_3";
VAL_ 820 ACUserCustCofignReqV 0 "Valid" 1 "Invalid";
VAL_ 820 ACUserCustFltrLifeRmndReq 0 "off" 1 "on";
VAL_ 820 ACUserCustFltrLifeRmndReqV 0 "Valid" 1 "Invalid";
VAL_ 820 ACUserCustFrtAutoDmstngReq 0 "off" 1 "on";
VAL_ 820 ACUserCustFrtAutoDmstngReqV 0 "Valid" 1 "Invalid";
VAL_ 820 ACUserCustRmtStOnOffReq 0 "off" 1 "on";
VAL_ 820 ACUserCustRmtStOnOffReqV 0 "Valid" 1 "Invalid";
VAL_ 820 ACUserCustRrAutoDmstngReq 0 "ACUserCustRrAutoDmstngReq_0_On" 1 "ACUserCustRrAutoDmstngReq_1_Off" 2 "ACUserCustRrAutoDmstngReq_2_Same_with_front_auto_demisting" 3 "ACUserCustRrAutoDmstngReq _Reverse";
VAL_ 820 ACUserCustRrAutoDmstngReqV 0 "Valid" 1 "Invalid";
VAL_ 820 ACUserCustRrZoneCofignReq 0 "Rear_Zone_off" 1 "Same_to_front_zone" 2 "Last_Configuration" 3 "Reserved";
VAL_ 820 ACUserCustRrZoneCofignReqV 0 "Valid" 1 "Invalid";
VAL_ 820 ACUserCustStSpMdReq 0 "ACUserCustStSpMdReq_Comfort_mode" 1 "ACUserCustStSpMdReq_Economy_mode";
VAL_ 820 ACUserCustStSpMdReqV 0 "Valid" 1 "Invalid";
VAL_ 820 ACUserCustTemUnitReq 0 "ACUserCustTemUnitReq_0_Fahrenheit" 1 "ACUserCustTemUnitReq_1_Celsius";
VAL_ 820 ACUserCustTemUnitReqV 0 "Valid" 1 "Invalid";
VAL_ 820 ACUserCustZoneCofignReq 0 "Unification" 1 "Separation" 2 "Last_Configuration" 3 "Reserved";
VAL_ 820 ACUserCustZoneCofignReqV 0 "Valid" 1 "Invalid";
VAL_ 820 AirClnrUserCustAutoRR 0 "AirClnrUserCustAutoRR_Off" 1 "AirClnrUserCustAutoRR_On";
VAL_ 820 AirClnrUserCustAutoRRV 0 "Valid" 1 "Invalid";
VAL_ 820 FICMAirClnrAutoSwReq 0 "FICMAirClnrAutoSwReq_No_request" 1 "FICMAirClnrAutoSwReq_short_press" 2 "FICMAirClnrAutoSwReq_long_press" 3 "FICMAirClnrAutoSwReq_3_reserved";
VAL_ 820 FICMAirClnrFltrCsumLvlRstSwReq 0 "FICMAirClnrFltrCsumLvlRstSwReq_No_request" 1 "FICMAirClnrFltrCsumLvlRstSwReq_short_press" 2 "FICMAirClnrFltrCsumLvlRstSwReq_long_press" 3 "FICMAirClnrFltrCsumLvlRstSwReq_reserved";
VAL_ 820 FICMAirClnrIonizerSwR 0 "FICMAirClnrIonizerSwR_No_request" 1 "FICMAirClnrIonizerSwR_short_press" 2 "FICMAirClnrIonizerSwR_long_press" 3 "FICMAirClnrIonizerSwR_3_reserved";
VAL_ 820 FICMAirClnrOnOffSwReq 0 "FICMAirClnrOnOffSwReq_No_request" 1 "FICMAirClnrOnOffSwReq_short_press" 2 "FICMAirClnrOnOffSwReq_long_press" 3 "FICMAirClnrOnOffSwReq_reserved";
VAL_ 820 InsdAirPrtclMtrCncntrnSwReq 0 "InsdAirPrtclMtrCncntrnSwReq_No_Request" 1 "InsdAirPrtclMtrCncntrnSwReq_Short_Press" 2 "InsdAirPrtclMtrCncntrnSwReq_Long_Press" 3 "InsdAirPrtclMtrCncntrnSwReq_Reserved";
VAL_ 690 APASwReq 0 "APASwReq_0_No_request" 1 "APASwReq_1_Short_press" 2 "APASwReq_2_Long_press" 3 "APASwReq_3_Reserved";
VAL_ 690 AVMCalMdReq 0 "AVMCalMdReq_0_NoRequest" 1 "AVMCalMdReq_1_AutoCalRequest" 2 "AVMCalMdReq_2_ManualCalRequest" 3 "AVMCalMdReq_3_reserved";
VAL_ 690 FICMCCSwCCA 0 "FICMCCSwCCA_0_Cruise_control_OFF" 1 "FICMCCSwCCA_1_Cruise_control_Active";
VAL_ 690 FICMCCSwCCAV 0 "Valid" 1 "Invalid";
VAL_ 690 FrtAndRrGudOvlyDspReq 0 "FrtAndRrGudOvlyDspReq_No_Request" 1 "FrtAndRrGudOvlyDspReq_No_guide_Overlay" 2 "FrtAndRrGudOvlyDspReq_Static_Guide_Overlay" 3 "FrtAndRrGudOvlyDspReq_Dynamic_Guide_Overlay" 4 "FrtAndRrGudOvlyDspReq_Dynamic_Both" 5 "FrtAndRrGudOvlyDspReq_Dynamic_5_Reserved" 6 "FrtAndRrGudOvlyDspReq_Dynamic_6_Reserved" 7 "FrtAndRrGudOvlyDspReq_Dynamic_7_Reserved";
VAL_ 690 LOtsdMirSeldSwA 0 "False" 1 "True";
VAL_ 690 OtsdMirFoldSwReq 0 "OtsdMirFoldSwReq_0_No_Operation" 1 "OtsdMirFoldSwReq_1_Outside_Mirror_Fold" 2 "OtsdMirFoldSwReq_2_Outside_Mirror_Unfold";
VAL_ 690 OtsdMirSWSFnA 0 "False" 1 "True";
VAL_ 690 PDCSwReq 0 "PDCSwReq_No_request" 1 "PDCSwReq_Short_press" 2 "PDCSwReq_Long_press" 3 "PDCSwReq_Reserved";
VAL_ 690 PDCSysEnbReq 0 "PDCSysEnbReq_Disable_request" 1 "PDCSysEnbReq_Enable_request";
VAL_ 690 PDCSysEnbReqV 0 "PDCSysEnbReqV_valid" 1 "PDCSysEnbReqV_invalid";
VAL_ 690 ROtsdMirSeldSwA 0 "False" 1 "True";
VAL_ 690 SpdAstReqStsNav 0 "SpdAstReqStsNav_Fault" 1 "SpdAstReqStsNav_Undefined" 2 "SpdAstReqStsNav_Active";
VAL_ 690 SurndViewSeln 0 "SurndViewSeln_No_request" 1 "SurndViewSeln_front_view" 2 "SurndViewSeln_front_view_wide" 3 "SurndViewSeln_Rear_view" 4 "SurndViewSeln_Rear_view_wide" 5 "left_right_view_wide" 6 "SurndViewSeln_front_left_view_3D_" 7 "SurndViewSeln_front_right_view_3D_" 8 "SurndViewSeln_rear_left_view_3D_" 9 "SurndViewSeln_rear_right_view_3D_" 10 "SurndViewSeln_full_screen" 11 "SurndViewSeln_Left_View" 12 "SurndViewSeln_Right_View" 13 "SurndViewSeln_Reserved3" 14 "SurndViewSeln_Reserved4" 15 "SurndViewSeln_Reserved5";
VAL_ 690 ThreeDimnlDspReq 0 "ThreeDimnlDspReq_unavailable" 1 "2D" 2 "3D" 3 "ThreeDimnlDspReq_Reserved";
VAL_ 895 ACCTJAMdSwReq 0 "ACCTJAMdSwReq_0_no_request" 1 "ACCTJAMdSwReq_1_ACC" 2 "ACCTJAMdSwReq_2_TJA" 3 "ACCTJAMdSwReq_3_SHWA" 4 "ACCTJAMdSwReq_4_Off" 5 "ACCTJAMdSwReq_5_NOP" 6 "ACCTJAMdSwReq_6_Reserved" 7 "ACCTJAMdSwReq_7_Reserved";
VAL_ 895 AEBSwReq 0 "AEBSwReq_0_no_request" 1 "AEBSwReq_1_off" 2 "AEBSwReq_2_on" 3 "AEBSwReq_3_reserved";
VAL_ 895 AutoLaneChngSwReq 0 "AutoLaneChngSwReq_0_norequest" 1 "AutoLaneChngSwReq_1_off" 2 "AutoLaneChngSwReq_2_lanechangesuggestion" 3 "AutoLaneChngSwReq_3_ALCwithdriver" 4 "AutoLaneChngSwReq_4_ALCwithoutdriver_Reserved_" 5 "AutoLaneChngSwReq_5_Reserved" 6 "AutoLaneChngSwReq_6_Reserved" 7 "AutoLaneChngSwReq_7_Reserved";
VAL_ 895 BSDSelReq 0 "BSDSelReq_no_request" 1 "BSDSelReq_driver_switch_off_request" 2 "BSDSelReq_driver_switch_on_request" 3 "BSDSelReq_4_reserve";
VAL_ 895 DOWSelReq 0 "DOWSelReq_no_request" 1 "DOWSelReq_driver_switch_off_request" 2 "DOWSelReq_driver_switch_on_request" 3 "DOWSelReq_reserve";
VAL_ 895 FCTSysSelReq 0 "FCTSysSelReq_0_no_request" 1 "FCTSysSelReq_1_driver_switch_FCTA_off_request" 2 "FCTSysSelReq_2_driver_switch_FCTA_on_request" 3 "FCTSysSelReq_3_driver_switch_FCTB_FCTA_on_request";
VAL_ 895 FCWSnstvtLvlReq 0 "FCWSnstvtLvlReq_no_request" 1 "FCWSnstvtLvlReq_level1_low_" 2 "FCWSnstvtLvlReq_level2_middle_" 3 "FCWSnstvtLvlReq_level3_high_" 4 "FCWSnstvtLvl_Radar_4_reserved" 5 "FCWSnstvtLvl_Radar_5_reserved" 6 "FCWSnstvtLvl_Radar_6_reserved" 7 "FCWSnstvtLvl_Radar_7_reserved";
VAL_ 895 FCWSwReq 0 "FCWSwReq_no_request" 1 "FCWSwReq_off" 2 "FCWSwReq_on" 3 "FCWSwReq_reserved";
VAL_ 895 FICMSCSMdReq 0 "FICMSCSMdReq_No_Request" 1 "FICMSCSMdReq_Request" 2 "FICMSCSMdReq_Reserve1" 3 "FICMSCSMdReq_Reserve2";
VAL_ 895 LCASelReq 0 "LCASelReq_no_request" 1 "LCASelReq_driver_switch_off_request" 2 "LCASelReq_driver_switch_on_request" 3 "LCASelReq_reserve";
VAL_ 895 LDWAdoWrnngReq 0 "LDWAdoWrnngReq_no_request" 1 "LDWAdoWrnngReq_off" 2 "LDWAdoWrnngReq_on" 3 "LDWAdoWrnngReq_reserved";
VAL_ 895 LDWLKAHptWrnngReq 0 "LDWLKAHptWrnngReq_no_request" 1 "LDWLKAHptWrnngReq_off" 2 "LDWLKAHptWrnngReq_on" 3 "LDWLKAHptWrnngReq_reserved";
VAL_ 895 LDWSnstvtLvlReq 0 "LDWSnstvtLvlReq_no_request" 1 "Low" 2 "Standard" 3 "High";
VAL_ 895 NOPSwReq 0 "NOPSwReq_0_No_Request" 1 "NOPSwReq_1_off" 2 "NOPSwReq_2_NOP_NdConfirm" 3 "NOPSwReq_3_NOP_NotNdConfirm" 4 "NOPSwReq_4_Reserved" 5 "NOPSwReq_5_Reserved" 6 "NOPSwReq_6_Reserved" 7 "NOPSwReq_7_Reserved";
VAL_ 895 RCTSysSelReq 0 "RCTSysSelReq_no_request" 1 "RCTSysSelReq_driver_switch_RCTA_off_request" 2 "RCTSysSelReq_driver_switch_RCTA_on_request" 3 "RCTSysSelReq_driver_switch_RCTB(&RCTA)_on_request";
VAL_ 895 RCWSelReq 0 "RCWSelReq_no_request" 1 "RCWSelReq_driver_switch_off_request" 2 "RCWSelReq_driver_switch_on_request" 3 "RCWSelReq_reserve";
VAL_ 895 RDASwReq 0 "RDASwReq_no_request" 1 "RDASwReq_driver_switch_off_request" 2 "RDASwReq_driver_switch_on_request" 3 "RDASwReq_reserve";
VAL_ 895 SLIFWrnngStsReq 0 "SLIFWrnngStsReq_0_SLIF_ON" 1 "SLIFWrnngStsReq_1_SLIF_Off";
VAL_ 895 SLIFWrnngStsReqV 0 "SLIFWrnngStsReqV_0_Valid" 1 "SLIFWrnngStsReqV_1_Invalid";
VAL_ 895 TJAICASwReq 0 "TJAICASwReq_no_request" 1 "TJAICASwReq_off" 2 "TJAICASwReq_on" 3 "TJAICASwReq_reserved";
VAL_ 1347 LanggSetngAdj 0 "LanggSetngAdj_Simplified_Chinese" 1 "LanggSetngAdj_UK_English" 2 "LanggSetngAdj_NA_English" 3 "Swedish" 4 "French" 5 "Spanish" 6 "Dutch" 7 "Portuguese" 8 "Norwegian" 9 "Finnish" 10 "Danish" 11 "Greek" 12 "Japanese" 13 "Arabic" 14 "German" 15 "Polish" 16 "Turkish" 17 "Korean" 18 "LanggSetngAdj_Traditional_Chinese" 19 "Italian" 20 "Hungarian" 21 "Czech" 22 "Slovak" 23 "Russian" 24 "Thai";
VAL_ 797 NavDircn 0 "NavDircn_0_SelfCar_Logo" 1 "NavDircn_1_turn_Left" 2 "NavDircn_2_turn_Right" 3 "NavDircn_3_Left_Head" 4 "NavDircn_4_right_Head" 5 "NavDircn_5_Left_After" 6 "NavDircn_6_Right_After" 7 "NavDircn_7_Back" 8 "NavDircn_8_Driver_Straight" 9 "NavDircn_9_Arrive_Middle_Pointer" 10 "NavDircn_10_into_Circle_Zone" 11 "NavDircn_11_Out_Cirle_Zone" 12 "NavDircn_12_Arrive_Srvice_Zone" 13 "NavDircn_13_Arrive_Toll_Station" 14 "NavDircn_14_Arrive_the_Destination" 15 "NavDircn_15_into_tube" 63 "NavDircn_63_invalid";
VAL_ 797 NavDist 32767 "NavDist_32767_invalid";
VAL_ 797 NavDistUnit 0 "NavDistUnit_0_m" 1 "NavDistUnit_1_0.1_km";
VAL_ 730 DrvrSeatPositionRecallReq 0 "DrvrSeatPositionRecallReq_0_NoRequest" 1 "DrvrSeatPositionRecallReq_1_SeatPositionRecallRequest";
VAL_ 730 FrtPsngAirbagSwStsReq 0 "FrtPsngAirbagSwStsReq_0_Passenger_Airbag_OFF" 1 "FrtPsngAirbagSwStsReq_1_Passenger_Airbag_ON";
VAL_ 730 FrtPsngAirbagSwStsReqV 0 "False" 1 "True";
VAL_ 767 AVMDspReqResp 0 "AVMDspReqResp_0_norequest" 1 "AVMDspReqResp_1_open" 2 "AVMDspReqResp_2_close" 3 "AVMDspReqResp_3_reserve";
VAL_ 767 AVMDspSwReq 0 "AVMDspSwReq_0_norequest" 1 "AVMDspSwReq_1_Open" 2 "AVMDspSwReq_2_Close" 3 "AVMDspSwReq_3_Reserved";
VAL_ 767 BleCmftLckSet 0 "BleCmftLckSet_0_NoRequest" 1 "BleCmftLckSet_1_OFF" 2 "BleCmftLckSet_2_ON" 3 "BleCmftLckSet_3_Reserved";
VAL_ 767 BleCmftUnlckSet 0 "BleCmftUnlckSet_0_NoRequest" 1 "BleCmftUnlckSet_1_OFF" 2 "BleCmftUnlckSet_2_DriverOnly" 3 "BleCmftUnlckSet_3_AllDoor";
VAL_ 767 BleWlcmFnSet 0 "BleWlcmFnSet_0_NoRequest" 1 "BleWlcmFnSet_1_OFF" 2 "BleWlcmFnSet_2_ON" 3 "BleWlcmFnSet_3_Reserved";
VAL_ 767 CCDisAdjtVcCmd 0 "CCDisAdjtVcCmd_0_NoRequest" 1 "CCDisAdjtVcCmd_1_Distance1_shortest_" 2 "CCDisAdjtVcCmd_2_Distance2_middle_" 3 "CCDisAdjtVcCmd_3_Distance3_highest_" 4 "CCDisAdjtVcCmd_4_reserved" 5 "CCDisAdjtVcCmd_5_reserved" 6 "CCDisAdjtVcCmd_6_reserved" 7 "CCDisAdjtVcCmd_7_reserved";
VAL_ 767 CCDisDecAndIncVcCmd 0 "CCDisDecAndIncVcCmd_0_NoRequest" 1 "CCDisDecAndIncVcCmd_1_DistanceDecrease" 2 "CCDisDecAndIncVcCmd_2_DistanceIncrease" 3 "CCDisDecAndIncVcCmd_3_reserved";
VAL_ 767 CCSpdDecAndIncVcCmd 0 "CCSpdDecAndIncVcCmd_0_NoRequest" 1 "CCSpdDecAndIncVcCmd_1_SpeedDecrease" 2 "CCSpdDecAndIncVcCmd_2_SpeedIncrease" 3 "CCSpdDecAndIncVcCmd_3_reserved";
VAL_ 767 CCSpdVcCmdSwReq 0 "CCSpdVcCmdSwReq_0_norequest" 1 "CCSpdVcCmdSwReq_1_off" 2 "CCSpdVcCmdSwReq_2_on" 3 "CCSpdVcCmdSwReq_3_reserved";
VAL_ 767 DMSAdoWrnngReq 0 "DMSAdoWrnngReq_0_Norequest" 1 "DMSAdoWrnngReq_1_Off" 2 "DMSAdoWrnngReq_2_On" 3 "DMSAdoWrnngReq_3_reserved";
VAL_ 767 DMSHapticWrnngReq 0 "DMSHapticWrnngReq_0_Norequest" 1 "DMSHapticWrnngReq_1_Off" 2 "DMSHapticWrnngReq_2_On" 3 "DMSHapticWrnngReq_3_reserved";
VAL_ 767 DMSSwReq 0 "DMSSwReq_0_Norequest" 1 "DMSSwReq_1_Off" 2 "DMSSwReq_2_On" 3 "DMSSwReq_3_reserved";
VAL_ 767 DrvrVcCmdADASCtrlReq 0 "DrvrVcCmdADASCtrlReq_0_No_Request" 1 "DrvrVcCmdADASCtrlReq_1_Left_side_lane_change" 2 "DrvrVcCmdADASCtrlReq_2_Right_side_lane_change" 3 "DrvrVcCmdADASCtrlReq_3_Active_SHWA_function" 4 "DrvrVcCmdADASCtrlReq_4_Active_ACC_function" 5 "DrvrVcCmdADASCtrlReq_5_Reserved" 6 "DrvrVcCmdADASCtrlReq_6_Reserved" 7 "DrvrVcCmdADASCtrlReq_7_Reserved";
VAL_ 767 ILCSwReq 0 "ILCSwReq_0_norequest" 1 "ILCSwReq_1_off" 2 "ILCSwReq_2_on" 3 "ILCSwReq_3_reserved";
VAL_ 767 PhnKeyCphrUpdt 0 "PhnKeyCphrUpdt_0_NoOperation" 1 "PhnKeyCphrUpdt_1_Reset" 2 "PhnKeyCphrUpdt_2_Reserved" 3 "PhnKeyCphrUpdt_3_Reserved";
VAL_ 767 PhnKeyRst 0 "PhnKeyRst_0_NoOperation" 1 "PhnKeyRst_1_Reset" 2 "PhnKeyRst_2_Reserved" 3 "PhnKeyRst_3_Reserved";
VAL_ 767 SmtKeyCmftLckSet 0 "SmtKeyCmftLckSet_0_OFF" 1 "SmtKeyCmftLckSet_1_Short_Press_Request" 2 "SmtKeyCmftLckSet_2_Long_Rewss" 3 "SmtKeyCmftLckSet_3_Reserved";
VAL_ 767 SmtKeyCmftUnlckSet 0 "SmtKeyCmftUnlckSet_0_OFF" 1 "SmtKeyCmftUnlckSet_1_Short_Press_Request" 2 "SmtKeyCmftUnlckSet_2_Long_Rewss" 3 "SmtKeyCmftUnlckSet_3_Reserved";
VAL_ 767 SmtKeyWlcmFnSet 0 "SmtKeyWlcmFnSet_0_OFF" 1 "SmtKeyWlcmFnSet_1_ONMode1" 2 "SmtKeyWlcmFnSet_2_ONMode2" 3 "SmtKeyWlcmFnSet_3_Reserved";
VAL_ 762 ACDrvrAirMdSwReq 0 "ACDrvrAirMdSwReq_0_No_request" 1 "ACDrvrAirMdSwReq_1_short_press" 2 "ACDrvrAirMdSwReq_2_long_press";
VAL_ 762 AutoSeatHeatVentR 0 "False" 1 "True";
VAL_ 762 FICMACDrvrTemDecSwReq 0 "FICMACDrvrTemDecSwReq_0_No_request" 1 "FICMACDrvrTemDecSwReq_1_Short_press" 2 "FICMACDrvrTemDecSwReq_2_Long_press";
VAL_ 762 FICMACDrvrTemIncSwReq 0 "FICMACDrvrTemIncSwReq_0_No_request" 1 "FICMACDrvrTemIncSwReq_1_Short_press" 2 "FICMACDrvrTemIncSwReq_2_Long_press";
VAL_ 762 FICMACFrtRrSyncSwReq 0 "FICMACFrtRrSyncSwReq_0_No_request" 1 "FICMACFrtRrSyncSwReq_1_Short_press" 2 "FICMACFrtRrSyncSwReq_2_Long_press" 3 "FICMACFrtRrSyncSwReq_3_Reserved";
VAL_ 762 FICMACPsngAirMdReq 0 "FICMACPsngAirMdReq_0_face" 1 "FICMACPsngAirMdReq_1_face_foot" 2 "FICMACPsngAirMdReq_2_foot" 3 "FICMACPsngAirMdReq_3_foot_defrost" 4 "FICMACPsngAirMdReq_4_defrost" 5 "FICMACPsngAirMdReq_5_face_foot_defrost" 6 "FICMACPsngAirMdReq_6_face_defrost" 7 "FICMACPsngAirMdReq_7_No_Command_air_distribute_mode";
VAL_ 762 FICMACPsngAirMdReqV 0 "Valid" 1 "Invalid";
VAL_ 762 FICMACPsngTemDecSwReq 0 "FICMACPsngTemDecSwReq_0_No_request" 1 "FICMACPsngTemDecSwReq_1_Short_press" 2 "FICMACPsngTemDecSwReq_2_Long_press";
VAL_ 762 FICMACPsngTemIncSwReq 0 "FICMACPsngTemIncSwReq_0_No_Request" 1 "FICMACPsngTemIncSwReq_1_Short_press" 2 "FICMACPsngTemIncSwReq_2_Long_press";
VAL_ 762 PowerModeShutdownRequest 0 "PowerModeShutdownRequest_0_No_Request" 1 "PowerModeShutdownRequest_1_short_press" 2 "PowerModeShutdownRequest_2_long_press";
VAL_ 384 SCREEN_COORD_AX 0 "SCREEN_COORD_AX_0x0_0xFFF_";
VAL_ 384 SCREEN_COORD_AY 0 "SCREEN_COORD_AY_0x0_0xFFF_";
VAL_ 384 SCREEN_COORD_BX 0 "SCREEN_COORD_BX_0x0_0xFFF_";
VAL_ 384 SCREEN_COORD_BY 0 "SCREEN_COORD_BY_0x0_0xFFF_";
VAL_ 384 TOUCH_SCREEN_ACMD 0 "TOUCH_SCREEN_ACMD_No_command" 1 "TOUCH_SCREEN_ACMD_Screen_touched" 2 "TOUCH_SCREEN_ACMD_Screen_hold_reserved_" 3 "TOUCH_SCREEN_ACMD_Screen_release" 4 "TOUCH_SCREEN_ACMD_Reserved_4" 5 "TOUCH_SCREEN_ACMD_Reserved_5" 6 "TOUCH_SCREEN_ACMD_Reserved_6" 7 "TOUCH_SCREEN_ACMD_Reserved_7" 8 "TOUCH_SCREEN_ACMD_Reserved_8" 9 "TOUCH_SCREEN_ACMD_Reserved_9" 10 "TOUCH_SCREEN_ACMD_Reserved_10" 11 "TOUCH_SCREEN_ACMD_Reserved_11" 12 "TOUCH_SCREEN_ACMD_Reserved_12" 13 "TOUCH_SCREEN_ACMD_Reserved_13" 14 "TOUCH_SCREEN_ACMD_Reserved_14" 15 "TOUCH_SCREEN_ACMD_Reserved_15";
VAL_ 384 TOUCH_SCREEN_BCMD 0 "TOUCH_SCREEN_BCMD_No_command" 1 "TOUCH_SCREEN_BCMD_Screen_touched" 2 "TOUCH_SCREEN_BCMD_Screen_hold_reserved_" 3 "TOUCH_SCREEN_BCMD_Screen_release" 4 "TOUCH_SCREEN_BCMD_Reserved1" 5 "TOUCH_SCREEN_BCMD_Reserved2" 6 "TOUCH_SCREEN_BCMD_Reserved3" 7 "TOUCH_SCREEN_BCMD_Reserved4" 8 "TOUCH_SCREEN_BCMD_Reserved5" 9 "TOUCH_SCREEN_BCMD_Reserved6" 10 "TOUCH_SCREEN_BCMD_Reserved7" 11 "TOUCH_SCREEN_BCMD_Reserved8" 12 "TOUCH_SCREEN_BCMD_Reserved9" 13 "TOUCH_SCREEN_BCMD_Reserved10" 14 "TOUCH_SCREEN_BCMD_Reserved11" 15 "TOUCH_SCREEN_BCMD_Reserved12";
VAL_ 384 TOUCH_SCREEN_STATUS 0 "TOUCH_SCREEN_STATUS_No_command" 1 "TOUCH_SCREEN_STATUS_2_Points_Screen_touched" 2 "TOUCH_SCREEN_STATUS_2_reserved" 3 "TOUCH_SCREEN_STATUS_less_than_2_Points_Screen_touched" 4 "TOUCH_SCREEN_STATUS_Reserved1" 5 "TOUCH_SCREEN_STATUS_Reserved2" 6 "TOUCH_SCREEN_STATUS_Reserved3" 7 "TOUCH_SCREEN_STATUS_Reserved4" 8 "TOUCH_SCREEN_STATUS_Reserved5" 9 "TOUCH_SCREEN_STATUS_Reserved6" 10 "TOUCH_SCREEN_STATUS_Reserved7" 11 "TOUCH_SCREEN_STATUS_Reserved8" 12 "TOUCH_SCREEN_STATUS_Reserved9" 13 "TOUCH_SCREEN_STATUS_Reserved10" 14 "TOUCH_SCREEN_STATUS_Reserved11" 15 "TOUCH_SCREEN_STATUS_Reserved12";
VAL_ 994 DrvrSeatAutoRclInh 0 "False" 1 "True";
VAL_ 994 DrvrSeatEasyExitInh 0 "False" 1 "True";
VAL_ 994 FICMStrgWhlHeatSWReq 0 "FICMStrgWhlHeatSWReq_0_Norequest" 1 "FICMStrgWhlHeatSWReq_1_shortpress" 2 "FICMStrgWhlHeatSWReq_2_longpress";
VAL_ 994 FLSeatMassIntstySwReq 0 "FLSeatMassIntstySwReq_0_NoRequest" 1 "FLSeatMassIntstySwReq_1_Intensity1" 2 "FLSeatMassIntstySwReq_2_Intensity2" 3 "FLSeatMassIntstySwReq_3_Intensity3" 4 "FLSeatMassIntstySwReq_4_Reserved" 5 "FLSeatMassIntstySwReq_5_Reserved" 6 "FLSeatMassIntstySwReq_6_Reserved" 7 "FLSeatMassIntstySwReq_7_Reserved";
VAL_ 994 FLSeatMassMdSwReq 0 "FLSeatMassMdSwReq_0_NoReq" 1 "FLSeatMassMdSwReq_1_Mode1" 2 "FLSeatMassMdSwReq_2_Mode2" 3 "FLSeatMassMdSwReq_3_Mode3" 4 "FLSeatMassMdSwReq_4_Mode4" 5 "FLSeatMassMdSwReq_5_Mode5" 6 "FLSeatMassMdSwReq_6_Mode6" 7 "FLSeatMassMdSwReq_7_Mode7" 8 "FLSeatMassMdSwReq_8_Mode8" 9 "FLSeatMassMdSwReq_9_OFF";
VAL_ 994 FRSeatMassIntstySwReq 0 "FRSeatMassIntstySwReq_0_NoReq" 1 "FRSeatMassIntstySwReq_1_Intensity1" 2 "FRSeatMassIntstySwReq_2_Intensity2" 3 "FRSeatMassIntstySwReq_3_Intensity3" 4 "FRSeatMassIntstySwReq_4_reserved" 5 "FRSeatMassIntstySwReq_5_reserved" 6 "FRSeatMassIntstySwReq_6_reserved" 7 "FRSeatMassIntstySwReq_7_reserved";
VAL_ 994 FRSeatMassMdSwReq 0 "FRSeatMassMdSwReq_0_NoReq" 1 "FRSeatMassMdSwReq_1_Mode1" 2 "FRSeatMassMdSwReq_2_Mode2" 3 "FRSeatMassMdSwReq_3_Mode3" 4 "FRSeatMassMdSwReq_4_Mode4" 5 "FRSeatMassMdSwReq_5_Mode5" 6 "FRSeatMassMdSwReq_6_Mode6" 7 "FRSeatMassMdSwReq_7_Mode7" 8 "FRSeatMassMdSwReq_8_Mode8" 9 "FRSeatMassMdSwReq_9_OFF";
VAL_ 580 DrvrPosRclReq 0 "False" 1 "True";
VAL_ 580 OtsdMirPosRclReq 0 "OtsdMirPosRclReq_0_No_request" 1 "OtsdMirPosRclReq_1_Outside_Mirror_Position_Recall_request";
VAL_ 836 UserDefineSlotHandle 0 "UserDefineSlotHandle_0_Default" 1 "UserDefineSlotHandle_1_Drag" 2 "UserDefineSlotHandle_2_Tuning" 3 "UserDefineSlotHandle_3_Place" 4 "UserDefineSlotHandle_4_Stop";
VAL_ 836 UsrConfirmSts 0 "UsrConfirmSts_0_Default" 1 "UsrConfirmSts_1_ParkingConfirm" 2 "UsrConfirmSts_2_OneKeyParkingConfirm" 3 "UsrConfirmSts_3_UserDefineSlotConfirm" 4 "UsrConfirmSts_4_UserDefineSlotReset" 5 "UsrConfirmSts_5_ParkOutSelLeft" 6 "UsrConfirmSts_6_ParkOutSelRight" 7 "UsrConfirmSts_7_ParkOutPosA" 8 "UsrConfirmSts_8_ParkOutPosB" 9 "UsrConfirmSts_9_ParkOutConfirm" 10 "UsrConfirmSts_10_Reserved";
VAL_ 836 UsrDfnSlotDirction 0 "UsrDfnSlotDirction_0_Default" 1 "UsrDfnSlotDirction_1_Left" 2 "UsrDfnSlotDirction_2_Right";
VAL_ 603 ActiveAPAReq 0 "ActiveAPAReq_0_Default" 1 "ActiveAPAReq_1_BTConnected" 2 "ActiveAPAReq_2_InPOI" 3 "ActiveAPAReq_3_Arrived" 4 "ActiveAPAReq_4_InParkArea";
VAL_ 603 Alisysrdy 0 "Alisysrdy_not_ready" 1 "Alisysrdy_ready";
VAL_ 603 AVMDrvnSwReq 0 "AVMDrvnSwReq_0_Norequest" 1 "AVMDrvnSwReq_1_press" 2 "AVMDrvnSwReq_2_Reserved";
VAL_ 603 AVMDspReqRespSts 0 "AVMDspReqRespSts_0_Norequest" 1 "AVMDspReqRespSts_1_ReadytoDisplay" 2 "AVMDspReqRespSts_2_NotReady" 3 "AVMDspReqRespSts_3_AVMOpened" 4 "AVMDspReqRespSts_4_AVMClosed";
VAL_ 603 BrightnessAdjsmt 0 "BrightnessAdjsmt_0_Increase" 1 "BrightnessAdjsmt_1_Discrease" 2 "BrightnessAdjsmt_2_Norequest";
VAL_ 603 BrightnessBar 0 "BrightnessBar_0_0_percent" 1 "BrightnessBar_1_10_percent" 2 "BrightnessBar_2_20_percent" 3 "BrightnessBar_3_30_percent" 4 "BrightnessBar_4_40_percent" 5 "BrightnessBar_5_50_percent" 6 "BrightnessBar_6_60_percent" 7 "BrightnessBar_7_70_percent" 8 "BrightnessBar_8_80_percent" 9 "BrightnessBar_9_90_percent" 10 "BrightnessBar_10_100_percent" 15 "BrightnessBar_15_Norequest";
VAL_ 603 ContrastRatioAdjsmt 0 "ContrastRatioAdjsmt_0_Increase" 1 "ContrastRatioAdjsmt_1_Discrease" 2 "ContrastRatioAdjsmt_2_Norequest";
VAL_ 603 ContrastRatioBar 0 "ContrastRatioBar_0_0_percent" 1 "ContrastRatioBar_1_10_percent" 2 "ContrastRatioBar_2_20_percent" 3 "ContrastRatioBar_3_30_percent" 4 "ContrastRatioBar_4_40_percent" 5 "ContrastRatioBar_5_50_percent" 6 "ContrastRatioBar_6_60_percent" 7 "ContrastRatioBar_7_70_percent" 8 "ContrastRatioBar_8_80_percent" 9 "ContrastRatioBar_9_90_percent" 10 "ContrastRatioBar_10_100_percent" 15 "ContrastRatioBar_15_Norequest";
VAL_ 603 DynmcDrvngTrjctryLnSwReq 0 "DynmcDrvngTrjctryLnSwReq_0_Norequest" 1 "DynmcDrvngTrjctryLnSwReq_1_press" 2 "DynmcDrvngTrjctryLnSwReq_2_Reserved";
VAL_ 603 FICMPwrLftgtSwReq 0 "FICMPwrLftgtSwReq_No_Request" 1 "FICMPwrLftgtSwReq_Active";
VAL_ 603 FrtTmDrvAutVwSwReq 0 "FrtTmDrvAutVwSwReq_0_Norequest" 1 "FrtTmDrvAutVwSwReq_1_press" 2 "FrtTmDrvAutVwSwReq_2_Reserved";
VAL_ 603 HigSpd3DVwSwReq 0 "HigSpd3DVwSwReq_0_Norequest" 1 "HigSpd3DVwSwReq_1_press" 2 "HigSpd3DVwSwReq_2_Reserved";
VAL_ 603 IParkingSw 0 "IParkingSw_0_Off" 1 "IParkingSw_1_On";
VAL_ 603 ObstclAutVwSwReq 0 "ObstclAutVwSwReq_0_Norequest" 1 "ObstclAutVwSwReq_1_press" 2 "ObstclAutVwSwReq_2_Reserved";
VAL_ 603 ObstclMarkSwReq 0 "ObstclMarkSwReq_0_Norequest" 1 "ObstclMarkSwReq_1_press" 2 "ObstclMarkSwReq_2_Reserved";
VAL_ 603 PwrlgftFICMCmd 0 "PwrlgftFICMCmd_0_No_Request" 1 "PwrlgftFICMCmd_1_Open_Request" 2 "PwrlgftFICMCmd_2_Close_Request" 3 "PwrlgftFICMCmd_3_Stop_request";
VAL_ 603 SlientSearchNotifySwReq 0 "SlientSearchNotifySwReq_0_Norequest" 1 "SlientSearchNotifySwReq_1_Request" 2 "SlientSearchNotifySwReq_2_Reserved";
VAL_ 603 TurnngAutVwSwReq 0 "TurnngAutVwSwReq_0_Norequest" 1 "TurnngAutVwSwReq_1_press" 2 "TurnngAutVwSwReq_2_Reserved";
VAL_ 603 UsrDfnSw 0 "UsrDfnSw_0_Off" 1 "UsrDfnSw_1_ParallelSlot" 2 "UsrDfnSw_2_VerticalSlot" 3 "UsrDfnSw_3_ObliqueSlot" 4 "UsrDfnSw_4_StereoSlot" 5 "UsrDfnSw_5_QuitRequest";
VAL_ 850 DrvrSelAPAParkngMd 0 "DrvrSelAPAParkngMd_No_select" 1 "DrvrSelAPAParkngMd_Select_parallel_parking" 2 "DrvrSelAPAParkngMd_Select_perpendicular_parking" 3 "DrvrSelAPAParkngMd_Select_park_in" 4 "DrvrSelAPAParkngMd_Select_park_out" 5 "DrvrSelAPAParkngMd_Reserved1" 6 "DrvrSelAPAParkngMd_Reserved2" 7 "DrvrSelAPAParkngMd_Reserved3";
VAL_ 850 DrvrSelAPASlotBearng 0 "DrvrSelAPASlotBearng_No_select" 1 "DrvrSelAPASlotBearng_Select_Left_slot" 2 "DrvrSelAPASlotBearng_Select_Right_slot" 3 "DrvrSelAPASlotBearng_Reserved";
VAL_ 850 FICMAPAQuitReq 0 "False" 1 "True";
VAL_ 850 FICMAPASwReq 0 "FICMAPASwReq_0_Default" 1 "FICMAPASwReq_1_ParkingIn" 2 "FICMAPASwReq_2_ParkingOutToLeft" 3 "FICMAPASwReq_3_ParkingOutToRight" 4 "FICMAPASwReq_4_ParkOut" 5 "FICMAPASwReq_5_Front_Left_Cross" 6 "FICMAPASwReq_6_Front_Left_Parallel" 7 "FICMAPASwReq_7_Front_Out" 8 "FICMAPASwReq_8_Front_Right_Cross" 9 "FICMAPASwReq_9_Front_Right_Parallel" 10 "FICMAPASwReq_10_Back_Out" 11 "FICMAPASwReq_11_Back_Left_Cross" 12 "FICMAPASwReq_12_Back_Right_Cross" 13 "FICMAPASwReq_13_Reserved" 14 "FICMAPASwReq_14_Reserved" 15 "FICMAPASwReq_15_Reserved";
VAL_ 850 FICMPLCRtCoverSwReq 0 "FICMPLCRtCoverSwReq_0_Initial" 1 "FICMPLCRtCoverSwReq_1_NO" 2 "FICMPLCRtCoverSwReq_2_YES";
VAL_ 850 LADSUsrConfirmSts 0 "LADSUsrConfirmSts_0_Default" 1 "LADSUsrConfirmSts_1_ParkingConfirm" 2 "LADSUsrConfirmSts_2_OneKeyParkingConfirm" 3 "LADSUsrConfirmSts_3_RecoveryParking" 4 "LADSUsrConfirmSts_4_PendingRecovery";
VAL_ 850 LCRSwReq 0 "LCRSwReq_0_no_request" 1 "LCRSwReq_1_off" 2 "LCRSwReq_2_on" 3 "LCRSwReq_3_reserved";
VAL_ 850 MUWSwReq 0 "MUWSwReq_0_Norequest" 1 "MUWSwReq_1_press" 2 "MUWSwReq_2_Reserved";
VAL_ 833 ClstrDspdGear 0 "ClstrDspdGear_0_Blank" 1 "ClstrDspdGear_1_1" 2 "ClstrDspdGear_2_2" 3 "ClstrDspdGear_3_3" 4 "ClstrDspdGear_4_4" 5 "ClstrDspdGear_5_5" 6 "ClstrDspdGear_6_6" 7 "ClstrDspdGear_7_7" 8 "ClstrDspdGear_8_8" 9 "ClstrDspdGear_9_P" 10 "ClstrDspdGear_10_R" 11 "ClstrDspdGear_11_N" 12 "ClstrDspdGear_12_D" 13 "ClstrDspdGear_13_E" 14 "ClstrDspdGear_14_S" 15 "ClstrDspdGear_15_EP";
VAL_ 843 ARSSwReq 0 "ARSSwReq_0_No_Request" 1 "ARSSwReq_1_Press";
VAL_ 843 ELSDCustSetngReq 0 "ELSDCustSetngReq_0_Unavailable" 1 "ELSDCustSetngReq_1_EcoMode" 2 "ELSDCustSetngReq_2_NormalMode" 3 "ELSDCustSetngReq_3_SportMode";
VAL_ 843 ELSDCustSetngReqV 0 "ELSDCustSetngReqV_0_Valid" 1 "ELSDCustSetngReqV_1_Invalid";
VAL_ 843 ExhDeftMdReqForXMd 0 "ExhDeftMdReqForXMd_0_EAV_silence_mode" 1 "ExhDeftMdReqForXMd_1_EAV_normal_sporty_mode" 2 "ExhDeftMdReqForXMd_2_EAV_super_sporty_mode" 3 "ExhDeftMdReqForXMd_3_EAV_customer_sporty_mode";
VAL_ 843 ExhSptyCustrMdTrigEnSpd 0 "ExhSptyCustrMdTrigEnSpd_0_0_rpm" 1 "ExhSptyCustrMdTrigEnSpd_1_500_rpm" 2 "ExhSptyCustrMdTrigEnSpd_2_1000_rpm" 3 "ExhSptyCustrMdTrigEnSpd_3_1500_rpm" 4 "ExhSptyCustrMdTrigEnSpd_4_2000_rpm" 5 "ExhSptyCustrMdTrigEnSpd_4_2500_rpm" 6 "ExhSptyCustrMdTrigEnSpd_6_3000_rpm" 7 "ExhSptyCustrMdTrigEnSpd_7_3500_rpm" 8 "ExhSptyCustrMdTrigEnSpd_8_4000_rpm" 9 "ExhSptyCustrMdTrigEnSpd_9_4500_rpm" 10 "ExhSptyCustrMdTrigEnSpd_10_5000_rpm" 11 "ExhSptyCustrMdTrigEnSpd_11_5500_rpm" 12 "ExhSptyCustrMdTrigEnSpd_12_6000_rpm";
VAL_ 843 ExhSptyCustrMdTrigPdlPos 0 "ExhSptyCustrMdTrigPdlPos_0_0percent_Pedal_Position" 1 "ExhSptyCustrMdTrigPdlPos_1_10percent_Pedal_Position" 2 "ExhSptyCustrMdTrigPdlPos_2_20percent_Pedal_Position" 3 "ExhSptyCustrMdTrigPdlPos_3_30percent_Pedal_Position" 4 "ExhSptyCustrMdTrigPdlPos_4_40percent_Pedal_Position" 5 "ExhSptyCustrMdTrigPdlPos_5_50percent_Pedal_Position" 6 "ExhSptyCustrMdTrigPdlPos_6_60percent_Pedal_Position" 7 "ExhSptyCustrMdTrigPdlPos_7_70percent_Pedal_Position" 8 "ExhSptyCustrMdTrigPdlPos_8_80percent_Pedal_Position" 9 "ExhSptyCustrMdTrigPdlPos_9_90percent_Pedal_Position" 10 "ExhSptyCustrMdTrigPdlPos_10_100percent_Pedal_Position";
VAL_ 843 ExhSptyMdReq 0 "ExhSptyMdReq_0_EAV_silence_mode" 1 "ExhSptyMdReq_1_EAV_normal_sporty_mode" 2 "ExhSptyMdReq_2_EAV_super_sporty_mode" 3 "ExhSptyMdReq_3_EAV_customer_sporty_mode";
VAL_ 843 SCMCustSetngReq 0 "SCMCustSetngReq_0_Unavailable" 1 "SCMCustSetngReq_1_EcoMode" 2 "SCMCustSetngReq_2_NormalMode" 3 "SCMCustSetngReq_3_SportMode";
VAL_ 843 SCMCustSetngReqV 0 "SCMCustSetngReqV_0_Valid" 1 "SCMCustSetngReqV_1_Invalid";
VAL_ 843 SCSCustSetngReq 0 "SCSCustSetngReq_0_No_Request" 1 "SCSCustSetngReq_1_All_On" 2 "SCSCustSetngReq_2_TCS_Off" 3 "SCSCustSetngReq_3_All_Off";
VAL_ 843 SCSCustSetngReqV 0 "SCSCustSetngReqV_0_Valid" 1 "SCSCustSetngReqV_1_Invalid";
VAL_ 868 SusSprMdEnbSw 0 "SusSprMdEnbSw_0_Function_Disable" 1 "SusSprMdEnbSw_1_Suspension_Super_Mode_Enable";
VAL_ 868 SusSprMdMmry 0 "SusSprMdMmry_0_Function_Disable" 1 "SusSprMdMmry_1_Suspension_Super_Mode_Memory_1" 2 "SusSprMdMmry_2_Suspension_Super_Mode_Memory_2" 3 "SusSprMdMmry_3_Suspension_Super_Mode_Memory_3";
VAL_ 520 ICMDMSSts 0 "ICMDMSSts_0_Off" 1 "ICMDMSSts_1_Standby" 2 "ICMDMSSts_2_Active" 3 "ICMDMSSts_3_Camera_Blocked" 4 "ICMDMSSts_4_System_temporary_unavailable" 5 "ICMDMSSts_5_Service_required" 6 "ICMDMSSts_6_Initialization" 7 "ICMDMSSts_7_Reserved";
VAL_ 520 ICMDMSVbnLvlReq 0 "ICMDMSVbnLvlReq_0_No_request" 1 "ICMDMSVbnLvlReq_1_Low" 2 "ICMDMSVbnLvlReq_2_Middle" 3 "ICMDMSVbnLvlReq_3_High";
VAL_ 520 ICMDrvrAbnormBehvor 0 "ICMDrvrAbnormBehvor_0_Unknown" 1 "ICMDrvrAbnormBehvor_1_No_abnormal_behaviour" 2 "ICMDrvrAbnormBehvor_2_Telephone_calls" 3 "ICMDrvrAbnormBehvor_3_Smoking" 4 "ICMDrvrAbnormBehvor_4_Drinking_water" 5 "ICMDrvrAbnormBehvor_5_Eating" 6 "ICMDrvrAbnormBehvor_6_Reserved" 7 "ICMDrvrAbnormBehvor_7_Reserved" 8 "ICMDrvrAbnormBehvor_8_Reserved" 9 "ICMDrvrAbnormBehvor_9_Reserved" 10 "ICMDrvrAbnormBehvor_10_Reserved" 11 "ICMDrvrAbnormBehvor_11_Reserved" 12 "ICMDrvrAbnormBehvor_12_Reserved" 13 "ICMDrvrAbnormBehvor_13_Reserved" 14 "ICMDrvrAbnormBehvor_14_Reserved" 15 "ICMDrvrAbnormBehvor_15_Reserved";
VAL_ 520 ICMDrvrDstcnSts 0 "ICMDrvrDstcnSts_0_Unknown" 1 "ICMDrvrDstcnSts_1_No_distraction" 2 "ICMDrvrDstcnSts_2_Low_level_distraction" 3 "ICMDrvrDstcnSts_3_Middle_level_distraction" 4 "ICMDrvrDstcnSts_4_High_level_distraction" 5 "ICMDrvrDstcnSts_5_Reserve" 6 "ICMDrvrDstcnSts_6_Reserve" 7 "ICMDrvrDstcnSts_7_Reserve";
VAL_ 520 ICMDrvrFtgLvl 0 "ICMDrvrFtgLvl_0_Unknown" 1 "ICMDrvrFtgLvl_1_No_Drowsiness" 2 "ICMDrvrFtgLvl_2_Low_level_Drowsiness" 3 "ICMDrvrFtgLvl_3_Middle_level_Drowsiness" 4 "ICMDrvrFtgLvl_4_High_level_Drowsiness" 5 "ICMDrvrFtgLvl_5_Reserve" 6 "ICMDrvrFtgLvl_6_Reserve" 7 "ICMDrvrFtgLvl_7_Reserve";
VAL_ 520 ICMDrvrGazeRgn 0 "ICMDrvrGazeRgn_0_init_Unknown" 1 "ICMDrvrGazeRgn_1_Driver_Side_of_Windscreen" 2 "ICMDrvrGazeRgn_2_Copilot_Side_of_Windscreen" 3 "ICMDrvrGazeRgn_3_Left_Rear_View_Mirror" 4 "ICMDrvrGazeRgn_4_Right_Rear_View_Mirror" 5 "ICMDrvrGazeRgn_5_Left_Side_Window" 6 "ICMDrvrGazeRgn_6_Right_Side_Window" 7 "ICMDrvrGazeRgn_7_Central_Rear_View_Mirror" 8 "ICMDrvrGazeRgn_8_Central_driver_s_Instrument_Cluster_speed_gauge_etc" 9 "ICMDrvrGazeRgn_9_Head_up_display" 10 "ICMDrvrGazeRgn_10_Navigation_Display" 11 "ICMDrvrGazeRgn_11_Middle_Instrument_Cluster_A_C_radio_etc" 12 "ICMDrvrGazeRgn_12_Steering_Wheel_e_g_button_area" 13 "ICMDrvrGazeRgn_13_Left_Seat_Foot_Area" 14 "ICMDrvrGazeRgn_14_Right_Seat_Foot_Area_Workbench" 15 "ICMDrvrGazeRgn_15_Left_Side_door_area" 16 "ICMDrvrGazeRgn_16_Right_Side_door_area";
VAL_ 520 ICMDrvrPrst 0 "ICMDrvrPrst_0_Unknown" 1 "ICMDrvrPrst_1_Driver_Not_Presence" 2 "ICMDrvrPrst_2_Driver_Presence" 3 "ICMDrvrPrst_3_Reserve" 4 "ICMDrvrPrst_4_Reserve" 5 "ICMDrvrPrst_5_Reserve" 6 "ICMDrvrPrst_6_Reserve" 7 "ICMDrvrPrst_7_Reserve";
VAL_ 520 ICMEyeOnRoad 0 "ICMEyeOnRoad_0_Unavailable" 1 "ICMEyeOnRoad_1_Eyes_On_Road" 2 "ICMEyeOnRoad_2_Eyes_Off_Road_driving_task_related_region" 3 "ICMEyeOnRoad_3_Eyes_Off_Road_non_driving_task_related_region";
VAL_ 520 ICMSpfngDet 0 "ICMSpfngDet_0_Unknown" 1 "ICMSpfngDet_1_Not_Detected" 2 "ICMSpfngDet_2_Detected" 3 "ICMSpfngDet_3_Reserve";
VAL_ 97 DsttnDist 65535 "DsttnDist_65535_invalid_value";
VAL_ 97 DsttnHour 63 "DsttnHour_63_invalid_value";
VAL_ 97 DsttnMinute 60 "DsttnMinute_60_invalid_value" 61 "DsttnMinute_61_invalid_value" 62 "DsttnMinute_62_invalid_value" 63 "DsttnMinute_63_invalid_value";
VAL_ 97 DsttnUnit 0 "DsttnUnit_0_m" 1 "DsttnUnit_1_100_m";
VAL_ 97 HudPhnSts 0 "HudPhnSts_0_Dialing" 1 "HudPhnSts_1_on_the_phone" 2 "HudPhnSts_2_incoming_call" 3 "HudPhnSts_3_not_answer" 4 "HudPhnSts_4_refused" 5 "HudPhnSts_5_unable_get_through" 6 "HudPhnSts_6_no_call" 7 "HudPhnSts_7_answer" 8 "HudPhnSts_8_hang_up";
VAL_ 79 AmbcSetngReq 0 "AmbcSetngReq_0_Off" 1 "AmbcSetngReq_1_MusicHall" 2 "AmbcSetngReq_2_LiveMode" 3 "AmbcSetngReq_3_CinemaMode";
VAL_ 79 AmbcSetngReqV 0 "AmbcSetngReqV_0_Valid" 1 "AmbcSetngReqV_1_Invalid";
VAL_ 79 BalcSetngReq 0 "BalcSetngReq_0_Level_negative7" 1 "BalcSetngReq_1_Level_negative6" 2 "BalcSetngReq_2_Level_negative5" 3 "BalcSetngReq_3_Level_negative4" 4 "BalcSetngReq_4_Level_negative3" 5 "BalcSetngReq_5_Level_negative2" 6 "BalcSetngReq_6_Level_negative1" 7 "BalcSetngReq_7_Level0" 8 "BalcSetngReq_8_Level1" 9 "BalcSetngReq_9_Level2" 10 "BalcSetngReq_10_Level3" 11 "BalcSetngReq_11_Level4" 12 "BalcSetngReq_12_Level5" 13 "BalcSetngReq_13_Level6" 14 "BalcSetngReq_14_Level7" 15 "BalcSetngReq_15_Reserved";
VAL_ 79 BalcSetngReqV 0 "BalcSetngReqV_0_Valid" 1 "BalcSetngReqV_1_Invalid";
VAL_ 79 ChmA 0 "False" 1 "True";
VAL_ 79 ChmSndVolmStepReq 0 "ChmSndVolmStepReq_0_Reserved" 1 "ChmSndVolmStepReq_1_Step2" 2 "ChmSndVolmStepReq_2_Step3" 3 "ChmSndVolmStepReq_3_Step4" 4 "ChmSndVolmStepReq_4_Step5" 5 "ChmSndVolmStepReq_5_Step6" 6 "ChmSndVolmStepReq_6_Step7" 7 "ChmSndVolmStepReq_7_Step8" 8 "ChmSndVolmStepReq_8_Step9" 9 "ChmSndVolmStepReq_9_Step10" 10 "ChmSndVolmStepReq_10_Step11" 11 "ChmSndVolmStepReq_11_Step12" 12 "ChmSndVolmStepReq_12_Step13" 13 "ChmSndVolmStepReq_13_Step14" 14 "ChmSndVolmStepReq_14_Step15" 15 "ChmSndVolmStepReq_15_Step16";
VAL_ 79 ChmSndVolmStepReqV 0 "ChmSndVolmStepReqV_0_Valid" 1 "ChmSndVolmStepReqV_1_Invalid";
VAL_ 79 FdrSetngReq 0 "FdrSetngReq_0_Level_negative7" 1 "FdrSetngReq_1_Level_negative6" 2 "FdrSetngReq_2_Level_negative5" 3 "FdrSetngReq_3_Level_negative4" 4 "FdrSetngReq_4_Level_negative3" 5 "FdrSetngReq_5_Level_negative2" 6 "FdrSetngReq_6_Level_negative1" 7 "FdrSetngReq_7_Level0" 8 "FdrSetngReq_8_Level1" 9 "FdrSetngReq_9_Level2" 10 "FdrSetngReq_10_Level3" 11 "FdrSetngReq_11_Level4" 12 "FdrSetngReq_12_Level5" 13 "FdrSetngReq_13_Level6" 14 "FdrSetngReq_14_Level7" 15 "FdrSetngReq_15_Reserved";
VAL_ 79 FdrSetngReqV 0 "FdrSetngReqV_0_Valid" 1 "FdrSetngReqV_1_Invalid";
VAL_ 79 MdaSndVolmStepReq 0 "MdaSndVolmStepReq_0_Step0" 1 "MdaSndVolmStepReq_1_Step1" 2 "MdaSndVolmStepReq_2_Step2" 3 "MdaSndVolmStepReq_3_Step3" 4 "MdaSndVolmStepReq_4_Step4" 5 "MdaSndVolmStepReq_5_Step5" 6 "MdaSndVolmStepReq_6_Step6" 7 "MdaSndVolmStepReq_7_Step7" 8 "MdaSndVolmStepReq_8_Step8" 9 "MdaSndVolmStepReq_9_Step9" 10 "MdaSndVolmStepReq_10_Step10" 11 "MdaSndVolmStepReq_11_Step11" 12 "MdaSndVolmStepReq_12_Step12" 13 "MdaSndVolmStepReq_13_Step13" 14 "MdaSndVolmStepReq_14_Step14" 15 "MdaSndVolmStepReq_15_Step15" 16 "MdaSndVolmStepReq_16_Step16" 17 "MdaSndVolmStepReq_17_Step17" 18 "MdaSndVolmStepReq_18_Step18" 19 "MdaSndVolmStepReq_19_Step19" 20 "MdaSndVolmStepReq_20_Step20" 21 "MdaSndVolmStepReq_21_Step21" 22 "MdaSndVolmStepReq_22_Step22" 23 "MdaSndVolmStepReq_23_Step23" 24 "MdaSndVolmStepReq_24_Step24" 25 "MdaSndVolmStepReq_25_Step25" 26 "MdaSndVolmStepReq_26_Step26" 27 "MdaSndVolmStepReq_27_Step27" 28 "MdaSndVolmStepReq_28_Step28" 29 "MdaSndVolmStepReq_29_Step29" 30 "MdaSndVolmStepReq_30_Step30" 31 "MdaSndVolmStepReq_31_Step31" 32 "MdaSndVolmStepReq_32_Step32";
VAL_ 79 MdaSndVolmStepReqV 0 "MdaSndVolmStepReqV_0_Valid" 1 "MdaSndVolmStepReqV_1_Invalid";
VAL_ 79 NavSndVolmStepReq 0 "NavSndVolmStepReq_0_Step0" 1 "NavSndVolmStepReq_1_Step1" 2 "NavSndVolmStepReq_2_Step2" 3 "NavSndVolmStepReq_3_Step3" 4 "NavSndVolmStepReq_4_Step4" 5 "NavSndVolmStepReq_5_Step5" 6 "NavSndVolmStepReq_6_Step6" 7 "NavSndVolmStepReq_7_Step7" 8 "NavSndVolmStepReq_8_Step8" 9 "NavSndVolmStepReq_9_Step9" 10 "NavSndVolmStepReq_10_Step10" 11 "NavSndVolmStepReq_11_Step11" 12 "NavSndVolmStepReq_12_Step12" 13 "NavSndVolmStepReq_13_Step13" 14 "NavSndVolmStepReq_14_Step14" 15 "NavSndVolmStepReq_15_Step15" 16 "NavSndVolmStepReq_16_Step16";
VAL_ 79 NavSndVolmStepReqV 0 "NavSndVolmStepReqV_0_Valid" 1 "NavSndVolmStepReqV_1_Invalid";
VAL_ 79 PhnCallSndVolmStepReq 0 "PhnCallSndVolmStepReq_0_Step0" 1 "PhnCallSndVolmStepReq_1_Step1" 2 "PhnCallSndVolmStepReq_2_Step2" 3 "PhnCallSndVolmStepReq_3_Step3" 4 "PhnCallSndVolmStepReq_4_Step4" 5 "PhnCallSndVolmStepReq_5_Step5" 6 "PhnCallSndVolmStepReq_6_Step6" 7 "PhnCallSndVolmStepReq_7_Step7" 8 "PhnCallSndVolmStepReq_8_Step8" 9 "PhnCallSndVolmStepReq_9_Step9" 10 "PhnCallSndVolmStepReq_10_Step10" 11 "PhnCallSndVolmStepReq_11_Step11" 12 "PhnCallSndVolmStepReq_12_Step12" 13 "PhnCallSndVolmStepReq_13_Step13" 14 "PhnCallSndVolmStepReq_14_Step14" 15 "PhnCallSndVolmStepReq_15_Step15" 16 "PhnCallSndVolmStepReq_16_Step16" 17 "PhnCallSndVolmStepReq_17_Step17" 18 "PhnCallSndVolmStepReq_18_Step18" 19 "PhnCallSndVolmStepReq_19_Step19" 20 "PhnCallSndVolmStepReq_20_Step20" 21 "PhnCallSndVolmStepReq_21_Step21" 22 "PhnCallSndVolmStepReq_22_Step22" 23 "PhnCallSndVolmStepReq_23_Step23" 24 "PhnCallSndVolmStepReq_24_Step24" 25 "PhnCallSndVolmStepReq_25_Step25" 26 "PhnCallSndVolmStepReq_26_Step26" 27 "PhnCallSndVolmStepReq_27_Step27" 28 "PhnCallSndVolmStepReq_28_Step28" 29 "PhnCallSndVolmStepReq_29_Step29" 30 "PhnCallSndVolmStepReq_30_Step30" 31 "PhnCallSndVolmStepReq_31_Step31" 32 "PhnCallSndVolmStepReq_32_Step32";
VAL_ 79 PhnCallSndVolmStepReqV 0 "PhnCallSndVolmStepReqV_0_Valid" 1 "PhnCallSndVolmStepReqV_1_Invalid";
VAL_ 79 SpdDpntAutocVolmReq 0 "SpdDpntAutocVolmReq_0_Off" 1 "SpdDpntAutocVolmReq_1_Low" 2 "SpdDpntAutocVolmReq_2_Middle" 3 "SpdDpntAutocVolmReq_3_High";
VAL_ 79 SpdDpntAutocVolmReqV 0 "SpdDpntAutocVolmReqV_0_Valid" 1 "SpdDpntAutocVolmReqV_1_Invalid";
VAL_ 79 ThreeDimnSndFldSetngReq 0 "ThreeDimnSndFldSetngReq_0_Off" 1 "ThreeDimnSndFldSetngReq_1_AllPassenger" 2 "ThreeDimnSndFldSetngReq_2_Driver" 3 "ThreeDimnSndFldSetngReq_3_VIPRearSeat" 4 "ThreeDimnSndFldSetngReq_4_Centerpoint" 5 "ThreeDimnSndFldSetngReq_5_StereoSurrouding";
VAL_ 79 ThreeDimnSndFldSetngReqV 0 "ThreeDimnSndFldSetngReqV_0_Valid" 1 "ThreeDimnSndFldSetngReqV_1_Invalid";
VAL_ 79 VcItatnSndVolmStepReq 0 "VcItatnSndVolmStepReq_0_Step0" 1 "VcItatnSndVolmStepReq_1_Step1" 2 "VcItatnSndVolmStepReq_2_Step2" 3 "VcItatnSndVolmStepReq_3_Step3" 4 "VcItatnSndVolmStepReq_4_Step4" 5 "VcItatnSndVolmStepReq_5_Step5" 6 "VcItatnSndVolmStepReq_6_Step6" 7 "VcItatnSndVolmStepReq_7_Step7" 8 "VcItatnSndVolmStepReq_8_Step8" 9 "VcItatnSndVolmStepReq_9_Step9" 10 "VcItatnSndVolmStepReq_10_Step10" 11 "VcItatnSndVolmStepReq_11_Step11" 12 "VcItatnSndVolmStepReq_12_Step12" 13 "VcItatnSndVolmStepReq_13_Step13" 14 "VcItatnSndVolmStepReq_14_Step14" 15 "VcItatnSndVolmStepReq_15_Step15" 16 "VcItatnSndVolmStepReq_16_Step16";
VAL_ 79 VcItatnSndVolmStepReqV 0 "VcItatnSndVolmStepReqV_0_Valid" 1 "VcItatnSndVolmStepReqV_1_Invalid";
VAL_ 48 AllMuteReq 0 "AllMuteReq_0_Unmute" 1 "AllMuteReq_1_Mute";
VAL_ 48 AMPASndWaveSelReq 0 "AMPASndWaveSelReq_0_Sound_1" 1 "AMPASndWaveSelReq_1_Sound_2" 2 "AMPASndWaveSelReq_2_Sound_3" 3 "AMPASndWaveSelReq_3_Sound_4" 4 "AMPASndWaveSelReq_4_Sound_5" 5 "AMPASndWaveSelReq_5_Sound_6" 6 "AMPASndWaveSelReq_6_Reserved" 7 "AMPASndWaveSelReq_7_Reserved";
VAL_ 48 AMPASndWaveSelReqV 0 "AMPASndWaveSelReqV_0_Valid" 1 "AMPASndWaveSelReqV_1_Invalid";
VAL_ 48 AMPASndWaveSwReq 0 "False" 1 "True";
VAL_ 48 AMPASndWaveSwReqV 0 "AMPASndWaveSwReqV_0_Valid" 1 "AMPASndWaveSwReqV_1_Invalid";
VAL_ 48 AMPASndWaveVolmSwReq 0 "AMPASndWaveVolmSwReq_0_Level" 1 "AMPASndWaveVolmSwReq_1_Level" 2 "AMPASndWaveVolmSwReq_2_Level" 3 "AMPASndWaveVolmSwReq_3_Level" 4 "AMPASndWaveVolmSwReq_4_Level" 5 "AMPASndWaveVolmSwReq_5_Level" 6 "AMPASndWaveVolmSwReq_6_Level" 7 "AMPASndWaveVolmSwReq_7_Level" 8 "AMPASndWaveVolmSwReq_8_Level" 9 "AMPASndWaveVolmSwReq_9_Level" 10 "AMPASndWaveVolmSwReq_10_Level" 11 "AMPASndWaveVolmSwReq_B_Reserved" 12 "AMPASndWaveVolmSwReq_C_Reserved" 13 "AMPASndWaveVolmSwReq_D_Reserved" 14 "AMPASndWaveVolmSwReq_E_Reserved" 15 "AMPASndWaveVolmSwReq_F_Reserved";
VAL_ 48 AMPASndWaveVolmSwReqV 0 "AMPASndWaveVolmSwReqV_0_Valid" 1 "AMPASndWaveVolmSwReqV_1_Invalid";
VAL_ 48 ANCOnOffReq 0 "False" 1 "True";
VAL_ 48 ANCOnOffReqV 0 "ANCOnOffReq_0_Valid" 1 "ANCOnOffReq_1_Invalid";
VAL_ 48 BassReq 0 "BassReq_0_negative7dB" 1 "BassReq_1_negative6dB" 2 "BassReq_2_negative5dB" 3 "BassReq_3_negative4dB" 4 "BassReq_4_negative3dB" 5 "BassReq_5_negative2dB" 6 "BassReq_6_negative1dB" 7 "BassReq_7_0dB" 8 "BassReq_8_1dB" 9 "BassReq_9_2dB" 10 "BassReq_10_3dB" 11 "BassReq_11_4dB" 12 "BassReq_12_5dB" 13 "BassReq_13_6dB" 14 "BassReq_14_7dB" 15 "BassReq_15_Reserved";
VAL_ 48 BassReqV 0 "BassReqV_0_Valid" 1 "BassReqV_1_Invalid";
VAL_ 48 CmprdSndQultRstrnReq 0 "CmprdSndQultRstrnReq_0_Off" 1 "CmprdSndQultRstrnReq_1_On";
VAL_ 48 ICMChmCmdSndLoctnFL 0 "False" 1 "True";
VAL_ 48 ICMChmCmdSndLoctnFR 0 "False" 1 "True";
VAL_ 48 ICMChmCmdSndLoctnRL 0 "False" 1 "True";
VAL_ 48 ICMChmCmdSndLoctnRR 0 "False" 1 "True";
VAL_ 48 LdnsSetngSoftSw 0 "LdnsSetngSoftSw_0_Off" 1 "LdnsSetngSoftSw_1_On";
VAL_ 48 MdaA 0 "MdaA_0_Disable" 1 "MdaA_1_Enable";
VAL_ 48 MdaMuteReq 0 "MdaMuteReq_0_Unmute" 1 "MdaMuteReq_1_Mute";
VAL_ 48 MedReq 0 "MedReq_0_negetive7dB" 1 "MedReq_1_negetive6dB" 2 "MedReq_2_negetive5dB" 3 "MedReq_3_negetive4dB" 4 "MedReq_4_negetive3dB" 5 "MedReq_5_negetive2dB" 6 "MedReq_6_negetive1dB" 7 "MedReq_7_0dB" 8 "MedReq_8_1dB" 9 "MedReq_9_2dB" 10 "MedReq_10_3dB" 11 "MedReq_11_4dB" 12 "MedReq_12_5dB" 13 "MedReq_13_6dB" 14 "MedReq_14_7dB" 15 "MedReq_15_Reserved";
VAL_ 48 MedReqV 0 "MedReqV_0_Valid" 1 "MedReqV_1_Invalid";
VAL_ 48 NavA 0 "NavA_0_Disable" 1 "NavA_1_Enable";
VAL_ 48 NotfnA 0 "NotfnA_0_Disable" 1 "NotfnA_1_Enable";
VAL_ 48 PhnA 0 "PhnA_0_Disable" 1 "PhnA_1_Enable";
VAL_ 48 TelphoComLoctn 0 "TelphoComLoctn_0_Null" 1 "TelphoComLoctn_1_Driver" 2 "TelphoComLoctn_2_Passenger" 3 "TelphoComLoctn_3_RearLeft" 4 "TelphoComLoctn_4_RearRight" 5 "TelphoComLoctn_5_AllPassengers";
VAL_ 48 TrblReq 0 "TrblReq_0_negetive7dB" 1 "TrblReq_1_negetive6dB" 2 "TrblReq_2_negetive5dB" 3 "TrblReq_3_negetive4dB" 4 "TrblReq_4_negetive3dB" 5 "TrblReq_5_negetive2dB" 6 "TrblReq_6_negetive1dB" 7 "TrblReq_7_0dB" 8 "TrblReq_8_1dB" 9 "TrblReq_9_2dB" 10 "TrblReq_10_3dB" 11 "TrblReq_11_4dB" 12 "TrblReq_12_5dB" 13 "TrblReq_13_6dB" 14 "TrblReq_14_7dB" 15 "TrblReq_15_Reserved";
VAL_ 48 TrblReqV 0 "TrblReqV_0_Valid" 1 "TrblReqV_1_Invalid";
VAL_ 48 VcItatnA 0 "VcItatnA_0_Disable" 1 "VcItatnA_1_Enable";
VAL_ 48 VcItatnSndLoctn 0 "VcItatnSndLoctn_0_Null" 1 "VcItatnSndLoctn_1_Driver" 2 "VcItatnSndLoctn_2_Passenger" 3 "VcItatnSndLoctn_3_RearLeft" 4 "VcItatnSndLoctn_4_RearRight" 5 "VcItatnSndLoctn_5_AllPassengers";
SIG_GROUP_ 1547 DIAG_PhysResp_VKR 1 : DiagnosticRespVKR;
SIG_GROUP_ 931 FICM_CFCAN_FrP07 1 : FICM_100ms_PDU07_CRC FICM_100ms_PDU07_RC FICM_100ms_PDU07_Reserve01 FICMEcoDrvngSwA FICMEcoDrvngSwAV FICMPosngSysDircn LDWLKASwReq NavSpdLmtTyp NavSpdLmtVal NavSpdLmtValSts NavSpdLmtValUnit PtCustSetngReq PtCustSetngReqV SpdAstMdFICM SpdAstMdFICMV StrgCustSetngReq StrgCustSetngReqV TrCustSetngReq TrCustSetngReqV;
SIG_GROUP_ 520 ICM_050ms_PDU14 1 : ICM_050ms_PDU14_CRC ICM_050ms_PDU14_RC ICM_050ms_PDU14_Reserve01 ICM_050ms_PDU14_Reserve02 ICM_050ms_PDU14_Reserve03 ICMDMSSts ICMDMSVbnLvlReq ICMDrvrAbnormBehvor ICMDrvrDstcnSts ICMDrvrFtgLvl ICMDrvrGazeRgn ICMDrvrPrst ICMEyeOnRoad ICMSpfngDet;
